VERSION "HNNBNNNYNNNNNNNNNNNNNNNNNNNNNNNNNNNNNNNNNN/4/%%%/4/'%**4NNN///"

NS_ :

BS_:

BU_: BAP_Tester BedienDisp_vo BedienSG_hi CGS DDA Gateway Gateway_PAG GurtMikrofon OTA_FC ZR_High ZR_LIMU ZR_MIB_TOP_ab_Gen3 ZR_Standard

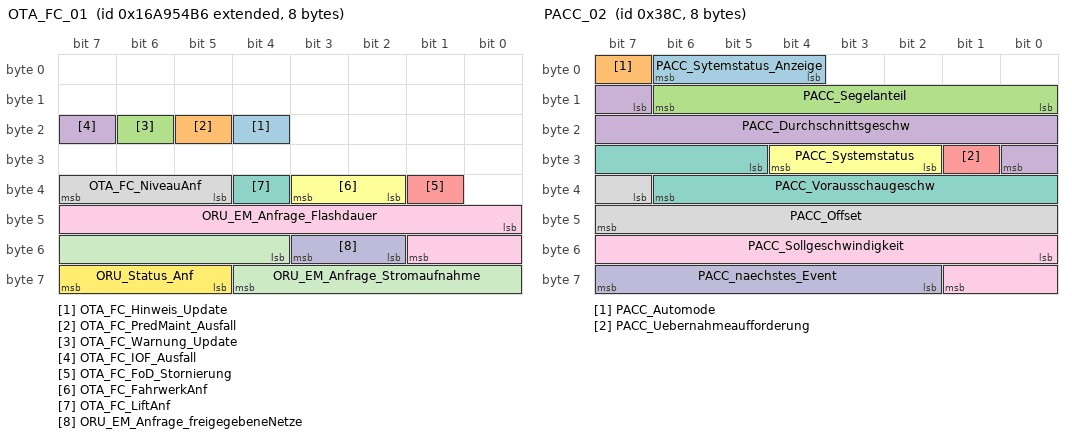
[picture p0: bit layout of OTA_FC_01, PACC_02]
BO_ 2527679670 OTA_FC_01: 8 ZR_MIB_TOP_ab_Gen3
 SG_ OTA_FC_Hinweis_Update : 20|1@1+ (1.0,0.0) [0.0|1] ""  Gateway,Gateway_PAG
 SG_ OTA_FC_PredMaint_Ausfall : 21|1@1+ (1.0,0.0) [0.0|1] ""  Gateway,Gateway_PAG
 SG_ OTA_FC_Warnung_Update : 22|1@1+ (1.0,0.0) [0.0|1] ""  Gateway,Gateway_PAG
 SG_ OTA_FC_IOF_Ausfall : 23|1@1+ (1.0,0.0) [0.0|1] ""  Gateway,Gateway_PAG
 SG_ OTA_FC_FoD_Stornierung : 33|1@1+ (1.0,0.0) [0.0|1] ""  Gateway,Gateway_PAG
 SG_ OTA_FC_FahrwerkAnf : 34|2@1+ (1.0,0.0) [0.0|3] ""  Gateway,Gateway_PAG
 SG_ OTA_FC_LiftAnf : 36|1@1+ (1.0,0.0) [0.0|1] ""  Gateway,Gateway_PAG
 SG_ OTA_FC_NiveauAnf : 37|3@1+ (1.0,0.0) [0.0|7] ""  Gateway,Gateway_PAG
 SG_ ORU_EM_Anfrage_Flashdauer : 40|10@1+ (10,0) [0|10230] "Unit_Secon"  Gateway,Gateway_PAG
 SG_ ORU_EM_Anfrage_freigegebeneNetze : 50|2@1+ (1.0,0.0) [0.0|3] ""  Gateway,Gateway_PAG
 SG_ ORU_EM_Anfrage_Stromaufnahme : 52|9@1+ (0.1,0) [0.0|51.1] "Unit_Amper"  Gateway,Gateway_PAG
 SG_ ORU_Status_Anf : 61|3@1+ (1.0,0.0) [0.0|7] ""  Gateway,Gateway_PAG

BO_ 908 PACC_02: 8 Gateway
 SG_ PACC_Sytemstatus_Anzeige : 4|3@1+ (1.0,0.0) [0.0|7] ""  Vector__XXX
 SG_ PACC_Automode : 7|1@1+ (1.0,0.0) [0.0|1] ""  Vector__XXX
 SG_ PACC_Segelanteil : 8|7@1+ (1,0) [1|100] "Unit_PerCent"  ZR_High
 SG_ PACC_Durchschnittsgeschw : 15|10@1+ (0.3,0) [0.3|306.9] "Unit_KiloMeterPerHour"  ZR_High
 SG_ PACC_Uebernahmeaufforderung : 25|1@1+ (1.0,0.0) [0.0|1] ""  ZR_High
 SG_ PACC_Systemstatus : 26|3@1+ (1.0,0.0) [0.0|7] ""  ZR_High,ZR_Standard
 SG_ PACC_Vorausschaugeschw : 29|10@1+ (0.32,0) [0.00|327.04] "Unit_KiloMeterPerHour"  ZR_High
 SG_ PACC_Offset : 39|9@1+ (1,-255) [-255|256] "Unit_KiloMeterPerHour"  ZR_High
 SG_ PACC_Sollgeschwindigkeit : 48|10@1+ (0.32,0) [0.00|327.04] "Unit_KiloMeterPerHour"  ZR_High
 SG_ PACC_naechstes_Event : 58|6@1+ (1.0,0.0) [0.0|63] ""  ZR_High

BO_ 233 Parken_SM_01: 8 Gateway
 SG_ Parken_Hindernis_Bereich : 0|4@1+ (1.0,0.0) [0.0|15] ""  DDA
 SG_ Parken_SM_Sensor : 5|1@1+ (1.0,0.0) [0.0|1] ""  DDA
 SG_ Parken_SM_Stillstand : 6|1@1+ (1.0,0.0) [0.0|1] ""  DDA
 SG_ Parken_SM_Schluessel : 7|1@1+ (1.0,0.0) [0.0|1] ""  DDA
 SG_ Parken_SM_Tueren : 8|1@1+ (1.0,0.0) [0.0|1] ""  DDA
 SG_ Parken_SM_Anhaenger : 9|1@1+ (1.0,0.0) [0.0|1] ""  DDA
 SG_ Parken_SM_Fahrbereitschaft : 10|1@1+ (1.0,0.0) [0.0|1] ""  DDA
 SG_ Parken_SM_Fahrstufe : 11|1@1+ (1.0,0.0) [0.0|1] ""  DDA
 SG_ Parken_Anhaltegrund_ext : 12|6@1+ (1.0,0.0) [0.0|63] ""  DDA
 SG_ Parken_Touchdiagnose_Anf : 18|1@1+ (1.0,0.0) [0.0|1] ""  DDA
 SG_ Parken_BT_Wunsch : 19|1@1+ (1.0,0.0) [0.0|1] ""  DDA
 SG_ Parken_Hindernis_erkannt : 20|1@1+ (1.0,0.0) [0.0|1] ""  DDA,ZR_High
 SG_ Parken_Fortschrittszaehler : 21|7@1+ (1,0) [0|100] "Unit_PerCent"  DDA,ZR_High
 SG_ Parken_Anhaltegrund : 28|4@1+ (1.0,0.0) [0.0|15] ""  DDA,ZR_High
 SG_ Parken_Fahrtaster_Empfehlung : 32|2@1+ (1.0,0.0) [0.0|3] ""  DDA,ZR_High
 SG_ Parken_Aktives_Bedienelement : 34|2@1+ (1.0,0.0) [0.0|3] ""  DDA,ZR_High
 SG_ Parken_FFB_Status : 36|3@1+ (1.0,0.0) [0.0|7] ""  DDA,ZR_High
 SG_ Parken_Reversieren_moeglich : 39|1@1+ (1.0,0.0) [0.0|1] ""  DDA,ZR_High
 SG_ Parken_Seite : 40|3@1+ (1.0,0.0) [0.0|7] ""  DDA,ZR_High
 SG_ Parken_Seite_Aktiv : 43|2@1+ (1.0,0.0) [0.0|3] ""  DDA,ZR_High
 SG_ Parken_Szenario_Aktiv : 45|3@1+ (1.0,0.0) [0.0|7] ""  DDA,ZR_High
 SG_ Parken_Manoever_Aktiv : 48|2@1+ (1.0,0.0) [0.0|3] ""  DDA,ZR_High
 SG_ Parken_Manoever : 50|2@1+ (1.0,0.0) [0.0|3] ""  DDA,ZR_High
 SG_ Parken_Szenario : 52|4@1+ (1.0,0.0) [0.0|15] ""  DDA,ZR_High
 SG_ Parken_Funktionsstatus : 56|4@1+ (1.0,0.0) [0.0|15] ""  DDA,ZR_High
 SG_ Parken_Richtung : 60|2@1+ (1.0,0.0) [0.0|3] ""  DDA,ZR_High
 SG_ Parken_Richtung_Aktiv : 62|2@1+ (1.0,0.0) [0.0|3] ""  DDA,ZR_High

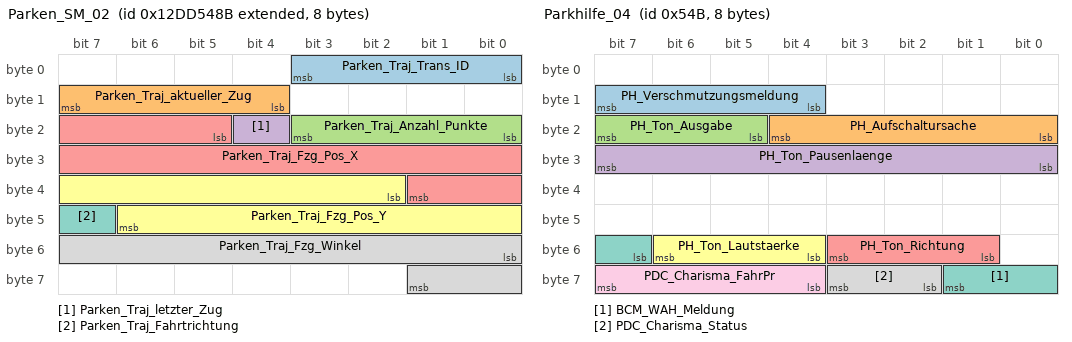
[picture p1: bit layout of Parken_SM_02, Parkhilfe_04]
BO_ 2463978635 Parken_SM_02: 8 Gateway
 SG_ Parken_Traj_Trans_ID : 0|4@1+ (1.0,0.0) [0.0|15] ""  DDA
 SG_ Parken_Traj_aktueller_Zug : 12|4@1+ (1.0,0.0) [0.0|15] ""  DDA
 SG_ Parken_Traj_Anzahl_Punkte : 16|4@1+ (1.0,0.0) [0.0|15] ""  DDA
 SG_ Parken_Traj_letzter_Zug : 20|1@1+ (1.0,0.0) [0.0|1] ""  DDA
 SG_ Parken_Traj_Fzg_Pos_X : 21|13@1+ (0.5,-2047.5) [-2047.5|2048.0] "Unit_Centimeter"  DDA
 SG_ Parken_Traj_Fzg_Pos_Y : 34|13@1+ (0.5,-2047.5) [-2047.5|2048.0] "Unit_Centimeter"  DDA
 SG_ Parken_Traj_Fahrtrichtung : 47|1@1+ (1.0,0.0) [0.0|1] ""  DDA
 SG_ Parken_Traj_Fzg_Winkel : 48|10@1+ (0.3515625,0) [0E-7|359.6484375] "Unit_DegreOfArc"  DDA

BO_ 850 Parken_SM_03: 8 Gateway
 SG_ Parken_SM_03_MUX M  : 0|3@1+ (1.0,0.0) [0.0|7] ""  DDA
 SG_ Parken_SM_03_Traj_Trans_ID_00 m0  : 3|4@1+ (1.0,0.0) [0.0|15] ""  DDA
 SG_ Parken_SM_03_Traj_Trans_ID_01 m1  : 3|4@1+ (1.0,0.0) [0.0|15] ""  DDA
 SG_ Parken_SM_03_Traj_Trans_ID_02 m2  : 3|4@1+ (1.0,0.0) [0.0|15] ""  DDA
 SG_ Parken_SM_03_Traj_Trans_ID_03 m3  : 3|4@1+ (1.0,0.0) [0.0|15] ""  DDA
 SG_ Parken_SM_03_Traj_Trans_ID_04 m4  : 3|4@1+ (1.0,0.0) [0.0|15] ""  DDA
 SG_ Parken_SM_03_Traj_Trans_ID_05 m5  : 3|4@1+ (1.0,0.0) [0.0|15] ""  DDA
 SG_ Parken_SM_03_Traj_Trans_ID_06 m6  : 3|4@1+ (1.0,0.0) [0.0|15] ""  DDA
 SG_ Parken_Traj_P1_Pos_X m0  : 7|13@1+ (0.5,-2047.5) [-2047.5|2048.0] "Unit_Centimeter"  DDA
 SG_ Parken_Traj_P2_Pos_Y m1  : 7|13@1+ (0.5,-2047.5) [-2047.5|2048.0] "Unit_Centimeter"  DDA
 SG_ Parken_Traj_P3_Tangent m2  : 7|10@1+ (0.3515625,0) [0E-7|359.6484375] "Unit_DegreOfArc"  DDA
 SG_ Parken_Traj_P5_Pos_X m3  : 7|13@1+ (0.5,-2047.5) [-2047.5|2048.0] "Unit_Centimeter"  DDA
 SG_ Parken_Traj_P6_Pos_Y m4  : 7|13@1+ (0.5,-2047.5) [-2047.5|2048.0] "Unit_Centimeter"  DDA
 SG_ Parken_Traj_P7_Tangent m5  : 7|10@1+ (0.3515625,0) [0E-7|359.6484375] "Unit_DegreOfArc"  DDA
 SG_ Parken_Traj_P9_Pos_X m6  : 7|13@1+ (0.5,-2047.5) [-2047.5|2048.0] "Unit_Centimeter"  DDA
 SG_ Parken_Traj_P4_Pos_X m2  : 17|13@1+ (0.5,-2047.5) [-2047.5|2048.0] "Unit_Centimeter"  DDA
 SG_ Parken_Traj_P8_Pos_X m5  : 17|13@1+ (0.5,-2047.5) [-2047.5|2048.0] "Unit_Centimeter"  DDA
 SG_ Parken_Traj_P1_Pos_Y m0  : 20|13@1+ (0.5,-2047.5) [-2047.5|2048.0] "Unit_Centimeter"  DDA
 SG_ Parken_Traj_P2_Tangent m1  : 20|10@1+ (0.3515625,0) [0E-7|359.6484375] "Unit_DegreOfArc"  DDA
 SG_ Parken_Traj_P5_Pos_Y m3  : 20|13@1+ (0.5,-2047.5) [-2047.5|2048.0] "Unit_Centimeter"  DDA
 SG_ Parken_Traj_P6_Tangent m4  : 20|10@1+ (0.3515625,0) [0E-7|359.6484375] "Unit_DegreOfArc"  DDA
 SG_ Parken_Traj_P9_Pos_Y m6  : 20|13@1+ (0.5,-2047.5) [-2047.5|2048.0] "Unit_Centimeter"  DDA
 SG_ Parken_Traj_P3_Pos_X m1  : 30|13@1+ (0.5,-2047.5) [-2047.5|2048.0] "Unit_Centimeter"  DDA
 SG_ Parken_Traj_P4_Pos_Y m2  : 30|13@1+ (0.5,-2047.5) [-2047.5|2048.0] "Unit_Centimeter"  DDA
 SG_ Parken_Traj_P7_Pos_X m4  : 30|13@1+ (0.5,-2047.5) [-2047.5|2048.0] "Unit_Centimeter"  DDA
 SG_ Parken_Traj_P8_Pos_Y m5  : 30|13@1+ (0.5,-2047.5) [-2047.5|2048.0] "Unit_Centimeter"  DDA
 SG_ Parken_Traj_P1_Tangent m0  : 33|10@1+ (0.3515625,0) [0E-7|359.6484375] "Unit_DegreOfArc"  DDA
 SG_ Parken_Traj_P5_Tangent m3  : 33|10@1+ (0.3515625,0) [0E-7|359.6484375] "Unit_DegreOfArc"  DDA
 SG_ Parken_Traj_P9_Tangent m6  : 33|10@1+ (0.3515625,0) [0E-7|359.6484375] "Unit_DegreOfArc"  DDA
 SG_ Parken_Traj_P2_Pos_X m0  : 43|13@1+ (0.5,-2047.5) [-2047.5|2048.0] "Unit_Centimeter"  DDA
 SG_ Parken_Traj_P3_Pos_Y m1  : 43|13@1+ (0.5,-2047.5) [-2047.5|2048.0] "Unit_Centimeter"  DDA
 SG_ Parken_Traj_P4_Tangent m2  : 43|10@1+ (0.3515625,0) [0E-7|359.6484375] "Unit_DegreOfArc"  DDA
 SG_ Parken_Traj_P6_Pos_X m3  : 43|13@1+ (0.5,-2047.5) [-2047.5|2048.0] "Unit_Centimeter"  DDA
 SG_ Parken_Traj_P7_Pos_Y m4  : 43|13@1+ (0.5,-2047.5) [-2047.5|2048.0] "Unit_Centimeter"  DDA
 SG_ Parken_Traj_P8_Tangent m5  : 43|10@1+ (0.3515625,0) [0E-7|359.6484375] "Unit_DegreOfArc"  DDA

BO_ 872 Parkhilfe2_01: 8 Gateway
 SG_ PH2_Visualisierung : 0|3@1+ (1.0,0.0) [0.0|7] ""  Vector__XXX
 SG_ PDC2_Tonausgabe_Front : 4|4@1+ (1.0,0.0) [0.0|15] ""  Vector__XXX
 SG_ PDC2_Tonausgabe_Heck : 8|4@1+ (1.0,0.0) [0.0|15] ""  Vector__XXX
 SG_ PH2_nachtr_Stopp_An : 12|1@1+ (1.0,0.0) [0.0|1] ""  Vector__XXX
 SG_ PH2_Abschaltursache : 13|3@1+ (1.0,0.0) [0.0|7] ""  Vector__XXX
 SG_ PH2_Opt_Anzeige_V_ein : 16|1@1+ (1.0,0.0) [0.0|1] ""  Vector__XXX
 SG_ PH2_Opt_Anzeige_H_ein : 17|1@1+ (1.0,0.0) [0.0|1] ""  Vector__XXX
 SG_ PH2_Opt_Anz_V_Hindernis : 18|1@1+ (1.0,0.0) [0.0|1] ""  Vector__XXX
 SG_ PH2_Opt_Anz_H_Hindernis : 19|1@1+ (1.0,0.0) [0.0|1] ""  Vector__XXX
 SG_ PH2_Tongeber_V_aktiv : 20|1@1+ (1.0,0.0) [0.0|1] ""  Vector__XXX
 SG_ PH2_Tongeber_H_aktiv : 21|1@1+ (1.0,0.0) [0.0|1] ""  Vector__XXX
 SG_ PH2_Tongeber_mute : 22|1@1+ (1.0,0.0) [0.0|1] ""  Vector__XXX
 SG_ PH2_Anf_Audioabsenkung : 23|1@1+ (1.0,0.0) [0.0|1] ""  ZR_High,ZR_LIMU,ZR_MIB_TOP_ab_Gen3,ZR_Standard
 SG_ PH2_Tongeber_H_verfuegbar : 24|1@1+ (1.0,0.0) [0.0|1] ""  Vector__XXX
 SG_ PH2_Taster : 28|2@1+ (1.0,0.0) [0.0|3] ""  Vector__XXX
 SG_ PH2_Anf_Verdeck : 30|2@1+ (1.0,0.0) [0.0|3] ""  Vector__XXX
 SG_ PH2_Frequenz_hinten : 32|4@1+ (1,0) [0|15] ""  Vector__XXX
 SG_ PH2_Lautstaerke_hinten : 36|4@1+ (1,0) [0|15] ""  Vector__XXX
 SG_ PH2_Frequenz_vorn : 40|4@1+ (1,0) [0|15] ""  Vector__XXX
 SG_ PH2_Lautstaerke_vorn : 44|4@1+ (1,0) [0|15] ""  Vector__XXX
 SG_ PH2_StartStopp_Info : 49|2@1+ (1.0,0.0) [0.0|3] ""  Vector__XXX
 SG_ PH2_Stoermeldung : 52|4@1+ (1.0,0.0) [0.0|15] ""  Vector__XXX
 SG_ PH2_defekt : 56|1@1+ (1.0,0.0) [0.0|1] ""  Vector__XXX
 SG_ PH2_gestoert : 57|1@1+ (1.0,0.0) [0.0|1] ""  Vector__XXX
 SG_ PH2_Systemzustand : 58|3@1+ (1.0,0.0) [0.0|7] ""  Vector__XXX
 SG_ PH2_Display_Kundenwunsch : 61|2@1+ (1.0,0.0) [0.0|3] ""  Vector__XXX

BO_ 1175 Parkhilfe_01: 8 Gateway
 SG_ PH_Visualisierung : 0|3@1+ (1.0,0.0) [0.0|7] ""  Vector__XXX
 SG_ PDC_Tonausgabe_Front : 4|4@1+ (1.0,0.0) [0.0|15] ""  Vector__XXX
 SG_ PDC_Tonausgabe_Heck : 8|4@1+ (1.0,0.0) [0.0|15] ""  Vector__XXX
 SG_ PH_nachtr_Stopp_Anf : 12|1@1+ (1.0,0.0) [0.0|1] ""  Vector__XXX
 SG_ PH_Abschaltursache : 13|3@1+ (1.0,0.0) [0.0|7] ""  ZR_High
 SG_ PH_Opt_Anzeige_V_ein : 16|1@1+ (1.0,0.0) [0.0|1] ""  Vector__XXX
 SG_ PH_Opt_Anzeige_H_ein : 17|1@1+ (1.0,0.0) [0.0|1] ""  Vector__XXX
 SG_ PH_Opt_Anz_V_Hindernis : 18|1@1+ (1.0,0.0) [0.0|1] ""  Vector__XXX
 SG_ PH_Opt_Anz_H_Hindernis : 19|1@1+ (1.0,0.0) [0.0|1] ""  Vector__XXX
 SG_ PH_Tongeber_V_aktiv : 20|1@1+ (1.0,0.0) [0.0|1] ""  Vector__XXX
 SG_ PH_Tongeber_H_aktiv : 21|1@1+ (1.0,0.0) [0.0|1] ""  Vector__XXX
 SG_ PH_Tongeber_mute : 22|1@1+ (1.0,0.0) [0.0|1] ""  Vector__XXX
 SG_ PH_Anf_Audioabsenkung : 23|1@1+ (1.0,0.0) [0.0|1] ""  ZR_High,ZR_LIMU,ZR_MIB_TOP_ab_Gen3,ZR_Standard
 SG_ PH_Tongeber_H_verfuegbar : 24|1@1+ (1.0,0.0) [0.0|1] ""  ZR_High
 SG_ PLA_Anf_Aufschaltung_RVC : 25|1@1+ (1.0,0.0) [0.0|1] ""  Vector__XXX
 SG_ PH_Taster : 28|2@1+ (1.0,0.0) [0.0|3] ""  ZR_High
 SG_ PH_Anf_Verdeck : 30|2@1+ (1.0,0.0) [0.0|3] ""  ZR_High
 SG_ PH_Frequenz_hinten : 32|4@1+ (1,0) [0|15] ""  Vector__XXX
 SG_ PH_Lautstaerke_hinten : 36|4@1+ (1,0) [0|15] ""  Vector__XXX
 SG_ PH_Frequenz_vorn : 40|4@1+ (1,0) [0|15] ""  Vector__XXX
 SG_ PH_Lautstaerke_vorn : 44|4@1+ (1,0) [0|15] ""  Vector__XXX
 SG_ PH_StartStopp_Info : 49|2@1+ (1.0,0.0) [0.0|3] ""  ZR_High
 SG_ PH_Stoermeldung : 52|4@1+ (1.0,0.0) [0.0|15] ""  Vector__XXX
 SG_ PH_defekt : 56|1@1+ (1.0,0.0) [0.0|1] ""  ZR_High
 SG_ PH_gestoert : 57|1@1+ (1.0,0.0) [0.0|1] ""  ZR_High
 SG_ PH_Systemzustand : 58|3@1+ (1.0,0.0) [0.0|7] ""  Vector__XXX
 SG_ PH_Display_Kundenwunsch : 61|2@1+ (1.0,0.0) [0.0|3] ""  ZR_High

BO_ 1355 Parkhilfe_04: 8 Gateway
 SG_ PH_Verschmutzungsmeldung : 12|4@1+ (1.0,0.0) [0.0|15] ""  Vector__XXX
 SG_ PH_Aufschaltursache : 16|5@1+ (1.0,0.0) [0.0|31] ""  Vector__XXX
 SG_ PH_Ton_Ausgabe : 21|3@1+ (1.0,0.0) [0.0|7] ""  ZR_LIMU,ZR_MIB_TOP_ab_Gen3
 SG_ PH_Ton_Pausenlaenge : 24|8@1+ (1.0,0.0) [0.0|255] ""  ZR_LIMU,ZR_MIB_TOP_ab_Gen3
 SG_ PH_Ton_Richtung : 49|3@1+ (1.0,0.0) [0.0|7] ""  ZR_LIMU,ZR_MIB_TOP_ab_Gen3
 SG_ PH_Ton_Lautstaerke : 52|3@1+ (1.0,0.0) [0.0|7] ""  ZR_LIMU,ZR_MIB_TOP_ab_Gen3
 SG_ BCM_WAH_Meldung : 55|3@1+ (1.0,0.0) [0.0|7] ""  Vector__XXX
 SG_ PDC_Charisma_Status : 58|2@1+ (1.0,0.0) [0.0|3] ""  Vector__XXX
 SG_ PDC_Charisma_FahrPr : 60|4@1+ (1.0,0.0) [0.0|15] ""  Vector__XXX

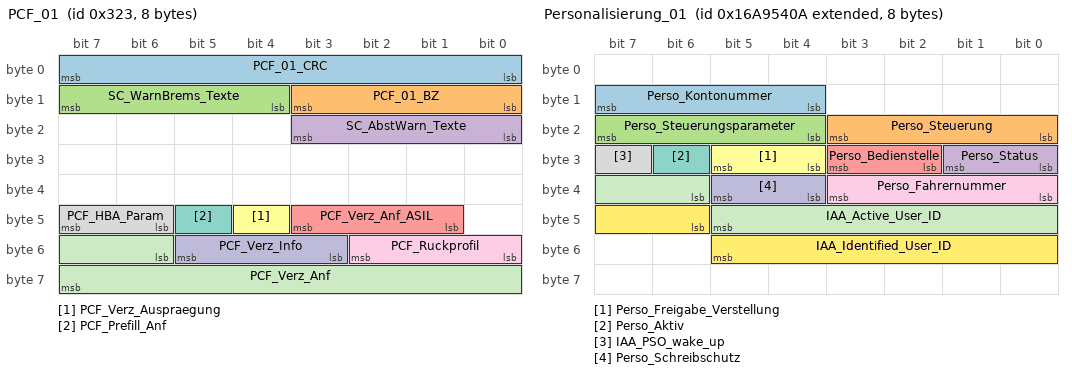
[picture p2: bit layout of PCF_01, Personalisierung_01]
BO_ 803 PCF_01: 8 Gateway
 SG_ PCF_01_CRC : 0|8@1+ (1,0) [0|255] ""  Vector__XXX
 SG_ PCF_01_BZ : 8|4@1+ (1,0) [0|15] ""  Vector__XXX
 SG_ SC_WarnBrems_Texte : 12|4@1+ (1.0,0.0) [0.0|15] ""  ZR_High
 SG_ SC_AbstWarn_Texte : 16|4@1+ (1.0,0.0) [0.0|15] ""  ZR_High
 SG_ PCF_Verz_Anf_ASIL : 41|3@1+ (1.0,0.0) [0.0|7] ""  Vector__XXX
 SG_ PCF_Verz_Auspraegung : 44|1@1+ (1.0,0.0) [0.0|1] ""  Vector__XXX
 SG_ PCF_Prefill_Anf : 45|1@1+ (1.0,0.0) [0.0|1] ""  Vector__XXX
 SG_ PCF_HBA_Param : 46|2@1+ (1.0,0.0) [0.0|3] ""  Vector__XXX
 SG_ PCF_Ruckprofil : 48|3@1+ (1.0,0.0) [0.0|7] ""  Vector__XXX
 SG_ PCF_Verz_Info : 51|3@1+ (1.0,0.0) [0.0|7] ""  Vector__XXX
 SG_ PCF_Verz_Anf : 54|10@1+ (0.024,-20.016) [-20.016|4.536] "Unit_MeterPerSeconSquar"  Vector__XXX

BO_ 2527679498 Personalisierung_01: 8 Gateway
 SG_ Perso_Kontonummer : 12|4@1+ (1.0,0.0) [0.0|15] ""  OTA_FC,ZR_High,ZR_LIMU,ZR_MIB_TOP_ab_Gen3,ZR_Standard
 SG_ Perso_Steuerung : 16|4@1+ (1.0,0.0) [0.0|15] ""  OTA_FC,ZR_High,ZR_LIMU,ZR_MIB_TOP_ab_Gen3,ZR_Standard
 SG_ Perso_Steuerungsparameter : 20|4@1+ (1.0,0.0) [0.0|15] ""  OTA_FC,ZR_High,ZR_LIMU,ZR_MIB_TOP_ab_Gen3,ZR_Standard
 SG_ Perso_Status : 24|2@1+ (1.0,0.0) [0.0|3] ""  OTA_FC,ZR_High,ZR_LIMU,ZR_MIB_TOP_ab_Gen3,ZR_Standard
 SG_ Perso_Bedienstelle : 26|2@1+ (1.0,0.0) [0.0|3] ""  Vector__XXX
 SG_ Perso_Freigabe_Verstellung : 28|2@1+ (1.0,0.0) [0.0|3] ""  ZR_LIMU,ZR_MIB_TOP_ab_Gen3
 SG_ Perso_Aktiv : 30|1@1+ (1.0,0.0) [0.0|1] ""  OTA_FC
 SG_ IAA_PSO_wake_up : 31|1@1+ (1.0,0.0) [0.0|1] ""  ZR_LIMU,ZR_MIB_TOP_ab_Gen3
 SG_ Perso_Fahrernummer : 32|4@1+ (1.0,0.0) [0.0|15] ""  ZR_High,ZR_LIMU,ZR_MIB_TOP_ab_Gen3,ZR_Standard
 SG_ Perso_Schreibschutz : 36|2@1+ (1.0,0.0) [0.0|3] ""  Vector__XXX
 SG_ IAA_Active_User_ID : 38|8@1+ (1,0) [0|255] "Unit_None"  ZR_LIMU,ZR_MIB_TOP_ab_Gen3
 SG_ IAA_Identified_User_ID : 46|8@1+ (1,0) [0|255] "Unit_None"  ZR_LIMU,ZR_MIB_TOP_ab_Gen3

BO_ 2463978756 Personalisierung_03: 8 DDA
 SG_ PSO_last_rec_UserID_Src1 : 60|4@1+ (1.0,0.0) [0.0|15] ""  Gateway,Gateway_PAG

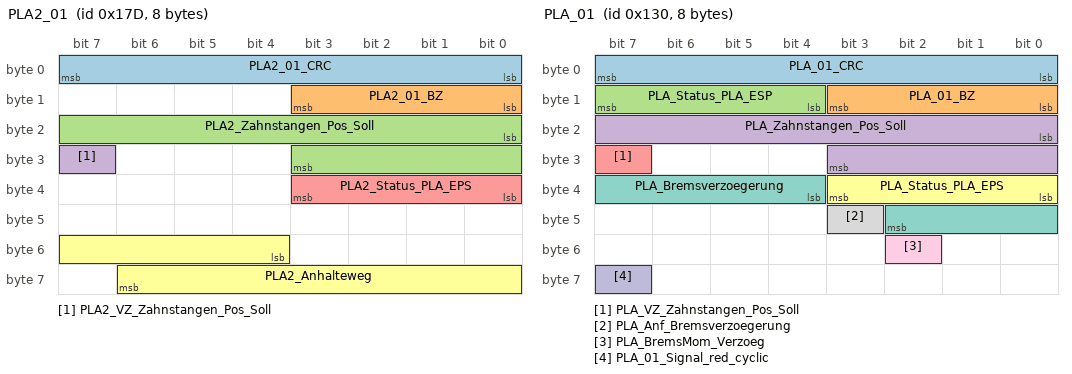
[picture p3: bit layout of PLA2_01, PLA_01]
BO_ 381 PLA2_01: 8 Gateway
 SG_ PLA2_01_CRC : 0|8@1+ (1,0) [0|255] ""  Vector__XXX
 SG_ PLA2_01_BZ : 8|4@1+ (1,0) [0|15] ""  Vector__XXX
 SG_ PLA2_Zahnstangen_Pos_Soll : 16|12@1+ (0.02,0) [0.00|81.86] "Unit_MilliMeter"  Vector__XXX
 SG_ PLA2_VZ_Zahnstangen_Pos_Soll : 31|1@1+ (1.0,0.0) [0.0|1] ""  Vector__XXX
 SG_ PLA2_Status_PLA_EPS : 32|4@1+ (1.0,0.0) [0.0|15] ""  ZR_High
 SG_ PLA2_Anhalteweg : 52|11@1+ (0.01,0) [0.00|20.44] "Unit_Meter"  Vector__XXX

BO_ 304 PLA_01: 8 Gateway
 SG_ PLA_01_CRC : 0|8@1+ (1,0) [0|255] ""  Vector__XXX
 SG_ PLA_01_BZ : 8|4@1+ (1,0) [0|15] ""  Vector__XXX
 SG_ PLA_Status_PLA_ESP : 12|4@1+ (1.0,0.0) [0.0|15] ""  Vector__XXX
 SG_ PLA_Zahnstangen_Pos_Soll : 16|12@1+ (0.02,0) [0.00|81.86] "Unit_MilliMeter"  Vector__XXX
 SG_ PLA_VZ_Zahnstangen_Pos_Soll : 31|1@1+ (1.0,0.0) [0.0|1] ""  Vector__XXX
 SG_ PLA_Status_PLA_EPS : 32|4@1+ (1.0,0.0) [0.0|15] ""  ZR_High
 SG_ PLA_Bremsverzoegerung : 36|7@1+ (0.1,0) [0.0|12.0] "Unit_MeterPerSeconSquar"  Vector__XXX
 SG_ PLA_Anf_Bremsverzoegerung : 43|1@1+ (1.0,0.0) [0.0|1] ""  ZR_High
 SG_ PLA_BremsMom_Verzoeg : 50|1@1+ (1.0,0.0) [0.0|1] ""  Vector__XXX
 SG_ PLA_01_Signal_red_cyclic : 63|1@1+ (1.0,0.0) [0.0|1] ""  Vector__XXX

BO_ 2589283731 PLA_SDA_01: 8 Gateway
 SG_ PLA_SDA_Status : 4|1@1+ (1.0,0.0) [0.0|1] ""  ZR_LIMU,ZR_MIB_TOP_ab_Gen3
 SG_ PLA_SDA_Aktive_Seite : 5|1@1+ (1.0,0.0) [0.0|1] ""  ZR_LIMU,ZR_MIB_TOP_ab_Gen3
 SG_ PLA_SDA_Exist : 6|1@1+ (1.0,0.0) [0.0|1] ""  ZR_LIMU,ZR_MIB_TOP_ab_Gen3
 SG_ PLA_SDA_Laengs_Querluecke : 7|1@1+ (1.0,0.0) [0.0|1] ""  ZR_LIMU,ZR_MIB_TOP_ab_Gen3
 SG_ PLA_SDA_Li_Offset_8 : 8|5@1+ (0.03448,0) [0.00000|0.99992] ""  Vector__XXX
 SG_ PLA_SDA_Li_ID_8 : 13|2@1+ (1.0,0.0) [0.0|3] ""  Vector__XXX
 SG_ PLA_SDA_Li_Offset_7 : 15|5@1+ (0.03448,0) [0.00000|0.99992] ""  Vector__XXX
 SG_ PLA_SDA_Li_ID_7 : 20|2@1+ (1.0,0.0) [0.0|3] ""  Vector__XXX
 SG_ PLA_SDA_Li_Offset_6 : 22|5@1+ (0.03448,0) [0.00000|0.99992] ""  Vector__XXX
 SG_ PLA_SDA_Li_ID_6 : 27|2@1+ (1.0,0.0) [0.0|3] ""  Vector__XXX
 SG_ PLA_SDA_Li_Offset_5 : 29|5@1+ (0.03448,0) [0.00000|0.99992] ""  Vector__XXX
 SG_ PLA_SDA_Li_ID_5 : 34|2@1+ (1.0,0.0) [0.0|3] ""  Vector__XXX
 SG_ PLA_SDA_Li_Offset_4 : 36|5@1+ (0.03448,0) [0.00000|0.99992] ""  Vector__XXX
 SG_ PLA_SDA_Li_ID_4 : 41|2@1+ (1.0,0.0) [0.0|3] ""  Vector__XXX
 SG_ PLA_SDA_Li_Offset_3 : 43|5@1+ (0.03448,0) [0.00000|0.99992] ""  Vector__XXX
 SG_ PLA_SDA_Li_ID_3 : 48|2@1+ (1.0,0.0) [0.0|3] ""  Vector__XXX
 SG_ PLA_SDA_Li_Offset_2 : 50|5@1+ (0.03448,0) [0.00000|0.99992] ""  Vector__XXX
 SG_ PLA_SDA_Li_ID_2 : 55|2@1+ (1.0,0.0) [0.0|3] ""  Vector__XXX
 SG_ PLA_SDA_Li_Offset_1 : 57|5@1+ (0.03448,0) [0.00000|0.99992] ""  Vector__XXX
 SG_ PLA_SDA_Li_ID_1 : 62|2@1+ (1.0,0.0) [0.0|3] ""  Vector__XXX

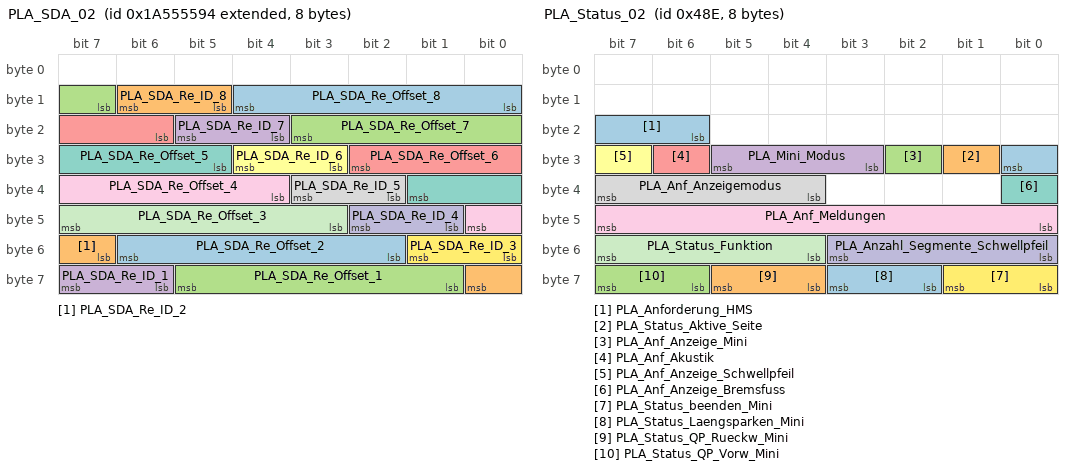
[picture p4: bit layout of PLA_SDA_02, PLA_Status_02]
BO_ 2589283732 PLA_SDA_02: 8 Gateway
 SG_ PLA_SDA_Re_Offset_8 : 8|5@1+ (0.03448,0) [0.00000|0.99992] ""  ZR_LIMU,ZR_MIB_TOP_ab_Gen3
 SG_ PLA_SDA_Re_ID_8 : 13|2@1+ (1.0,0.0) [0.0|3] ""  ZR_LIMU,ZR_MIB_TOP_ab_Gen3
 SG_ PLA_SDA_Re_Offset_7 : 15|5@1+ (0.03448,0) [0.00000|0.99992] ""  ZR_LIMU,ZR_MIB_TOP_ab_Gen3
 SG_ PLA_SDA_Re_ID_7 : 20|2@1+ (1.0,0.0) [0.0|3] ""  ZR_LIMU,ZR_MIB_TOP_ab_Gen3
 SG_ PLA_SDA_Re_Offset_6 : 22|5@1+ (0.03448,0) [0.00000|0.99992] ""  ZR_LIMU,ZR_MIB_TOP_ab_Gen3
 SG_ PLA_SDA_Re_ID_6 : 27|2@1+ (1.0,0.0) [0.0|3] ""  ZR_LIMU,ZR_MIB_TOP_ab_Gen3
 SG_ PLA_SDA_Re_Offset_5 : 29|5@1+ (0.03448,0) [0.00000|0.99992] ""  ZR_LIMU,ZR_MIB_TOP_ab_Gen3
 SG_ PLA_SDA_Re_ID_5 : 34|2@1+ (1.0,0.0) [0.0|3] ""  ZR_LIMU,ZR_MIB_TOP_ab_Gen3
 SG_ PLA_SDA_Re_Offset_4 : 36|5@1+ (0.03448,0) [0.00000|0.99992] ""  ZR_LIMU,ZR_MIB_TOP_ab_Gen3
 SG_ PLA_SDA_Re_ID_4 : 41|2@1+ (1.0,0.0) [0.0|3] ""  ZR_LIMU,ZR_MIB_TOP_ab_Gen3
 SG_ PLA_SDA_Re_Offset_3 : 43|5@1+ (0.03448,0) [0.00000|0.99992] ""  ZR_LIMU,ZR_MIB_TOP_ab_Gen3
 SG_ PLA_SDA_Re_ID_3 : 48|2@1+ (1.0,0.0) [0.0|3] ""  ZR_LIMU,ZR_MIB_TOP_ab_Gen3
 SG_ PLA_SDA_Re_Offset_2 : 50|5@1+ (0.03448,0) [0.00000|0.99992] ""  ZR_LIMU,ZR_MIB_TOP_ab_Gen3
 SG_ PLA_SDA_Re_ID_2 : 55|2@1+ (1.0,0.0) [0.0|3] ""  ZR_LIMU,ZR_MIB_TOP_ab_Gen3
 SG_ PLA_SDA_Re_Offset_1 : 57|5@1+ (0.03448,0) [0.00000|0.99992] ""  ZR_LIMU,ZR_MIB_TOP_ab_Gen3
 SG_ PLA_SDA_Re_ID_1 : 62|2@1+ (1.0,0.0) [0.0|3] ""  ZR_LIMU,ZR_MIB_TOP_ab_Gen3

BO_ 1166 PLA_Status_02: 8 Gateway
 SG_ PLA_Anforderung_HMS : 22|3@1+ (1.0,0.0) [0.0|7] ""  Vector__XXX
 SG_ PLA_Status_Aktive_Seite : 25|1@1+ (1.0,0.0) [0.0|1] ""  ZR_High
 SG_ PLA_Anf_Anzeige_Mini : 26|1@1+ (1.0,0.0) [0.0|1] ""  ZR_High
 SG_ PLA_Mini_Modus : 27|3@1+ (1.0,0.0) [0.0|7] ""  ZR_High
 SG_ PLA_Anf_Akustik : 30|1@1+ (1.0,0.0) [0.0|1] ""  Vector__XXX
 SG_ PLA_Anf_Anzeige_Schwellpfeil : 31|1@1+ (1.0,0.0) [0.0|1] ""  ZR_High
 SG_ PLA_Anf_Anzeige_Bremsfuss : 32|1@1+ (1.0,0.0) [0.0|1] ""  ZR_High
 SG_ PLA_Anf_Anzeigemodus : 36|4@1+ (1.0,0.0) [0.0|15] ""  ZR_High
 SG_ PLA_Anf_Meldungen : 40|8@1+ (1.0,0.0) [0.0|255] ""  Vector__XXX
 SG_ PLA_Anzahl_Segmente_Schwellpfeil : 48|4@1+ (1,0) [0|15] "Unit_None"  Vector__XXX
 SG_ PLA_Status_Funktion : 52|4@1+ (1.0,0.0) [0.0|15] ""  ZR_High
 SG_ PLA_Status_beenden_Mini : 56|2@1+ (1.0,0.0) [0.0|3] ""  Vector__XXX
 SG_ PLA_Status_Laengsparken_Mini : 58|2@1+ (1.0,0.0) [0.0|3] ""  Vector__XXX
 SG_ PLA_Status_QP_Rueckw_Mini : 60|2@1+ (1.0,0.0) [0.0|3] ""  Vector__XXX
 SG_ PLA_Status_QP_Vorw_Mini : 62|2@1+ (1.0,0.0) [0.0|3] ""  Vector__XXX

BO_ 1122 PSD_04: 8 ZR_High
 SG_ PSD_Segment_ID : 0|6@1+ (1,0) [2|63] ""  Gateway,Gateway_PAG
 SG_ PSD_Vorgaenger_Segment_ID : 6|6@1+ (1,0) [2|63] ""  Gateway,Gateway_PAG
 SG_ PSD_Segmentlaenge : 12|7@1+ (2,0) [0|254] "Unit_Meter"  Gateway,Gateway_PAG
 SG_ PSD_Strassenkategorie : 19|3@1+ (1.0,0.0) [0.0|7] ""  Gateway,Gateway_PAG,OTA_FC
 SG_ PSD_Endkruemmung : 22|8@1+ (1,0) [0|254] "Unit_None"  Gateway,Gateway_PAG
 SG_ PSD_Endkruemmung_Vorz : 30|1@1+ (1.0,0.0) [0.0|1] ""  Gateway,Gateway_PAG
 SG_ PSD_Idenditaets_ID : 31|6@1+ (1,0) [2|63] ""  Gateway,Gateway_PAG
 SG_ PSD_ADAS_Qualitaet : 37|1@1+ (1.0,0.0) [0.0|1] ""  Gateway,Gateway_PAG
 SG_ PSD_wahrscheinlichster_Pfad : 38|1@1+ (1.0,0.0) [0.0|1] ""  Gateway,Gateway_PAG
 SG_ PSD_Geradester_Pfad : 39|1@1+ (1.0,0.0) [0.0|1] ""  Gateway,Gateway_PAG
 SG_ PSD_Fahrspuren_Anzahl : 40|3@1+ (1.0,0.0) [0.0|7] ""  Gateway,Gateway_PAG
 SG_ PSD_Bebauung : 43|1@1+ (1.0,0.0) [0.0|1] ""  Gateway,Gateway_PAG
 SG_ PSD_Segment_Komplett : 44|1@1+ (1.0,0.0) [0.0|1] ""  Gateway,Gateway_PAG
 SG_ PSD_Rampe : 45|2@1+ (1.0,0.0) [0.0|3] ""  Gateway,Gateway_PAG
 SG_ PSD_Anfangskruemmung : 47|8@1+ (1,0) [0|254] ""  Gateway,Gateway_PAG
 SG_ PSD_Anfangskruemmung_Vorz : 55|1@1+ (1.0,0.0) [0.0|1] ""  Gateway,Gateway_PAG
 SG_ PSD_Abzweigerichtung : 56|1@1+ (1.0,0.0) [0.0|1] ""  Gateway,Gateway_PAG
 SG_ PSD_Abzweigewinkel : 57|7@1+ (1.417323,0) [0.000000|180.000021] ""  Gateway,Gateway_PAG

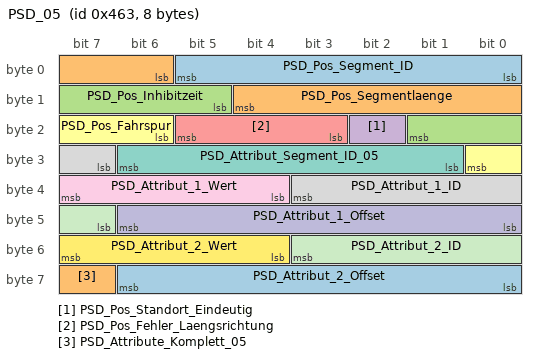
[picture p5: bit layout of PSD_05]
BO_ 1123 PSD_05: 8 ZR_High
 SG_ PSD_Pos_Segment_ID : 0|6@1+ (1,0) [2|63] ""  Gateway,Gateway_PAG
 SG_ PSD_Pos_Segmentlaenge : 6|7@1+ (2,0) [0|254] "Unit_Meter"  Gateway,Gateway_PAG
 SG_ PSD_Pos_Inhibitzeit : 13|5@1+ (10,0) [0|310] "Unit_MilliSecon"  Gateway,Gateway_PAG
 SG_ PSD_Pos_Standort_Eindeutig : 18|1@1+ (1.0,0.0) [0.0|1] ""  Gateway,Gateway_PAG
 SG_ PSD_Pos_Fehler_Laengsrichtung : 19|3@1+ (1.0,0.0) [0.0|7] ""  Gateway,Gateway_PAG
 SG_ PSD_Pos_Fahrspur : 22|3@1+ (1.0,0.0) [0.0|7] ""  Gateway,Gateway_PAG
 SG_ PSD_Attribut_Segment_ID_05 : 25|6@1+ (1,0) [2|63] ""  Gateway,Gateway_PAG
 SG_ PSD_Attribut_1_ID : 31|5@1+ (1,0) [1|31] ""  Gateway,Gateway_PAG
 SG_ PSD_Attribut_1_Wert : 36|4@1+ (1.0,0.0) [0.0|15] ""  Gateway,Gateway_PAG
 SG_ PSD_Attribut_1_Offset : 40|7@1+ (2,0) [0|254] "Unit_Meter"  Gateway,Gateway_PAG
 SG_ PSD_Attribut_2_ID : 47|5@1+ (1,0) [1|31] ""  Gateway,Gateway_PAG
 SG_ PSD_Attribut_2_Wert : 52|4@1+ (1.0,0.0) [0.0|15] ""  Gateway,Gateway_PAG
 SG_ PSD_Attribut_2_Offset : 56|7@1+ (2,0) [0|254] "Unit_Meter"  Gateway,Gateway_PAG
 SG_ PSD_Attribute_Komplett_05 : 63|1@1+ (1.0,0.0) [0.0|1] ""  Gateway,Gateway_PAG

BO_ 1124 PSD_06: 8 ZR_High
 SG_ PSD_06_Mux M  : 0|3@1+ (1.0,0.0) [0.0|7] ""  Gateway,Gateway_PAG
 SG_ PSD_Sys_Segment_ID m0  : 3|6@1+ (1,0) [2|63] ""  Gateway,Gateway_PAG
 SG_ PSD_Attribut_Segment_ID m1  : 3|6@1+ (1,0) [2|63] ""  Gateway,Gateway_PAG
 SG_ PSD_Ges_Segment_ID m2  : 3|6@1+ (1,0) [2|63] ""  Gateway,Gateway_PAG
 SG_ PSD_Baum_Laenge_VZ m3  : 3|1@1+ (1.0,0.0) [0.0|1] ""  Gateway,Gateway_PAG
 SG_ PSD_Steigung_1_Segment_ID m4  : 3|6@1+ (1,0) [2|63] ""  Gateway,Gateway_PAG
 SG_ PSD_Baum_Laenge m3  : 4|25@1+ (0.00001,0) [0.00000|180.00000] "Unit_DegreOfArc"  Gateway,Gateway_PAG
 SG_ PSD_Sys_Laendercode m0  : 9|8@1+ (1.0,0.0) [0.0|255] ""  Gateway,Gateway_PAG
 SG_ PSD_Attribut_3_ID m1  : 9|5@1+ (1,0) [1|31] ""  Gateway,Gateway_PAG
 SG_ PSD_Ges_Offset m2  : 9|7@1+ (2,0) [0|254] "Unit_Meter"  Gateway,Gateway_PAG
 SG_ PSD_Steigung_1_A_Steigung m4  : 9|7@1+ (0.12,0) [0.00|15.00] "Unit_PerCent"  Gateway,Gateway_PAG
 SG_ PSD_Attribut_3_Offset m1  : 14|7@1+ (2,0) [0|254] "Unit_Meter"  Gateway,Gateway_PAG
 SG_ PSD_Ges_Geschwindigkeit m2  : 16|5@1+ (1.0,0.0) [0.0|31] ""  Gateway,Gateway_PAG
 SG_ PSD_Steigung_1_A_Vorz m4  : 16|1@1+ (1.0,0.0) [0.0|1] ""  Gateway,Gateway_PAG
 SG_ PSD_Sys_Geschwindigkeit_Einheit m0  : 17|1@1+ (1.0,0.0) [0.0|1] ""  Gateway,Gateway_PAG
 SG_ PSD_Steigung_1_A_Offset m4  : 17|7@1+ (2,0) [0|254] "Unit_Meter"  Gateway,Gateway_PAG
 SG_ PSD_Sys_Verkehrsrichtung m0  : 18|1@1+ (1.0,0.0) [0.0|1] ""  Gateway,Gateway_PAG
 SG_ PSD_Sys_Geometrieguete m0  : 19|2@1+ (1.0,0.0) [0.0|3] ""  Gateway,Gateway_PAG
 SG_ PSD_Sys_Mapmatchingguete m0  : 21|2@1+ (1.0,0.0) [0.0|3] ""  Gateway,Gateway_PAG
 SG_ PSD_Attribut_3_Wert m1  : 21|4@1+ (1.0,0.0) [0.0|15] ""  Gateway,Gateway_PAG
 SG_ PSD_Ges_Typ m2  : 21|2@1+ (1.0,0.0) [0.0|3] ""  Gateway,Gateway_PAG
 SG_ PSD_Sys_Alter_Karte m0  : 23|3@1+ (1.0,0.0) [0.0|7] ""  Gateway,Gateway_PAG
 SG_ PSD_Ges_Spur_Geschw_Begrenzung m2  : 23|6@1+ (1.0,0.0) [0.0|63] ""  Gateway,Gateway_PAG
 SG_ PSD_Steigung_1_B_Steigung m4  : 24|7@1+ (0.12,0) [0.00|15.00] "Unit_PerCent"  Gateway,Gateway_PAG
 SG_ PSD_Attribut_4_ID m1  : 25|5@1+ (1,0) [1|31] ""  Gateway,Gateway_PAG
 SG_ PSD_Sys_Zielfuehrung m0  : 26|1@1+ (1.0,0.0) [0.0|1] ""  Gateway,Gateway_PAG
 SG_ PSD_Sys_US_State m0  : 27|6@1+ (1.0,0.0) [0.0|63] ""  Gateway,Gateway_PAG
 SG_ PSD_Ges_Geschwindigkeit_Gespann m2  : 29|2@1+ (1.0,0.0) [0.0|3] ""  Gateway,Gateway_PAG
 SG_ PSD_Baum_Breite_VZ m3  : 29|1@1+ (1.0,0.0) [0.0|1] ""  Gateway,Gateway_PAG
 SG_ PSD_Attribut_4_Wert m1  : 30|4@1+ (1,0) [0|15] ""  Gateway,Gateway_PAG
 SG_ PSD_Baum_Breite m3  : 30|24@1+ (0.00001,0) [0.00000|90.00000] "Unit_DegreOfArc"  Gateway,Gateway_PAG
 SG_ PSD_Ges_Geschwindigkeit_Witter m2  : 31|2@1+ (1.0,0.0) [0.0|3] ""  Gateway,Gateway_PAG
 SG_ PSD_Steigung_1_B_Vorz m4  : 31|1@1+ (1.0,0.0) [0.0|1] ""  Gateway,Gateway_PAG
 SG_ PSD_Steigung_1_B_Offset m4  : 32|7@1+ (2,0) [0|254] "Unit_Meter"  Gateway,Gateway_PAG
 SG_ PSD_Sys_Quali_Geometrien m0  : 33|3@1+ (1,0) [0|7] "Unit_None"  Gateway,Gateway_PAG
 SG_ PSD_Ges_Geschwindigkeit_Tag_Anf m2  : 33|3@1+ (1.0,0.0) [0.0|7] ""  Gateway,Gateway_PAG
 SG_ PSD_Attribut_4_Offset m1  : 34|7@1+ (2,0) [0|254] "Unit_Meter"  Gateway,Gateway_PAG
 SG_ PSD_Sys_Quali_Ortsinfo m0  : 36|2@1+ (1,0) [0|3] "Unit_None"  Gateway,Gateway_PAG
 SG_ PSD_Ges_Geschwindigkeit_Tag_Ende m2  : 36|3@1+ (1.0,0.0) [0.0|7] ""  Gateway,Gateway_PAG
 SG_ PSD_Sys_Quali_verfuegbar m0  : 38|1@1+ (1.0,0.0) [0.0|1] ""  Gateway,Gateway_PAG
 SG_ PSD_Sys_Zielfuehrung_geaendert m0  : 39|1@1+ (1.0,0.0) [0.0|1] ""  Gateway,Gateway_PAG
 SG_ PSD_Ges_Geschwindigkeit_Std_Anf m2  : 39|5@1+ (1,0) [0|24] "Unit_Hours"  Gateway,Gateway_PAG
 SG_ PSD_Steigung_1_Attribute_kompl m4  : 39|1@1+ (1.0,0.0) [0.0|1] ""  Gateway,Gateway_PAG
 SG_ PSD_Sys_Geometrieguete_erweitert m0  : 40|8@1+ (1.0,0.0) [0.0|255] ""  Gateway,Gateway_PAG
 SG_ PSD_Steigung_2_Segment_ID m4  : 40|6@1+ (1,0) [2|63] ""  Gateway,Gateway_PAG
 SG_ PSD_Attribut_5_ID m1  : 41|5@1+ (1,0) [1|31] ""  Gateway,Gateway_PAG
 SG_ PSD_Ges_Geschwindigkeit_Std_Ende m2  : 44|5@1+ (1,0) [0|24] "Unit_Hours"  Gateway,Gateway_PAG
 SG_ PSD_Attribut_5_Offset m1  : 46|7@1+ (2,0) [0|254] "Unit_Meter"  Gateway,Gateway_PAG
 SG_ PSD_Steigung_2_Steigung m4  : 46|7@1+ (0.12,0) [0.00|15.00] "Unit_PerCent"  Gateway,Gateway_PAG
 SG_ PSD_Sys_Quali_sonstige_Attribute m0  : 48|3@1+ (1,0) [0|7] "Unit_None"  Gateway,Gateway_PAG
 SG_ PSD_Ges_Ueberholverbot m2  : 49|2@1+ (1.0,0.0) [0.0|3] ""  Gateway,Gateway_PAG
 SG_ PSD_Sys_Quali_Steigungen m0  : 51|3@1+ (1,0) [0|7] ""  Gateway,Gateway_PAG
 SG_ PSD_Ges_Wechselverkehrszeichen m2  : 51|3@1+ (1.0,0.0) [0.0|7] ""  Gateway,Gateway_PAG
 SG_ PSD_Attribut_5_Wert m1  : 53|4@1+ (1,0) [0|15] ""  Gateway,Gateway_PAG
 SG_ PSD_Steigung_2_Vorz m4  : 53|1@1+ (1.0,0.0) [0.0|1] ""  Gateway,Gateway_PAG
 SG_ PSD_Sys_Quali_Strassenkennz m0  : 54|3@1+ (1,0) [0|7] "Unit_None"  Gateway,Gateway_PAG
 SG_ PSD_Wechselverkehrszeichen_Typ m2  : 54|2@1+ (1.0,0.0) [0.0|3] ""  Gateway,Gateway_PAG
 SG_ PSD_Baum_Ausrichtung m3  : 54|10@1+ (0.3515625,0) [0E-7|359.6484375] "Unit_DegreOfArc"  Gateway,Gateway_PAG
 SG_ PSD_Steigung_2_Offset m4  : 54|7@1+ (2,0) [0|254] "Unit_Meter"  Gateway,Gateway_PAG
 SG_ PSD_Ges_Gesetzlich_Kategorie m2  : 56|3@1+ (1.0,0.0) [0.0|7] ""  Gateway,Gateway_PAG
 SG_ PSD_Sys_Quali_Tempolimits m0  : 57|3@1+ (1,0) [0|7] "Unit_None"  Gateway,Gateway_PAG
 SG_ PSD_Attribute_Komplett_06 m1  : 57|1@1+ (1.0,0.0) [0.0|1] ""  Gateway,Gateway_PAG
 SG_ PSD_Ges_Gesetzlich_Zusatz m2  : 59|2@1+ (1.0,0.0) [0.0|3] ""  Gateway,Gateway_PAG
 SG_ PSD_Sys_Quali_Vorfahrtsregelung m0  : 60|3@1+ (1,0) [0|7] "Unit_None"  Gateway,Gateway_PAG
 SG_ PSD_Ges_Verkehrszeichen_Quelle m2  : 61|2@1+ (1.0,0.0) [0.0|3] ""  Gateway,Gateway_PAG
 SG_ PSD_Steigung_2_Attribute_kompl m4  : 61|1@1+ (1.0,0.0) [0.0|1] ""  Gateway,Gateway_PAG
 SG_ PSD_Ges_Attribute_Komplett m2  : 63|1@1+ (1.0,0.0) [0.0|1] ""  Gateway,Gateway_PAG

BO_TX_BU_ 908 :Gateway,Gateway_PAG;
BO_TX_BU_ 233 :Gateway,Gateway_PAG;
BO_TX_BU_ 2463978635 :Gateway,Gateway_PAG;
BO_TX_BU_ 850 :Gateway,Gateway_PAG;
BO_TX_BU_ 872 :Gateway,Gateway_PAG;
BO_TX_BU_ 1175 :Gateway,Gateway_PAG;
BO_TX_BU_ 1355 :Gateway,Gateway_PAG;
BO_TX_BU_ 803 :Gateway,Gateway_PAG;
BO_TX_BU_ 2527679498 :Gateway,Gateway_PAG;
BO_TX_BU_ 381 :Gateway,Gateway_PAG;
BO_TX_BU_ 304 :Gateway,Gateway_PAG;
BO_TX_BU_ 2589283731 :Gateway,Gateway_PAG;
BO_TX_BU_ 2589283732 :Gateway,Gateway_PAG;
BO_TX_BU_ 1166 :Gateway,Gateway_PAG;
BO_TX_BU_ 1122 :ZR_High,ZR_LIMU,ZR_MIB_TOP_ab_Gen3,ZR_Standard;
BO_TX_BU_ 1123 :ZR_High,ZR_LIMU,ZR_MIB_TOP_ab_Gen3,ZR_Standard;
BO_TX_BU_ 1124 :ZR_High,ZR_LIMU,ZR_MIB_TOP_ab_Gen3,ZR_Standard;
CM_ BO_ 1175 "neue Struktur ab MQB ohne KD-Fehler";
CM_ BO_ 1355 "neue Struktur ab MQB ohne KD-Fehler";
CM_ BO_ 304 "Nur in MLB verwendet";

CM_ SG_ 2527679670 ORU_EM_Anfrage_Flashdauer "Anfrage an das Energiemanagement, ob ein konkretes Online Remote Update durchgeführt werden kann - Flashdauer in 10s.";
CM_ SG_ 2527679670 ORU_EM_Anfrage_freigegebeneNetze "Meldung der während eines konkreten Online Remote Updates freigegebenen Netze (12V, 48V, HV)";
CM_ SG_ 2527679670 ORU_EM_Anfrage_Stromaufnahme "Meldung der voraussichtlichen durchschnittlichen Stromaufnahme eines konkreten Online Remote Updates an das NVEM";
CM_ SG_ 2527679670 ORU_Status_Anf "Übertragung des Status der Funktion Online Remote Update im Porsche / OTA-FC Fall: Sender ist OTA-FC, GW patcht den Inhalt auf ORU_Status";
CM_ SG_ 2527679670 OTA_FC_FahrwerkAnf "Fahrwerk Anforderung OTA-FC";
CM_ SG_ 2527679670 OTA_FC_FoD_Stornierung "Falls der Kunde eine Assistenz-Funktion storniert, muss der Fahrer darüber informiert werden.
Dies geschieht zum einen durch ein FoD-Icon und andererseits durch einen Anzeigetext.";
CM_ SG_ 2527679670 OTA_FC_Hinweis_Update "Funktion: SWaP online und SW Update
Hinweismeldung, wenn ein OTA SW-Update/Aktivierung verfügbar ist";
CM_ SG_ 2527679670 OTA_FC_IOF_Ausfall "Funktion: IOF (PIDM)
Warnmeldung, wenn Funktion IOF (PIDM) ist ausgefallen ist";
CM_ SG_ 2527679670 OTA_FC_LiftAnf "OTA-FC Lift Anforderung";
CM_ SG_ 2527679670 OTA_FC_NiveauAnf "OTA-FC Niveau Anforderung";
CM_ SG_ 2527679670 OTA_FC_PredMaint_Ausfall "Funktion: Predictive Maintenance
Warnmeldung, wenn Funktion Predictive Maintenance ausgefallen ist";
CM_ SG_ 2527679670 OTA_FC_Warnung_Update "Funktion: SWaP online    und    SW Update
Warnmeldung, wenn OTA SW-Update/Aktivierung nicht erfolgreich war";

CM_ SG_ 908 PACC_Automode "Signal zur Anzeige des InnoDrive Automodes";
CM_ SG_ 908 PACC_Durchschnittsgeschw "Anzeige einer Durchschnittsgeschwindigkeit während des PACChigh / InnoDrive - Betriebs. Dient in Verbindung mit PACC_Durchschnittsverbrauch und PACC_Segelanteil zur Anzeige des Effizienzpotentials.";
CM_ SG_ 908 PACC_naechstes_Event "Anzeige des naechsten Streckenereignisses, welches in der PACC-Regelung eine signifikante Änderung der Zielgeschwindigkeit zur Folge hat (Weiterleitung durch ACC).";
CM_ SG_ 908 PACC_Offset "Anzeige des vom Fahrer (über Tip hoch/Tip runter am KLSM) eingestellten Geschwindigkeitsoffsets (Weiterleitung durch ACC).";
CM_ SG_ 908 PACC_Segelanteil "Anzeige eines kumulierten Segelanteils während des PACChigh / InnoDrive - Betriebs. Dient in Verbindung mit PACC_Durchschnittsverbrauch und PACC_Durchschnittsgeschwindigkeit zur Anzeige des Effizienzpotentials.";
CM_ SG_ 908 PACC_Sollgeschwindigkeit "Wunschgeschwindigkeit von InnoDrive zum ACC";
CM_ SG_ 908 PACC_Systemstatus "Anzeige des Systemstatus InnoDrive";
CM_ SG_ 908 PACC_Sytemstatus_Anzeige "Signal zur Anzeige des PACC_Systemstatus, ggf. mit Entprellung der einzelnen Stati.";
CM_ SG_ 908 PACC_Uebernahmeaufforderung "Hinweis an den Fahrer, dass PACC nicht mehr regelt und er die Laengsführung wieder uebernehmen muss (Weiterleitung durch ACC)";
CM_ SG_ 908 PACC_Vorausschaugeschw "Anzeige der durch PACC in Kürze eingeregelten Zielgeschwindigkeit für den Fahrer.";

CM_ SG_ 233 Parken_Aktives_Bedienelement "Wird während der Bedienung mittels Smartphone ein anderes Bedienelement betätigt (Schlüssel, Innenraumtaste) wird die Funktion zunächst unterbrochen. Der Kunde muss den Grund hierfür auf dem Smartphone angezeigt bekommen. ";
CM_ SG_ 233 Parken_Anhaltegrund "Beschreibt den Grund für das Anhalten des Fahrzeugs. Grund kann ein Abbruch oder eine Unterbrechung sein.";
CM_ SG_ 233 Parken_Anhaltegrund_ext "Beschreibt den Grund für das Anhalten des Fahrzeugs. Grund kann ein Abbruch oder eine Unterbrechung sein. Dieses Signal erweitert den Wertebereich von Parken_Anhaltegrund.";
CM_ SG_ 233 Parken_BT_Wunsch "Das zFAS teilt der Antenne mit, dass eine Bluetooth Verbindung erwuenscht ist. Der Wert „0“ zeigt an, dass die Antenne in den Sleep Mode gehen kann.";
CM_ SG_ 233 Parken_Fahrtaster_Empfehlung "Hat der Nutzer den Fahrtaster auf dem Smartphone losgelassen und erkennt die Parkfunktion die Möglichkeit in mehr als eine Fahrtrichtung fortzusetzen, bekommt der Nutzer eine Empfehlung der Parkfunktion ausgesprochen. Dieses Signal dient der Markierung/He";
CM_ SG_ 233 Parken_FFB_Status "Dieses Signal teilt den aktuellen Fahrzeugschlüsselstatus mit. ";
CM_ SG_ 233 Parken_Fortschrittszaehler "Zeigt den aktuellen Zustand des Fortschrittsbalken. Der Fortschrittsbalken spiegelt den zeitlichen Verlauf des gesamten Parkvorgangs wider.";
CM_ SG_ 233 Parken_Funktionsstatus "Die Parkfunktion liefert den aktuellen Funktionsstatus. Daraus resultieren die verschiedenen Screens auf dem Smartphone, die Freischaltung bestimmter Eingabeelemente und/oder die Anzeige von Texten etc.";
CM_ SG_ 233 Parken_Hindernis_Bereich "Teilt dem Smartphone mit, in welchem Bereich das nächstgelegene Hindernis im Fahrschlauch erkannt wurde.";
CM_ SG_ 233 Parken_Hindernis_erkannt "Die Parkfunktion teilt dem Smartphone mit, ob ein Hindernis erkannt wurde, auf das gebremst wurde. ";
CM_ SG_ 233 Parken_Manoever "Beschreibt ob ein- oder ausgeparkt werden soll";
CM_ SG_ 233 Parken_Manoever_Aktiv "Beschreibt das anliegende bzw. ausgewählte Manoever.";
CM_ SG_ 233 Parken_Reversieren_moeglich "Die Parkfunktion teilt dem Smartphone mit, ob eine Betätigung des 'Reverse' oder 'Back' Tasters durch den Kunden möglich ist. ";
CM_ SG_ 233 Parken_Richtung "Beschreibt ob die Parklücke vorwärts oder rückwärts beparkt werden soll";
CM_ SG_ 233 Parken_Richtung_Aktiv "Beschreibt die anliegende bzw. ausgewählte Richtung.";
CM_ SG_ 233 Parken_Seite "Beschreibt ob eine Lücke links oder rechts vom Fahrzeug beparkt werden soll. Beim Ausparken kann zusätzlich zu einer Seite, geradeaus ausgeparkt werden. ";
CM_ SG_ 233 Parken_Seite_Aktiv "Beschreibt die anliegende bzw. ausgewählte Seite.";
CM_ SG_ 233 Parken_SM_Anhaenger "Teilt der App mit, dass ein gültiger Anhänger erkannt wurde.";
CM_ SG_ 233 Parken_SM_Fahrbereitschaft "Teilt der App die Fahrbereitschaft des Motors mit";
CM_ SG_ 233 Parken_SM_Fahrstufe "Teilt der App mit, dass die korrekteFahrstufe eingelegt ist.";
CM_ SG_ 233 Parken_SM_Schluessel "Teilt der App mit, dass ein gültiger Schlüssel in Reichweite ist.";
CM_ SG_ 233 Parken_SM_Sensor "Teilt der App den Zustand der Rückfahkamera mit";
CM_ SG_ 233 Parken_SM_Stillstand "Teilt der App den sicheren Stillstand mit.";
CM_ SG_ 233 Parken_SM_Tueren "Teilt der App den Zustand der Klappen und Türen mit.";
CM_ SG_ 233 Parken_Szenario "Beschreibt den Grundszenarientyp (Parallel = Längsparken; Perpendicular = Querparken; Garage = Garagenparken; Basic = Basisfunktion vorwärts oder rückwärts ohne Lenkeingriff) ";
CM_ SG_ 233 Parken_Szenario_Aktiv "Beschreibt das anliegende bzw. ausgewählte Szenario.";
CM_ SG_ 233 Parken_Touchdiagnose_Anf "Anforderung einer Touch-Diagnose auf dem mobilen Endgerät.";

CM_ SG_ 2463978635 Parken_Traj_aktueller_Zug "Nummer des aktuellen Zuges";
CM_ SG_ 2463978635 Parken_Traj_Anzahl_Punkte "Anzahl der Punkte auf der Trajektorie";
CM_ SG_ 2463978635 Parken_Traj_Fahrtrichtung "Aktuelle Fahrtrichtung des Fahrzeugs";
CM_ SG_ 2463978635 Parken_Traj_Fzg_Pos_X "relative X-Position Fahrzeug zu Startpunkt Parkvorgang in cm";
CM_ SG_ 2463978635 Parken_Traj_Fzg_Pos_Y "relative Y-Position Fahrzeug zu Startpunkt Parkvorgang in cm";
CM_ SG_ 2463978635 Parken_Traj_Fzg_Winkel "Ausrichtung des Fahrzeugs ausgehend von der Fahrzeug Position als Polarwinkel";
CM_ SG_ 2463978635 Parken_Traj_letzter_Zug "Zur Definition, ob es sich um ein Wendepunkt oder Zielpunkt handelt";
CM_ SG_ 2463978635 Parken_Traj_Trans_ID "Eineindeutige ID für berechnete Trajektorie zum aktuellen Parkvorgang vom ZFAS für das Smartphone (geroutet über die DDA)";

CM_ SG_ 850 Parken_SM_03_MUX "Linearer MUX-Verlauf.

Wird bei jedem MUX übertragen
Punktinfo 1 -9 (Mux 0 -6)";
CM_ SG_ 850 Parken_SM_03_Traj_Trans_ID_00 "wird bei jedem MUX übertragen
Transaktion ID der Trajektorienpunkte
Wird bei jedem MUX übertragen um die Zusammengehörigkeit zwischen Basisinfo und Punktinfos zu gewährleisten";
CM_ SG_ 850 Parken_SM_03_Traj_Trans_ID_01 "wird bei jedem MUX übertragen
Transaktion ID der Trajektorienpunkte
Wird bei jedem MUX übertragen um die Zusammengehörigkeit zwischen Basisinfo und Punktinfos zu gewährleisten";
CM_ SG_ 850 Parken_SM_03_Traj_Trans_ID_02 "wird bei jedem MUX übertragen
Transaktion ID der Trajektorienpunkte
Wird bei jedem MUX übertragen um die Zusammengehörigkeit zwischen Basisinfo und Punktinfos zu gewährleisten";
CM_ SG_ 850 Parken_SM_03_Traj_Trans_ID_03 "wird bei jedem MUX übertragen
Transaktion ID der Trajektorienpunkte
Wird bei jedem MUX übertragen um die Zusammengehörigkeit zwischen Basisinfo und Punktinfos zu gewährleisten";
CM_ SG_ 850 Parken_SM_03_Traj_Trans_ID_04 "wird bei jedem MUX übertragen
Transaktion ID der Trajektorienpunkte
Wird bei jedem MUX übertragen um die Zusammengehörigkeit zwischen Basisinfo und Punktinfos zu gewährleisten";
CM_ SG_ 850 Parken_SM_03_Traj_Trans_ID_05 "wird bei jedem MUX übertragen
Transaktion ID der Trajektorienpunkte
Wird bei jedem MUX übertragen um die Zusammengehörigkeit zwischen Basisinfo und Punktinfos zu gewährleisten";
CM_ SG_ 850 Parken_SM_03_Traj_Trans_ID_06 "wird bei jedem MUX übertragen
Transaktion ID der Trajektorienpunkte
Wird bei jedem MUX übertragen um die Zusammengehörigkeit zwischen Basisinfo und Punktinfos zu gewährleisten";
CM_ SG_ 850 Parken_Traj_P1_Pos_X "MUX = 0 
relative X-Position Punkt zu Startpunkt Parkvorgang in cm";
CM_ SG_ 850 Parken_Traj_P1_Pos_Y "MUX = 0 
relative Y-Position Punkt zu Startpunkt Parkvorgang in cm";
CM_ SG_ 850 Parken_Traj_P1_Tangent "MUX = 0
Beschreibt den Polarwinkel den Tangenten-Vektor des Kreisbogen der am Punkt (X-Position / Y-Position) startet";
CM_ SG_ 850 Parken_Traj_P2_Pos_X "MUX = 0 
relative X-Position Punkt zu Startpunkt Parkvorgang in cm";
CM_ SG_ 850 Parken_Traj_P2_Pos_Y "MUX = 1
relative Y-Position Punkt zu Startpunkt Parkvorgang in cm";
CM_ SG_ 850 Parken_Traj_P2_Tangent "MUX = 1
Beschreibt den Polarwinkel den Tangenten-Vektor des Kreisbogen der am Punkt (X-Position / Y-Position) startet'";
CM_ SG_ 850 Parken_Traj_P3_Pos_X "MUX = 1
relative X-Position Punkt zu Startpunkt Parkvorgang in cm";
CM_ SG_ 850 Parken_Traj_P3_Pos_Y "MUX = 1
relative Y-Position Punkt zu Startpunkt Parkvorgang in cm";
CM_ SG_ 850 Parken_Traj_P3_Tangent "MUX = 2
Beschreibt den Polarwinkel den Tangenten-Vektor des Kreisbogen der am Punkt (X-Position / Y-Position) startet";
CM_ SG_ 850 Parken_Traj_P4_Pos_X "MUX = 2
relative X-Position Punkt zu Startpunkt Parkvorgang in cm";
CM_ SG_ 850 Parken_Traj_P4_Pos_Y "MUX = 2
relative Y-Position Punkt zu Startpunkt Parkvorgang in cm";
CM_ SG_ 850 Parken_Traj_P4_Tangent "MUX = 2
Beschreibt den Polarwinkel den Tangenten-Vektor des Kreisbogen der am Punkt (X-Position / Y-Position) startet";
CM_ SG_ 850 Parken_Traj_P5_Pos_X "MUX = 3
relative X-Position Punkt zu Startpunkt Parkvorgang in cm";
CM_ SG_ 850 Parken_Traj_P5_Pos_Y "MUX = 3
relative Y-Position Punkt zu Startpunkt Parkvorgang in cm";
CM_ SG_ 850 Parken_Traj_P5_Tangent "MUX = 3
Beschreibt den Polarwinkel den Tangenten-Vektor des Kreisbogen der am Punkt (X-Position / Y-Position) startet";
CM_ SG_ 850 Parken_Traj_P6_Pos_X "MUX = 3
relative X-Position Punkt zu Startpunkt Parkvorgang in cm";
CM_ SG_ 850 Parken_Traj_P6_Pos_Y "MUX = 4
relative Y-Position Punkt zu Startpunkt Parkvorgang in cm";
CM_ SG_ 850 Parken_Traj_P6_Tangent "MUX = 4
Beschreibt den Polarwinkel den Tangenten-Vektor des Kreisbogen der am Punkt (X-Position / Y-Position) startet";
CM_ SG_ 850 Parken_Traj_P7_Pos_X "MUX = 4
relative X-Position Punkt zu Startpunkt Parkvorgang in cm";
CM_ SG_ 850 Parken_Traj_P7_Pos_Y "MUX = 4
relative Y-Position Punkt zu Startpunkt Parkvorgang in cm";
CM_ SG_ 850 Parken_Traj_P7_Tangent "MUX = 5
Beschreibt den Polarwinkel den Tangenten-Vektor des Kreisbogen der am Punkt (X-Position / Y-Position) startet";
CM_ SG_ 850 Parken_Traj_P8_Pos_X "MUX = 5
relative X-Position Punkt zu Startpunkt Parkvorgang in cm";
CM_ SG_ 850 Parken_Traj_P8_Pos_Y "MUX = 5
relative Y-Position Punkt zu Startpunkt Parkvorgang in cm";
CM_ SG_ 850 Parken_Traj_P8_Tangent "MUX = 5
Beschreibt den Polarwinkel den Tangenten-Vektor des Kreisbogen der am Punkt (X-Position / Y-Position) startet";
CM_ SG_ 850 Parken_Traj_P9_Pos_X "MUX = 6
relative X-Position Punkt zu Startpunkt Parkvorgang in cm";
CM_ SG_ 850 Parken_Traj_P9_Pos_Y "MUX = 6
relative Y-Position Punkt zu Startpunkt Parkvorgang in cm";
CM_ SG_ 850 Parken_Traj_P9_Tangent "MUX = 6
Beschreibt den Polarwinkel den Tangenten-Vektor des Kreisbogen der am Punkt (X-Position / Y-Position) startet";

CM_ SG_ 872 PDC2_Tonausgabe_Front "In Abhängigkeit der Systemaktivitäten werden unterschiedliche Tonwarnungen ausgegeben. 
Kombi spielt entsprechende WAV.-Datei über internen Audiomaster ab.

0 = kein Ton
1 = Intervallton 1
2 = Intervallton 2
3 = Intervallton 3
4 = Intervallton 4
5";
CM_ SG_ 872 PDC2_Tonausgabe_Heck "In Abhängigkeit der Systemaktivitäten werden unterschiedliche Tonwarnungen ausgegeben. 
Kombi spielt entsprechende WAV.-Datei über internen Audiomaster ab.

0 = kein Ton
1 = Intervallton 1
2 = Intervallton 2
3 = Intervallton 3
4 = Intervallton 4
5";
CM_ SG_ 872 PH2_Abschaltursache "Abschaltursache bleibt bis zur nächsten Aktivierung bzw. bis KL15 aus gesetzt
Im Fehlerfall (blinkende LED) wird '7' gesendet obwohl das System noch aktiv ist, bei 'geheiltem' Fehler wird sofort wieder der Zustand '0' gesendet";
CM_ SG_ 872 PH2_Anf_Audioabsenkung "Es gibt zwei unterschiedliche Nachlauftimer für dieses Bit:
1. normale Funktion
2. Demotonausgabe";
CM_ SG_ 872 PH2_Anf_Verdeck "Anforderung an ein Verdeck-System, die vom Fahrer angeforderte Öffnung/Schließung zu verhindern";
CM_ SG_ 872 PH2_defekt "Zeigt an das sich die Parkhilfe im Fehlerzustand befindet. Signal bleibt bis zur nächsten 'Gut-Aktivierung' gesetzt.
Spezialfall: Sensordefekt hinten bei Anhängerbetrieb. Anhänger wird abgesteckt Fehler wird gesetzt. Fehlerfall bleibt bis Behebung des De";
CM_ SG_ 872 PH2_Display_Kundenwunsch "Anzeige der bei Aktivierung verwendeten Parameter bzgl. Kundenwunsch Displayanziege. Änderungen werden erst bei erneuter Aktivierung aktualisiert.";
CM_ SG_ 872 PH2_Frequenz_hinten "Uebertragung der aktuell im APS Steuergeraet gespeicherten Werte fuer Tongeber Frequenz hinten
Anzeige der aktuell verwendeten Parameter (nicht zwingend die abgespeicherten - da Werte erst 2s nach der letzten Änderung gespeichert werden!)";
CM_ SG_ 872 PH2_Frequenz_vorn "Uebertragung der aktuell im APS Steuergeraet gespeicherten Werte fuer Tongeber Frequenz vorne
Anzeige der aktuell verwendeten Parameter (nicht zwingend die abgespeicherten - da Werte erst 2s nach der letzten Änderung gespeichert werden!)";
CM_ SG_ 872 PH2_gestoert "Eine Störung ist aufgetreten, der die Parkhilfe in einen 'gestört-Zustand' versetzt, z.B. massiver Fremdultraschall, Vereisung, Schnee.Derzeit nur für Störschall benutzt, da keinerlei andere Erkennung implementiert.";
CM_ SG_ 872 PH2_Lautstaerke_hinten "Uebertragung der aktuell im APS Steuergeraet gespeicherten Werte fuer Tongeber Lautstaerke hinten
Anzeige der aktuell verwendeten Parameter (nicht zwingend die abgespeicherten - da Werte erst 2s nach der letzten Änderung gespeichert werden!)";
CM_ SG_ 872 PH2_Lautstaerke_vorn "Uebertragung der aktuell im APS Steuergeraet gespeicherten Werte fuer Tongeber Lautstaerke vorn.
Anzeige der aktuell verwendeten Parameter (nicht zwingend die abgespeicherten - da Werte erst 2s nach der letzten Änderung gespeichert werden!)";
CM_ SG_ 872 PH2_nachtr_Stopp_An "Dieses Signal dient dem Motor als Trigger, dass ein nachträglicher Motorstopp eingeleitet werden kann, wenn es die Bedingungen des StSt Koordinators dies zulassen. ";
CM_ SG_ 872 PH2_Opt_Anz_H_Hindernis "mindestens 1 Segment wird für den hinteren Detekionsbereich dargestellt, also ein Hindernis ist im Detektionsbereich. Funktion nur bei gesicherter Rückmeldung vom ASG gegeben.";
CM_ SG_ 872 PH2_Opt_Anz_V_Hindernis "mindestens 1 Segment wird für den vorderen Detekionsbereich dargestellt, also ein Hindernis ist im Detektionsbereich. Funktion nur bei gesicherter Rückmeldung vom ASG gegeben.";
CM_ SG_ 872 PH2_Opt_Anzeige_H_ein "OPS hinten ist im Display aktiv bzw. Anzeigemodule hinten sind eingeschaltet. Funktion nur bei gesicherter Rückmeldung vom ASG gegeben.";
CM_ SG_ 872 PH2_Opt_Anzeige_V_ein "OPS vorne ist im Display aktiv bzw. Anzeigemodule vorne sind eingeschaltet. Funktion nur bei gesicherter Rückmeldung vom ASG gegeben.";
CM_ SG_ 872 PH2_StartStopp_Info "Stopp-Freigabe und Start-Anforderung an den Start-Stopp-Koordinator";
CM_ SG_ 872 PH2_Stoermeldung "Meldung einer Störung der PDC an das Kombi";
CM_ SG_ 872 PH2_Systemzustand "Aktivierungsursache wird für die Dauer der Aktivierung gemeldet.
Im Fehlerfall bei atkviem System wechselt das Signal auf '7'
(siehe auch 'Abschaltursache')";
CM_ SG_ 872 PH2_Taster "Taster Status (für RVC/TopView)";
CM_ SG_ 872 PH2_Tongeber_H_aktiv "Rohsignal für 'Tongeber hinten wird angesteuert', verlängerbar mit Nachlauftimer.
Bit wird nicht während des Stellgliedtests angesteuert.";
CM_ SG_ 872 PH2_Tongeber_H_verfuegbar "Tongeber ist für die Tonausgabe für externe Funktionen verfügbar. PDC ist aktiv und Tongeber ist nicht gestört.";
CM_ SG_ 872 PH2_Tongeber_mute "Die Akustikausgabe des Systems wird unterdrückt, z.B. Wählhebel in 'P', Parlbremse geschlossen (8-Kanal-System)";
CM_ SG_ 872 PH2_Tongeber_V_aktiv "Rohsignal für 'Tongeber vorne wird angesteuert', verlängerbar mit Nachlauftimer.
Bit wird nicht während des Stellgliedtests angesteuert.";
CM_ SG_ 872 PH2_Visualisierung "Signal zeigt den Partnersteuergeräten RearView/TopView/ARA/... den aktuellen Status der Visualisierung des OPS. Die Partnersteuergeräte können dadurch auch ihre Aufschaltung an dieses Signal koppeln.";

CM_ SG_ 1175 PDC_Tonausgabe_Front "In Abhängigkeit der Systemaktivitäten werden unterschiedliche Tonwarnungen ausgegeben. 
Kombi spielt entsprechende WAV.-Datei über internen Audiomaster ab.

0 = kein Ton
1 = Intervallton 1
2 = Intervallton 2
3 = Intervallton 3
4 = Intervallton 4
5";
CM_ SG_ 1175 PDC_Tonausgabe_Heck "In Abhängigkeit der Systemaktivitäten werden unterschiedliche Tonwarnungen ausgegeben. 
Kombi spielt entsprechende WAV.-Datei über internen Audiomaster ab.

0 = kein Ton
1 = Intervallton 1
2 = Intervallton 2
3 = Intervallton 3
4 = Intervallton 4
5";
CM_ SG_ 1175 PH_Abschaltursache "Abschaltursache bleibt bis zur nächsten Aktivierung bzw. bis KL15 aus gesetzt
Im Fehlerfall (blinkende LED) wird '7' gesendet obwohl das System noch aktiv ist, bei 'geheiltem' Fehler wird sofort wieder der Zustand '0' gesendet";
CM_ SG_ 1175 PH_Anf_Audioabsenkung "Es gibt zwei unterschiedliche Nachlauftimer für dieses Bit:
1. normale Funktion
2. Demotonausgabe";
CM_ SG_ 1175 PH_Anf_Verdeck "Anforderung an ein Verdeck-System, die vom Fahrer angeforderte Öffnung/Schließung zu verhindern";
CM_ SG_ 1175 PH_defekt "Zeigt an das sich die Parkhilfe im Fehlerzustand befindet. Signal bleibt bis zur nächsten 'Gut-Aktivierung' gesetzt.
Spezialfall: Sensordefekt hinten bei Anhängerbetrieb. Anhänger wird abgesteckt Fehler wird gesetzt. Fehlerfall bleibt bis Behebung des De";
CM_ SG_ 1175 PH_Display_Kundenwunsch "Anzeige der bei Aktivierung verwendeten Parameter bzgl. Kundenwunsch Displayanziege. Änderungen werden erst bei erneuter Aktivierung aktualisiert.";
CM_ SG_ 1175 PH_Frequenz_hinten "Uebertragung der aktuell im APS Steuergeraet gespeicherten Werte fuer Tongeber Frequenz hinten
Anzeige der aktuell verwendeten Parameter (nicht zwingend die abgespeicherten - da Werte erst 2s nach der letzten Änderung gespeichert werden!)";
CM_ SG_ 1175 PH_Frequenz_vorn "Uebertragung der aktuell im APS Steuergeraet gespeicherten Werte fuer Tongeber Frequenz vorne
Anzeige der aktuell verwendeten Parameter (nicht zwingend die abgespeicherten - da Werte erst 2s nach der letzten Änderung gespeichert werden!)";
CM_ SG_ 1175 PH_gestoert "Eine Störung ist aufgetreten, der die Parkhilfe in einen 'gestört-Zustand' versetzt, z.B. massiver Fremdultraschall, Vereisung, Schnee.Derzeit nur für Störschall benutzt, da keinerlei andere Erkennung implementiert.";
CM_ SG_ 1175 PH_Lautstaerke_hinten "Uebertragung der aktuell im APS Steuergeraet gespeicherten Werte fuer Tongeber Lautstaerke hinten
Anzeige der aktuell verwendeten Parameter (nicht zwingend die abgespeicherten - da Werte erst 2s nach der letzten Änderung gespeichert werden!)";
CM_ SG_ 1175 PH_Lautstaerke_vorn "Uebertragung der aktuell im APS Steuergeraet gespeicherten Werte fuer Tongeber Lautstaerke vorn.
Anzeige der aktuell verwendeten Parameter (nicht zwingend die abgespeicherten - da Werte erst 2s nach der letzten Änderung gespeichert werden!)";
CM_ SG_ 1175 PH_nachtr_Stopp_Anf "Dieses Signal dient dem Motor als Trigger, dass ein nachträglicher Motorstopp eingeleitet werden kann, wenn es die Bedingungen des StSt Koordinators dies zulassen. ";
CM_ SG_ 1175 PH_Opt_Anz_H_Hindernis "mindestens 1 Segment wird für den hinteren Detekionsbereich dargestellt, also ein Hindernis ist im Detektionsbereich. Funktion nur bei gesicherter Rückmeldung vom ASG gegeben.";
CM_ SG_ 1175 PH_Opt_Anz_V_Hindernis "mindestens 1 Segment wird für den vorderen Detekionsbereich dargestellt, also ein Hindernis ist im Detektionsbereich. Funktion nur bei gesicherter Rückmeldung vom ASG gegeben.";
CM_ SG_ 1175 PH_Opt_Anzeige_H_ein "OPS hinten ist im Display aktiv bzw. Anzeigemodule hinten sind eingeschaltet. Funktion nur bei gesicherter Rückmeldung vom ASG gegeben.";
CM_ SG_ 1175 PH_Opt_Anzeige_V_ein "OPS vorne ist im Display aktiv bzw. Anzeigemodule vorne sind eingeschaltet. Funktion nur bei gesicherter Rückmeldung vom ASG gegeben.";
CM_ SG_ 1175 PH_StartStopp_Info "Stopp-Freigabe und Start-Anforderung an den Start-Stopp-Koordinator";
CM_ SG_ 1175 PH_Stoermeldung "Meldung einer Störung der PDC an das Kombi";
CM_ SG_ 1175 PH_Systemzustand "Aktivierungsursache wird für die Dauer der Aktivierung gemeldet.
Im Fehlerfall bei atkviem System wechselt das Signal auf '7'
(siehe auch 'Abschaltursache')";
CM_ SG_ 1175 PH_Taster "Taster Status (für RVC/TopView)";
CM_ SG_ 1175 PH_Tongeber_H_aktiv "Rohsignal für 'Tongeber hinten wird angesteuert', verlängerbar mit Nachlauftimer.
Bit wird nicht während des Stellgliedtests angesteuert.";
CM_ SG_ 1175 PH_Tongeber_H_verfuegbar "Tongeber ist für die Tonausgabe für externe Funktionen verfügbar. PDC ist aktiv und Tongeber ist nicht gestört.";
CM_ SG_ 1175 PH_Tongeber_mute "Die Akustikausgabe des Systems wird unterdrückt, z.B. Wählhebel in 'P', Parlbremse geschlossen (8-Kanal-System)";
CM_ SG_ 1175 PH_Tongeber_V_aktiv "Rohsignal für 'Tongeber vorne wird angesteuert', verlängerbar mit Nachlauftimer.
Bit wird nicht während des Stellgliedtests angesteuert.";
CM_ SG_ 1175 PH_Visualisierung "Signal zeigt den Partnersteuergeräten RearView/TopView/ARA/... den aktuellen Status der Visualisierung des OPS. Die Partnersteuergeräte können dadurch auch ihre Aufschaltung an dieses Signal koppeln.";
CM_ SG_ 1175 PLA_Anf_Aufschaltung_RVC "Anforderung der Aufschaltung RVC durch PLA";

CM_ SG_ 1355 BCM_WAH_Meldung "Steuert die HMI-Meldungen im Kombi für den Wiederanfahrhinweis";
CM_ SG_ 1355 PDC_Charisma_FahrPr "Istwert der Kennline (siehe System-LAH MQB FPA)";
CM_ SG_ 1355 PDC_Charisma_Status "Charisma Systemstatus des Charisma-Teilnehmers";
CM_ SG_ 1355 PH_Aufschaltursache "Der Grund für die Aufschaltung der Einparkhilfe wird angegeben, z.B. bei der Aktivierung der Einparkhilfe durch eine andere Funktion, wird diese Funktion als Aktivierungsursache für die Dauer der Aktivierung gemeldet.
Das Signal wird den PH_Systemzustand";
CM_ SG_ 1355 PH_Ton_Ausgabe "Anforderung einer Tonausgabe beim MIB3 durch die Parkhilfe";
CM_ SG_ 1355 PH_Ton_Lautstaerke "Wunschlautstärke der Tonanforderung beim MIB3 durch die Parkhilfe.";
CM_ SG_ 1355 PH_Ton_Pausenlaenge "Pause zwischen den angeforderten Tönen beim MIB3 durch die Parkhilfe. Nur für Intervalltöne, nicht relevant für Dauerton und Quittierungston.";
CM_ SG_ 1355 PH_Ton_Richtung "Abspielrichtung des angeforderten Ton beim MIB3 durch die Parkhilfe";
CM_ SG_ 1355 PH_Verschmutzungsmeldung "Meldung einer Verschmutzung/Vereisung der PDC an das Kombi";

CM_ SG_ 803 PCF_01_BZ "Botschaftszähler pro PDU


Botschaft asynchron geroutet. Zählerwert kann springen.";
CM_ SG_ 803 PCF_01_CRC "Für MLB:
'Berechnung siehe Lastenheft 'Kommunikationsabsicherung für Flexray und CAN''

Ab MQB und MLBevo:
'Berechnung siehe Lastenheft 'End-to-End Kommunikationsabsicherung'

Endwerte siehe Begleitdokument 'S-PDU Kennungsfolge'";
CM_ SG_ 803 PCF_HBA_Param "Mitteilung an das ESC-SG, welcher HBA-Parametersatz verwendet werden muss";
CM_ SG_ 803 PCF_Prefill_Anf "Mitteilung an das ESC-SG, dass die Prefill-Funktion aktiviert werden soll";
CM_ SG_ 803 PCF_Ruckprofil "Mitteilung an das ESC-SG welches Ruckprofil angefordert wird";
CM_ SG_ 803 PCF_Verz_Anf "Verzoegerungsanforderung an das ESC";
CM_ SG_ 803 PCF_Verz_Anf_ASIL "ASIL-Level der derzeit angeforderten Verzögerung";
CM_ SG_ 803 PCF_Verz_Auspraegung "Anforderung der Auspraegung einer Bremsanforderung an das ESC-SG";
CM_ SG_ 803 PCF_Verz_Info "Mitteilung an das ESC-SG welche Bremsanforderung aktuell angefordert wird";
CM_ SG_ 803 SC_AbstWarn_Texte "Safety Computer übermittelt Systemstatus der Abstandswarnfunktion an Kombi";
CM_ SG_ 803 SC_WarnBrems_Texte "Safety Computer übermittelt Systemstatus der Funktion Warn- und Bremsfunktion an Kombi";

CM_ SG_ 2527679498 IAA_Active_User_ID "Signal gibt die IAA Nutzer ID des aktiven IAA Nutzers an.";
CM_ SG_ 2527679498 IAA_Identified_User_ID "Signal gibt die IAA Nutzer ID des vom BCM identifizierten IAA Nutzers an";
CM_ SG_ 2527679498 IAA_PSO_wake_up "Signal zum Wake_up der IAA und PSO Komponenten im Kombi und in der OCU";
CM_ SG_ 2527679498 Perso_Aktiv "Status Personalisierung für den Fahrer aktiviert/ deaktiviert (via HMI)";
CM_ SG_ 2527679498 Perso_Bedienstelle "Signal zeigt an, über welche Bedienstelle die Umschaltung des Benutzerkontos gestartet wurden.";
CM_ SG_ 2527679498 Perso_Fahrernummer "Signal gibt die jewels aktuelle Nummer des Fahrers für die Personalisierung an.
Nicht für AU736 und AU48x.";
CM_ SG_ 2527679498 Perso_Freigabe_Verstellung "Signal zeigt an, ob die Ergonomiefunktionen nach Umschaltung des Benutzerkontos verfahren dürfen.";
CM_ SG_ 2527679498 Perso_Kontonummer "Signal gibt die jewels aktuelle Kontonummer für die Personalisierung an.
Nicht für AU736 und AU48x.";
CM_ SG_ 2527679498 Perso_Schreibschutz "Signal zeigt an, ob der Schreibschutz der Personalisierung aktiv ist.";
CM_ SG_ 2527679498 Perso_Status "Codierstatus der Personalisierung
Nicht für AU736 und AU49x.";
CM_ SG_ 2527679498 Perso_Steuerung "Signal gibt einen Steuerungsbefehl an die Funktionsteilnehmer der Personalisierung.
Nicht für AU736 und AU49x.";
CM_ SG_ 2527679498 Perso_Steuerungsparameter "Signal gibt einen Parameter zum Steuerungsbefehl (Signal Perso_Steuerung) für die Personalisierung an.
Nicht für AU736 und AU49x.";

CM_ SG_ 2463978756 PSO_last_rec_UserID_Src1 "Zuletzt erkannte User-ID der Nutzererkennung Personalisierung 2.0";

CM_ SG_ 381 PLA2_01_BZ "4bit-Botschaftszaehler, wird in jeder Sendebotschaft inkrementiert


Botschaft asynchron geroutet. Zählerwert kann springen.";
CM_ SG_ 381 PLA2_01_CRC "Für MLB:
Berechnung siehe Lastenheft 'Kommunikationsabsicherung für FlexRay und CAN''

Ab MQB und MLBevo:
Berechnung siehe Lastenheft 'End-to-End Kommunikationsabsicherung'

Endwerte siehe Begleitdokument 'S-PDU Kennungsfolgen'";
CM_ SG_ 381 PLA2_Anhalteweg "Anhalteweg für die Anhaltewegschnittstelle IPA/Pilotiertes Parken";
CM_ SG_ 381 PLA2_Status_PLA_EPS "Schnittstelle zum Austausch von Statusinformationen der internen Statusmaschine. Erforderlich zum Aktivieren der automatischen Lenkung.";
CM_ SG_ 381 PLA2_VZ_Zahnstangen_Pos_Soll "Vorzeichen der angeforderten Zahnstangenposition an der EPS (Fahreransicht: positiv = links von der Nullstellung des Lenkrades) ";
CM_ SG_ 381 PLA2_Zahnstangen_Pos_Soll "Steuerbefehl an EPS zum Einstellen der angeforderten Zahnstangenposition.";

CM_ SG_ 304 PLA_01_BZ "4bit-Botschaftszaehler, wird in jeder Sendebotschaft inkrementiert

";
CM_ SG_ 304 PLA_01_CRC "Für MLB:
Berechnung siehe Lastenheft 'Kommunikationsabsicherung für FlexRay und CAN''

Ab MQB und MLBevo:
Berechnung siehe Lastenheft 'End-to-End Kommunikationsabsicherung'

Endwerte siehe Begleitdokument 'S-PDU Kennungsfolgen'";
CM_ SG_ 304 PLA_01_Signal_red_cyclic "Zeigt die reduzierte Zykluszeit der CAN-Botschaft 'PLA_01' an.";
CM_ SG_ 304 PLA_Anf_Bremsverzoegerung "Anforderung der Verzögerungsbremsung";
CM_ SG_ 304 PLA_BremsMom_Verzoeg "Kennzeichnung der übertragenen Sollvorgabe
0 = Bremsmoment: MQB A
1 = Bremsverzoegerung: MLBevo, MQB B
Die Bedatung ist im Fahrzeug konstant.";
CM_ SG_ 304 PLA_Bremsverzoegerung "Wert der Bremsverzögerung für eine Bremsung durch PLA";
CM_ SG_ 304 PLA_Status_PLA_EPS "Schnittstelle zum Austausch von Statusinformationen der internen Statusmaschine. Erforderlich zum Aktivieren der automatischen Lenkung.";
CM_ SG_ 304 PLA_Status_PLA_ESP "Zustand der Statusmaschine des PLA für die korrespondierenden Statusmaschine in der Bremse.";
CM_ SG_ 304 PLA_VZ_Zahnstangen_Pos_Soll "Vorzeichen zum Lenkwinkel-Steuerbefehl an EPS zum Einstellen des angeforderten Lenkwinkels.";
CM_ SG_ 304 PLA_Zahnstangen_Pos_Soll "Steuerbefehl an EPS zum Einstellen der angeforderten Zahnstangenposition.";

CM_ SG_ 2589283731 PLA_SDA_Aktive_Seite "Anzeige gemäß Auswahl der Parklückenseite für Ein- und Ausparken";
CM_ SG_ 2589283731 PLA_SDA_Exist "Anzeige des Symbols, das für die Parklückeinfo verwendet wird. Anzeige entsprechender Symbolik gem. HMI-Spezifikation im Kombiinstrument.";
CM_ SG_ 2589283731 PLA_SDA_Laengs_Querluecke "Anzeige gemäß Auswahl der Parkfunktion für Längs- oder Querparklücke.";
CM_ SG_ 2589283731 PLA_SDA_Li_ID_1 "Orientierung des Fahrzeuges im Segmentenraster auf der Linken Fahrzeugseite.";
CM_ SG_ 2589283731 PLA_SDA_Li_ID_2 "Orientierung des Fahrzeuges im Segmentenraster auf der Linken Fahrzeugseite.";
CM_ SG_ 2589283731 PLA_SDA_Li_ID_3 "Orientierung des Fahrzeuges im Segmentenraster auf der Linken Fahrzeugseite.";
CM_ SG_ 2589283731 PLA_SDA_Li_ID_4 "Orientierung des Fahrzeuges im Segmentenraster auf der Linken Fahrzeugseite.";
CM_ SG_ 2589283731 PLA_SDA_Li_ID_5 "Orientierung des Fahrzeuges im Segmentenraster auf der Linken Fahrzeugseite.";
CM_ SG_ 2589283731 PLA_SDA_Li_ID_6 "Orientierung des Fahrzeuges im Segmentenraster auf der Linken Fahrzeugseite.";
CM_ SG_ 2589283731 PLA_SDA_Li_ID_7 "Orientierung des Fahrzeuges im Segmentenraster auf der Linken Fahrzeugseite.";
CM_ SG_ 2589283731 PLA_SDA_Li_ID_8 "Orientierung des Fahrzeuges im Segmentenraster auf der Linken Fahrzeugseite.";
CM_ SG_ 2589283731 PLA_SDA_Li_Offset_1 "Distanz des detektierten Fahrzeuges / Objektes vom nächsten Segment im Segmentenraster auf der Linken Fahrzeugseite.";
CM_ SG_ 2589283731 PLA_SDA_Li_Offset_2 "Distanz des detektierten Fahrzeuges / Objektes vom nächsten Segment im Segmentenraster auf der Linken Fahrzeugseite.";
CM_ SG_ 2589283731 PLA_SDA_Li_Offset_3 "Distanz des detektierten Fahrzeuges / Objektes vom nächsten Segment im Segmentenraster auf der Linken Fahrzeugseite.";
CM_ SG_ 2589283731 PLA_SDA_Li_Offset_4 "Distanz des detektierten Fahrzeuges / Objektes vom nächsten Segment im Segmentenraster auf der Linken Fahrzeugseite.";
CM_ SG_ 2589283731 PLA_SDA_Li_Offset_5 "Distanz des detektierten Fahrzeuges / Objektes vom nächsten Segment im Segmentenraster auf der Linken Fahrzeugseite.";
CM_ SG_ 2589283731 PLA_SDA_Li_Offset_6 "Distanz des detektierten Fahrzeuges / Objektes vom nächsten Segment im Segmentenraster auf der Linken Fahrzeugseite.";
CM_ SG_ 2589283731 PLA_SDA_Li_Offset_7 "Distanz des detektierten Fahrzeuges / Objektes vom nächsten Segment im Segmentenraster auf der Linken Fahrzeugseite.";
CM_ SG_ 2589283731 PLA_SDA_Li_Offset_8 "Distanz des detektierten Fahrzeuges / Objektes vom nächsten Segment im Segmentenraster auf der Linken Fahrzeugseite.";
CM_ SG_ 2589283731 PLA_SDA_Status "Funktionsstatus";

CM_ SG_ 2589283732 PLA_SDA_Re_ID_1 "Orientierung des Fahrzeuges im Segmentenraster auf der Rechten Fahrzeugseite.";
CM_ SG_ 2589283732 PLA_SDA_Re_ID_2 "Orientierung des Fahrzeuges im Segmentenraster auf der Rechten Fahrzeugseite.";
CM_ SG_ 2589283732 PLA_SDA_Re_ID_3 "Orientierung des Fahrzeuges im Segmentenraster auf der Rechten Fahrzeugseite.";
CM_ SG_ 2589283732 PLA_SDA_Re_ID_4 "Orientierung des Fahrzeuges im Segmentenraster auf der Rechten Fahrzeugseite.";
CM_ SG_ 2589283732 PLA_SDA_Re_ID_5 "Orientierung des Fahrzeuges im Segmentenraster auf der Rechten Fahrzeugseite.";
CM_ SG_ 2589283732 PLA_SDA_Re_ID_6 "Orientierung des Fahrzeuges im Segmentenraster auf der Rechten Fahrzeugseite.";
CM_ SG_ 2589283732 PLA_SDA_Re_ID_7 "Orientierung des Fahrzeuges im Segmentenraster auf der Rechten Fahrzeugseite.";
CM_ SG_ 2589283732 PLA_SDA_Re_ID_8 "Orientierung des Fahrzeuges im Segmentenraster auf der Rechten Fahrzeugseite.";
CM_ SG_ 2589283732 PLA_SDA_Re_Offset_1 "Distanz des detektierten Fahrzeuges / Objektes vom nächsten Segment im Segmentenraster auf der Rechten Fahrzeugseite.";
CM_ SG_ 2589283732 PLA_SDA_Re_Offset_2 "Distanz des detektierten Fahrzeuges / Objektes vom nächsten Segment im Segmentenraster auf der Rechten Fahrzeugseite.";
CM_ SG_ 2589283732 PLA_SDA_Re_Offset_3 "Distanz des detektierten Fahrzeuges / Objektes vom nächsten Segment im Segmentenraster auf der Rechten Fahrzeugseite.";
CM_ SG_ 2589283732 PLA_SDA_Re_Offset_4 "Distanz des detektierten Fahrzeuges / Objektes vom nächsten Segment im Segmentenraster auf der Rechten Fahrzeugseite.";
CM_ SG_ 2589283732 PLA_SDA_Re_Offset_5 "Distanz des detektierten Fahrzeuges / Objektes vom nächsten Segment im Segmentenraster auf der Rechten Fahrzeugseite.";
CM_ SG_ 2589283732 PLA_SDA_Re_Offset_6 "Distanz des detektierten Fahrzeuges / Objektes vom nächsten Segment im Segmentenraster auf der Rechten Fahrzeugseite.";
CM_ SG_ 2589283732 PLA_SDA_Re_Offset_7 "Distanz des detektierten Fahrzeuges / Objektes vom nächsten Segment im Segmentenraster auf der Rechten Fahrzeugseite.";
CM_ SG_ 2589283732 PLA_SDA_Re_Offset_8 "Distanz des detektierten Fahrzeuges / Objektes vom nächsten Segment im Segmentenraster auf der Rechten Fahrzeugseite.";

CM_ SG_ 1166 PLA_Anf_Akustik "Anzeige, ob das PLA einen Gong im Kombi anfordert, Gong soll mit dem Übergang 0->1 abgespielt werden.";
CM_ SG_ 1166 PLA_Anf_Anzeige_Bremsfuss "Anzeige, ob PLA die Anzeige eines Bremsfusses anfordert";
CM_ SG_ 1166 PLA_Anf_Anzeige_Mini "Anforderung der Miniaturanzeige ";
CM_ SG_ 1166 PLA_Anf_Anzeige_Schwellpfeil "Anzeige, ob PLA im Kombi den Schwellpfeil zur Darstellung der Restwegstrecke im aktuellen Zug anfordert";
CM_ SG_ 1166 PLA_Anf_Anzeigemodus "Anzeigemodus das vom PLA je nach Parkszenario beim Kombi angefordert wird";
CM_ SG_ 1166 PLA_Anf_Meldungen "Anforderung der Meldungen:
0 - Keine Meldung
1-127 niederprio. Meldungen
128-255 hochprio. Meldungen";
CM_ SG_ 1166 PLA_Anforderung_HMS "Für die Anforderung der HMS Funktionen";
CM_ SG_ 1166 PLA_Anzahl_Segmente_Schwellpfeil "Wird ein Schwellpfeil angezeigt, gibt dieses Signal die Länge des breiten Balkens in Anzahl der Segmente (max. Länge: 15 Segmente).

Wird keine Anzeige der Schwellpfeile angefordert, muss die Anzahl Segmente 0 sein.";
CM_ SG_ 1166 PLA_Mini_Modus "Art des vom PLA zur Darstellung angeforderten Minis. Wird angezeigt, wenn PLA_Anf_Anzeige_Mini=1.";
CM_ SG_ 1166 PLA_Status_Aktive_Seite "Anzeige der zu parkenden Seite";
CM_ SG_ 1166 PLA_Status_beenden_Mini "Status Anzeige beendet Mini";
CM_ SG_ 1166 PLA_Status_Funktion "Funktionsstati, die die einzelnen Schritte innerhalb eines Parkszenarios anzeigen.";
CM_ SG_ 1166 PLA_Status_Laengsparken_Mini "Status Anzeige Längsparken Mini";
CM_ SG_ 1166 PLA_Status_QP_Rueckw_Mini "Status Anzeige Querparken rückwärts Mini";
CM_ SG_ 1166 PLA_Status_QP_Vorw_Mini "Status Anzeige Querparken vorwärtsMini";

CM_ SG_ 1122 PSD_Abzweigerichtung "Richtung, in der die Abzweigung von der Hauptroute abzweigt
";
CM_ SG_ 1122 PSD_Abzweigewinkel "Winkel, unter dem die Abzweigung von der Hauptroute abzweigt.
";
CM_ SG_ 1122 PSD_ADAS_Qualitaet "ADAS Qualtität des Streckensegments.";
CM_ SG_ 1122 PSD_Anfangskruemmung "Startkrümmung der Klothoide des übermittelten abzweigenden Streckensegments. 
1/(1+0.155 * x^2) {1/m}'
";
CM_ SG_ 1122 PSD_Anfangskruemmung_Vorz "Vorzeichen für die Startkrümmung bei Abzweigungen
";
CM_ SG_ 1122 PSD_Bebauung "Segement befindet sich innerhalb bebauten Gebietes";
CM_ SG_ 1122 PSD_Endkruemmung "'Endkrümmung der Klotoide des übermittelten Streckensegments. Die Anfangskrümmung des folgenden Streckensegments entspricht der Endkrümmung dieses Segments. Krümmung = 1/(1+0.155 * x²) [1/m]

";
CM_ SG_ 1122 PSD_Fahrspuren_Anzahl "Anzahl der Fahrspuren in Fahrtrichtung
";
CM_ SG_ 1122 PSD_Geradester_Pfad "Segment ist Teil des geradesten Pfades";
CM_ SG_ 1122 PSD_Idenditaets_ID "Identifier auf ein Streckensegment, dass mit dem aktuell übertragenen geometrisch identisch ist.";
CM_ SG_ 1122 PSD_Segment_ID "Identifier des prädiktiven Streckensegments
";
CM_ SG_ 1122 PSD_Segment_Komplett "Zeigt, ob alle Attribute für das Segment übertragen worden sind
";
CM_ SG_ 1122 PSD_Segmentlaenge "Gesamtlänge des prädiktiven Streckensegments";
CM_ SG_ 1122 PSD_Strassenkategorie "Klassifizierung der Straße des beschriebenen Segments
";
CM_ SG_ 1122 PSD_Vorgaenger_Segment_ID "An dem Streckensegment mit diesem Identifier schließt sich das neue Segment mit der ID 'PSD_01_Segment_ID' an.
";
CM_ SG_ 1122 PSD_wahrscheinlichster_Pfad "Identifiziert den vom Navigationssystem berechneten wahrscheinlichsten Pfad des Fahrzeuges. ";

CM_ SG_ 1123 PSD_Attribut_1_ID "Identifier des ersten Attributes";
CM_ SG_ 1123 PSD_Attribut_1_Offset "Positionsoffset im Segment für die Position des Attributs";
CM_ SG_ 1123 PSD_Attribut_1_Wert "Wert des ersten Attributes";
CM_ SG_ 1123 PSD_Attribut_2_ID "Identifier des zweiten Attributes";
CM_ SG_ 1123 PSD_Attribut_2_Offset "Positionsoffset im Segment für die Position des Attributs";
CM_ SG_ 1123 PSD_Attribut_2_Wert "Wert des zweiten Attributes";
CM_ SG_ 1123 PSD_Attribut_Segment_ID_05 "Identifier des Streckensegments, für das die weiteren Attribute in der Botschaft gültig sind";
CM_ SG_ 1123 PSD_Attribute_Komplett_05 "Zeigt, ob alle Attribute für das Segment übertragen worden sind";
CM_ SG_ 1123 PSD_Pos_Fahrspur "Spur, auf der sich das Fahrzeug aktuell befindet";
CM_ SG_ 1123 PSD_Pos_Fehler_Laengsrichtung "Laengsfehler der Positionierung";
CM_ SG_ 1123 PSD_Pos_Inhibitzeit "Zeitspanne zwischen Generierung der PSD Daten im Navigationssystem und Versand der Daten auf den Most
";
CM_ SG_ 1123 PSD_Pos_Segment_ID "Identifier des Streckensegments, auf dem sich das Fahrzeug aktuell befindet
";
CM_ SG_ 1123 PSD_Pos_Segmentlaenge "Verbleibende Länge des Streckensegments, auf dem sich das Fahrzeug aktuell befindet
";
CM_ SG_ 1123 PSD_Pos_Standort_Eindeutig "Ist die Position des Fahrzeugs eindeutig dem aktuelle Segment zugeordnet, oder gibt es fahrbare alternative Segmente, die bei akteller GPS-Position ebenfalls als aktuelles Segment möglich wären.";

CM_ SG_ 1124 PSD_06_Mux "Multiplex Zähler für die PSD_06-Botschaft.
Die unterschiedlichen Muxe folgen keiner festen Reihenfolge. Je nach Inhalt des PSD-Protokolls an der aktuellen Position werden jeweils die notwendigen PSD6-Botschaften gesendet.";
CM_ SG_ 1124 PSD_Attribut_3_ID "Identifier des dritten Attributes";
CM_ SG_ 1124 PSD_Attribut_3_Offset "Positionsoffset im Segment für die Position des Attributs";
CM_ SG_ 1124 PSD_Attribut_3_Wert "Wert des dritten Attributes";
CM_ SG_ 1124 PSD_Attribut_4_ID "Typ von Attribut 4";
CM_ SG_ 1124 PSD_Attribut_4_Offset "Offset von Attribut 4";
CM_ SG_ 1124 PSD_Attribut_4_Wert "Wert von Attribut 4";
CM_ SG_ 1124 PSD_Attribut_5_ID "Typ von Attribut 5";
CM_ SG_ 1124 PSD_Attribut_5_Offset "Offset von Attribut 5";
CM_ SG_ 1124 PSD_Attribut_5_Wert "Wert von Attribut 5";
CM_ SG_ 1124 PSD_Attribut_Segment_ID "Identifier des Streckensegments,für das die weiteren Attribute in der Botschaft gültig sind";
CM_ SG_ 1124 PSD_Attribute_Komplett_06 "Zeigt, ob alle Attribute für das Segment übertragen worden sind
";
CM_ SG_ 1124 PSD_Baum_Ausrichtung "Ausrichtung des Fahrzeugsegments zu Nord";
CM_ SG_ 1124 PSD_Baum_Breite "WGS84 Breite des Fahrzeugsegments";
CM_ SG_ 1124 PSD_Baum_Breite_VZ "Vorzeichen WGS84 Breite des Fahrzeugsegments";
CM_ SG_ 1124 PSD_Baum_Laenge "WGS84 Laenge des Fahrzeugsegments";
CM_ SG_ 1124 PSD_Baum_Laenge_VZ "Vorzeichen WGS84 Laenge des Fahrzeugsegments";
CM_ SG_ 1124 PSD_Ges_Attribute_Komplett "Zeigt, ob alle Attribute für das Segment übertragen worden sind";
CM_ SG_ 1124 PSD_Ges_Geschwindigkeit_Gespann "Gilt diese Einschränkung der Geschwindigkeit für alle Fahrzeuge oder ausschließlich für PKW mit Gespann oder für LKW, Buss, etc.";
CM_ SG_ 1124 PSD_Ges_Geschwindigkeit_Std_Anf "Stunde, zu der die stündliche Geschwindigkeitsbegrenzung beginnt
0h.. 24h";
CM_ SG_ 1124 PSD_Ges_Geschwindigkeit_Std_Ende "Stunde, an der die stündliche Geschwindigkeitsbegrenzung endet
0h.. 24h";
CM_ SG_ 1124 PSD_Ges_Geschwindigkeit_Tag_Anf "Wochentag, an dem die tägliche Geschwindigkeitsbegrenzung beginnt";
CM_ SG_ 1124 PSD_Ges_Geschwindigkeit_Tag_Ende "Wochentag, an dem die tägliche Geschwindigkeitsbegrenzung endet";
CM_ SG_ 1124 PSD_Ges_Geschwindigkeit_Witter "Witterungsabhängigkeit der Geschwindigkeitsbegrenzung";
CM_ SG_ 1124 PSD_Ges_Gesetzlich_Kategorie "Kategorie für das legale Gebot";
CM_ SG_ 1124 PSD_Ges_Gesetzlich_Zusatz "Zusatz für das legale Gebot";
CM_ SG_ 1124 PSD_Ges_Offset "Positionsoffset im Segment für die Position des Attributs";
CM_ SG_ 1124 PSD_Ges_Segment_ID "Identifier des prädiktiven Streckensegments ab dem die Geschwindigkeitsbegrenzungen und mögliche Einschränkungen gelten.
";
CM_ SG_ 1124 PSD_Ges_Spur_Geschw_Begrenzung "Definition der Spuren, für die das übertragene Gebot gilt";
CM_ SG_ 1124 PSD_Ges_Typ "Typ der Geschwindigkeitsbegrenzung
";
CM_ SG_ 1124 PSD_Ges_Verkehrszeichen_Quelle "Quelle der Verkehrszeicheninformation";
CM_ SG_ 1124 PSD_Ges_Wechselverkehrszeichen "Am Beginn des Segments ist ein Wechselverkehrszeichen angebracht.";
CM_ SG_ 1124 PSD_Steigung_1_A_Offset "Positionsoffset im Segment für die Position der Steigung 1 A";
CM_ SG_ 1124 PSD_Steigung_1_A_Steigung "Steigung des Segments ab Offset 1A";
CM_ SG_ 1124 PSD_Steigung_1_A_Vorz "Vorzeichen für Steigung 1 A";
CM_ SG_ 1124 PSD_Steigung_1_Attribute_kompl "Alle Steigungsdaten für dieses Segment gesendet";
CM_ SG_ 1124 PSD_Steigung_1_B_Offset "Positionsoffset im Segment für die Position der Steigung 1 B";
CM_ SG_ 1124 PSD_Steigung_1_B_Steigung "Steigung des Segments ab Offset 1B";
CM_ SG_ 1124 PSD_Steigung_1_B_Vorz "Vorzeichen für Steigung 1 B";
CM_ SG_ 1124 PSD_Steigung_1_Segment_ID "Identifier des prädiktiven Streckensegments, zu dem die  ersten beiden Steigungswerte dieser Botschaft gehören";
CM_ SG_ 1124 PSD_Steigung_2_Attribute_kompl "Alle Steigungsdaten für dieses Segment gesendet";
CM_ SG_ 1124 PSD_Steigung_2_Offset "Positionsoffset im Segment für die Position der Steigung 2";
CM_ SG_ 1124 PSD_Steigung_2_Segment_ID "Identifier des prädiktiven Streckensegments, zu dem der dritte Steigungswert dieser Botschaft gehört";
CM_ SG_ 1124 PSD_Steigung_2_Steigung "Steigung des Segments ab Offset 2";
CM_ SG_ 1124 PSD_Steigung_2_Vorz "Vorzeichen für Steigung 2";
CM_ SG_ 1124 PSD_Sys_Alter_Karte "Alter der Karte";
CM_ SG_ 1124 PSD_Sys_Geometrieguete "Maß für die Güte der Klothoidengeometrie.";
CM_ SG_ 1124 PSD_Sys_Geometrieguete_erweitert "Güte der Kurvenrepräsentation der Klothoiden";
CM_ SG_ 1124 PSD_Sys_Geschwindigkeit_Einheit "Unterscheidung zwischen km/h und miles/h";
CM_ SG_ 1124 PSD_Sys_Laendercode "Ländercode
";
CM_ SG_ 1124 PSD_Sys_Mapmatchingguete "Güte des Mapmatchings";
CM_ SG_ 1124 PSD_Sys_Quali_Geometrien "Qualität der Geometrien in dieser Region";
CM_ SG_ 1124 PSD_Sys_Quali_Ortsinfo "Qualität Ortsinformationen (Bebauung, Ortsschild) dieser Region";
CM_ SG_ 1124 PSD_Sys_Quali_sonstige_Attribute "Qualität sonstiger Attribute dieser Region";
CM_ SG_ 1124 PSD_Sys_Quali_Steigungen "Qualität der Steigungen dieser Region";
CM_ SG_ 1124 PSD_Sys_Quali_Strassenkennz "Qualität Straßenkennzeichnungen dieser Region";
CM_ SG_ 1124 PSD_Sys_Quali_Tempolimits "Qualität Tempolimits dieser Region";
CM_ SG_ 1124 PSD_Sys_Quali_verfuegbar "Karte enthält gültige Qualitätskriterien";
CM_ SG_ 1124 PSD_Sys_Quali_Vorfahrtsregelung "Qualität Vorfahrtsregelungen dieser Region";
CM_ SG_ 1124 PSD_Sys_Segment_ID "Identifier des prädiktiven Streckensegments ab dem die Systeminformationen gültig sind.
";
CM_ SG_ 1124 PSD_Sys_US_State "Name des USA-State";
CM_ SG_ 1124 PSD_Sys_Verkehrsrichtung "Unterscheidung zwischen Linksverkehr und Rechtsverkehr";
CM_ SG_ 1124 PSD_Sys_Zielfuehrung "Zielfuehrung im Navigationssystem. Damit lässt sich der wahrscheinlichste Pfad des Fahrzeuges zuverlässig angeben.";
CM_ SG_ 1124 PSD_Sys_Zielfuehrung_geaendert "Die Zielführung (Route) hat sich geändert hat ohne dass der Fahrer eine neue Zielführung gestartet hat";
CM_ SG_ 1124 PSD_Wechselverkehrszeichen_Typ "Typ des Wechselverkehrszeichen";
BA_DEF_REL_ BU_SG_REL_  "GenSigTimeoutTime" INT 0 65535;
BA_DEF_ BO_  "DiagRequest" ENUM "No", "Yes";
BA_DEF_ BO_  "DiagResponse" ENUM "No", "Yes";
BA_DEF_ BO_  "DiagState" ENUM "No", "Yes";
BA_DEF_ BO_  "GenMsgChkConstant" HEX 0 4095;
BA_DEF_ BO_  "GenMsgCycleTime" INT 0 65535;
BA_DEF_ BO_  "GenMsgCycleTimeFast" INT 0 65535;
BA_DEF_ BO_  "GenMsgDelayTime" INT 0 100000;
BA_DEF_ BO_  "GenMsgILSupport" ENUM "No", "Yes";
BA_DEF_ BO_  "GenMsgNrOfRepetition" INT 0 100;
BA_DEF_ BO_  "GenMsgPDUConstants" STRING;
BA_DEF_ BO_  "GenMsgSendType" ENUM "Cyclic", "not_used", "not_used", "not_used", "not_used", "not_used", "not_used", "IfActive", "NoMsgSendType";
BA_DEF_ BO_  "GenMsgStartDelayTime" INT 0 100000;
BA_DEF_ BO_  "NmMessage" ENUM "No", "Yes";
BA_DEF_ BO_  "NmhMessage" ENUM "No", "Yes";
BA_DEF_ BO_  "MsgType" ENUM "Application", "NM ", "NMH", "TP2.0", "ISO-TP ", "BAP", "EID", "KS", "XCP_PRE_CONFIGURED", "XCP_RUNTIME_CONFIGURED";
BA_DEF_ BO_  "VAGTP20_API" HEX 0 255;
BA_DEF_ BO_  "VAGTP20_DynConnection" ENUM "No", "Yes";
BA_DEF_ BO_  "VAGTP20_DynSetup" ENUM "No", "Yes";
BA_DEF_ BO_  "VAGTP20_StatConnection" ENUM "No", "Yes";
BA_DEF_ SG_  "GenSigActiveRepetitions" INT -2147483648 2147483647;
BA_DEF_ SG_  "GenSigInactiveValue" INT -2147483648 2147483647;
BA_DEF_ SG_  "GenSigSendType" ENUM "Cyclic", "OnWrite", "OnWriteWithRepetition", "OnChange", "OnChangeWithRepetition", "IfActive", "IfActiveWithRepetition", "NoSigSendType", "OnChangeAndIfActive", "OnChangeAndIfActiveWithRepetition";
BA_DEF_ SG_  "GenSigStartValue" INT -2147483648 2147483647;
BA_DEF_ SG_  "NWM-WakeupAllowed" ENUM "No", "Yes";
BA_DEF_ SG_  "GenSigFuncType" ENUM "NoFunction", "MsgCounter", "CRC-8", "XOR", "XOR-2", "DatedBit", "SW-Kl15", "CHK", "Constant", "Protocol", "CRC-8-SAE_J1850", "CRC-32", "DataLength", "DataID", "MsgCounter16", "SOK-Signatur", "Cluster";
BA_DEF_ SG_  "GenSigSwitchedByIgnition" ENUM "No", "Yes";
BA_DEF_ SG_  "Fehlerwert" HEX 0 2147483647;
BA_DEF_ SG_  "GenSigMissingSourceValue" HEX 0 2147483647;
BA_DEF_DEF_REL_  "GenSigTimeoutTime" 0;
BA_DEF_DEF_  "DiagRequest" "No";
BA_DEF_DEF_  "DiagResponse" "No";
BA_DEF_DEF_  "DiagState" "No";
BA_DEF_DEF_  "GenMsgChkConstant" 0;
BA_DEF_DEF_  "GenMsgCycleTime" 0;
BA_DEF_DEF_  "GenMsgCycleTimeFast" 0;
BA_DEF_DEF_  "GenMsgDelayTime" 0;
BA_DEF_DEF_  "GenMsgILSupport" "No";
BA_DEF_DEF_  "GenMsgNrOfRepetition" 0;
BA_DEF_DEF_  "GenMsgPDUConstants" "";
BA_DEF_DEF_  "GenMsgSendType" "NoMsgSendType";
BA_DEF_DEF_  "GenMsgStartDelayTime" 0;
BA_DEF_DEF_  "NmMessage" "No";
BA_DEF_DEF_  "NmhMessage" "No";
BA_DEF_DEF_  "MsgType" "Application";
BA_DEF_DEF_  "VAGTP20_API" 0;
BA_DEF_DEF_  "VAGTP20_DynConnection" "No";
BA_DEF_DEF_  "VAGTP20_DynSetup" "No";
BA_DEF_DEF_  "VAGTP20_StatConnection" "No";
BA_DEF_DEF_  "GenSigActiveRepetitions" 0;
BA_DEF_DEF_  "GenSigInactiveValue" 0;
BA_DEF_DEF_  "GenSigSendType" "NoSigSendType";
BA_DEF_DEF_  "GenSigStartValue" 0;
BA_DEF_DEF_  "NWM-WakeupAllowed" "No";
BA_DEF_DEF_  "GenSigFuncType" "NoFunction";
BA_DEF_DEF_  "GenSigSwitchedByIgnition" "Yes";
BA_DEF_DEF_  "Fehlerwert" 0;
BA_DEF_DEF_  "GenSigMissingSourceValue" 0;
BA_ "GenMsgCycleTime" BO_ 2527679670 1000;
BA_ "GenMsgCycleTimeFast" BO_ 2527679670 200;
BA_ "GenMsgDelayTime" BO_ 2527679670 100;
BA_ "GenMsgILSupport" BO_ 2527679670 1;
BA_ "GenMsgNrOfRepetition" BO_ 2527679670 5;
BA_ "GenMsgSendType" BO_ 2527679670 0;
BA_ "GenMsgCycleTime" BO_ 908 100;
BA_ "GenMsgILSupport" BO_ 908 1;
BA_ "GenMsgSendType" BO_ 908 0;
BA_ "GenMsgCycleTime" BO_ 233 320;
BA_ "GenMsgDelayTime" BO_ 233 20;
BA_ "GenMsgILSupport" BO_ 233 1;
BA_ "GenMsgSendType" BO_ 233 0;
BA_ "GenMsgCycleTime" BO_ 2463978635 320;
BA_ "GenMsgDelayTime" BO_ 2463978635 20;
BA_ "GenMsgILSupport" BO_ 2463978635 1;
BA_ "GenMsgSendType" BO_ 2463978635 0;
BA_ "GenMsgCycleTime" BO_ 850 80;
BA_ "GenMsgILSupport" BO_ 850 1;
BA_ "GenMsgSendType" BO_ 850 0;
BA_ "GenMsgCycleTime" BO_ 872 100;
BA_ "GenMsgDelayTime" BO_ 872 40;
BA_ "GenMsgILSupport" BO_ 872 1;
BA_ "GenMsgSendType" BO_ 872 0;
BA_ "GenMsgCycleTime" BO_ 1175 100;
BA_ "GenMsgDelayTime" BO_ 1175 50;
BA_ "GenMsgILSupport" BO_ 1175 1;
BA_ "GenMsgSendType" BO_ 1175 0;
BA_ "GenMsgCycleTime" BO_ 1355 500;
BA_ "GenMsgDelayTime" BO_ 1355 20;
BA_ "GenMsgILSupport" BO_ 1355 1;
BA_ "GenMsgSendType" BO_ 1355 0;
BA_ "GenMsgCycleTime" BO_ 803 200;
BA_ "GenMsgDelayTime" BO_ 803 20;
BA_ "GenMsgILSupport" BO_ 803 1;
BA_ "GenMsgPDUConstants" BO_ 803 "0xa4,0x8b,0xda,0x66,0xdf,0x26,0xe0,0x4a,0x17,0x4d,0xbf,0xe3,0x47,0x2f,0x2a,0x06";
BA_ "GenMsgSendType" BO_ 803 0;
BA_ "GenMsgStartDelayTime" BO_ 803 160;
BA_ "GenMsgCycleTime" BO_ 2527679498 1000;
BA_ "GenMsgCycleTimeFast" BO_ 2527679498 200;
BA_ "GenMsgDelayTime" BO_ 2527679498 50;
BA_ "GenMsgILSupport" BO_ 2527679498 1;
BA_ "GenMsgNrOfRepetition" BO_ 2527679498 3;
BA_ "GenMsgSendType" BO_ 2527679498 0;
BA_ "GenMsgCycleTime" BO_ 2463978756 1000;
BA_ "GenMsgDelayTime" BO_ 2463978756 20;
BA_ "GenMsgILSupport" BO_ 2463978756 1;
BA_ "GenMsgSendType" BO_ 2463978756 0;
BA_ "GenMsgCycleTime" BO_ 381 1000;
BA_ "GenMsgILSupport" BO_ 381 1;
BA_ "GenMsgPDUConstants" BO_ 381 "0x5c,0x22,0x35,0xcc,0xf5,0x0b,0x9b,0xf7,0xc0,0x40,0xa6,0xa5,0xde,0x62,0x1c,0xac";
BA_ "GenMsgSendType" BO_ 381 0;
BA_ "GenMsgStartDelayTime" BO_ 381 720;
BA_ "GenMsgChkConstant" BO_ 304 49;
BA_ "GenMsgCycleTime" BO_ 304 1000;
BA_ "GenMsgCycleTimeFast" BO_ 304 20;
BA_ "GenMsgDelayTime" BO_ 304 20;
BA_ "GenMsgILSupport" BO_ 304 1;
BA_ "GenMsgNrOfRepetition" BO_ 304 5;
BA_ "GenMsgPDUConstants" BO_ 304 "0x31,0x31,0x31,0x31,0x31,0x31,0x31,0x31,0x31,0x31,0x31,0x31,0x31,0x31,0x31,0x31";
BA_ "GenMsgSendType" BO_ 304 0;
BA_ "GenMsgCycleTime" BO_ 2589283731 1000;
BA_ "GenMsgILSupport" BO_ 2589283731 1;
BA_ "GenMsgSendType" BO_ 2589283731 0;
BA_ "GenMsgCycleTime" BO_ 2589283732 1000;
BA_ "GenMsgILSupport" BO_ 2589283732 1;
BA_ "GenMsgSendType" BO_ 2589283732 0;
BA_ "GenMsgCycleTime" BO_ 1166 100;
BA_ "GenMsgILSupport" BO_ 1166 1;
BA_ "GenMsgSendType" BO_ 1166 0;
BA_ "GenMsgCycleTime" BO_ 1122 150;
BA_ "GenMsgILSupport" BO_ 1122 1;
BA_ "GenMsgSendType" BO_ 1122 0;
BA_ "GenMsgCycleTime" BO_ 1123 150;
BA_ "GenMsgILSupport" BO_ 1123 1;
BA_ "GenMsgSendType" BO_ 1123 0;
BA_ "GenMsgStartDelayTime" BO_ 1123 50;
BA_ "GenMsgCycleTime" BO_ 1124 150;
BA_ "GenMsgILSupport" BO_ 1124 1;
BA_ "GenMsgSendType" BO_ 1124 0;
BA_ "GenMsgStartDelayTime" BO_ 1124 100;
BA_ "GenSigActiveRepetitions" SG_ 2527679670 ORU_EM_Anfrage_Flashdauer 5;
BA_ "GenSigSendType" SG_ 2527679670 ORU_EM_Anfrage_Flashdauer 4;
BA_ "GenSigSwitchedByIgnition" SG_ 2527679670 ORU_EM_Anfrage_Flashdauer 0;
BA_ "GenSigActiveRepetitions" SG_ 2527679670 ORU_EM_Anfrage_freigegebeneNetze 5;
BA_ "GenSigSendType" SG_ 2527679670 ORU_EM_Anfrage_freigegebeneNetze 4;
BA_ "GenSigSwitchedByIgnition" SG_ 2527679670 ORU_EM_Anfrage_freigegebeneNetze 0;
BA_ "GenSigActiveRepetitions" SG_ 2527679670 ORU_EM_Anfrage_Stromaufnahme 5;
BA_ "GenSigSendType" SG_ 2527679670 ORU_EM_Anfrage_Stromaufnahme 4;
BA_ "GenSigSwitchedByIgnition" SG_ 2527679670 ORU_EM_Anfrage_Stromaufnahme 0;
BA_ "GenSigActiveRepetitions" SG_ 2527679670 ORU_Status_Anf 5;
BA_ "GenSigSendType" SG_ 2527679670 ORU_Status_Anf 4;
BA_ "GenSigSwitchedByIgnition" SG_ 2527679670 ORU_Status_Anf 0;
BA_ "GenSigSendType" SG_ 2527679670 OTA_FC_FahrwerkAnf 0;
BA_ "GenSigSwitchedByIgnition" SG_ 2527679670 OTA_FC_FahrwerkAnf 0;
BA_ "GenSigSendType" SG_ 2527679670 OTA_FC_FoD_Stornierung 3;
BA_ "GenSigActiveRepetitions" SG_ 2527679670 OTA_FC_Hinweis_Update 5;
BA_ "GenSigSendType" SG_ 2527679670 OTA_FC_Hinweis_Update 4;
BA_ "GenSigSwitchedByIgnition" SG_ 2527679670 OTA_FC_Hinweis_Update 0;
BA_ "GenSigActiveRepetitions" SG_ 2527679670 OTA_FC_IOF_Ausfall 5;
BA_ "GenSigSendType" SG_ 2527679670 OTA_FC_IOF_Ausfall 4;
BA_ "GenSigSwitchedByIgnition" SG_ 2527679670 OTA_FC_IOF_Ausfall 0;
BA_ "GenSigSendType" SG_ 2527679670 OTA_FC_LiftAnf 0;
BA_ "GenSigSwitchedByIgnition" SG_ 2527679670 OTA_FC_LiftAnf 0;
BA_ "GenSigSendType" SG_ 2527679670 OTA_FC_NiveauAnf 0;
BA_ "GenSigSwitchedByIgnition" SG_ 2527679670 OTA_FC_NiveauAnf 0;
BA_ "GenSigActiveRepetitions" SG_ 2527679670 OTA_FC_PredMaint_Ausfall 5;
BA_ "GenSigSendType" SG_ 2527679670 OTA_FC_PredMaint_Ausfall 4;
BA_ "GenSigSwitchedByIgnition" SG_ 2527679670 OTA_FC_PredMaint_Ausfall 0;
BA_ "GenSigActiveRepetitions" SG_ 2527679670 OTA_FC_Warnung_Update 5;
BA_ "GenSigSendType" SG_ 2527679670 OTA_FC_Warnung_Update 4;
BA_ "GenSigSwitchedByIgnition" SG_ 2527679670 OTA_FC_Warnung_Update 0;
BA_ "GenSigSendType" SG_ 908 PACC_Automode 0;
BA_ "GenSigStartValue" SG_ 908 PACC_Automode 1;
BA_ "GenSigSwitchedByIgnition" SG_ 908 PACC_Automode 0;
BA_ "GenSigSendType" SG_ 908 PACC_Durchschnittsgeschw 0;
BA_ "GenSigSendType" SG_ 908 PACC_naechstes_Event 0;
BA_ "GenSigSendType" SG_ 908 PACC_Offset 0;
BA_ "GenSigStartValue" SG_ 908 PACC_Offset 255;
BA_ "GenSigSendType" SG_ 908 PACC_Segelanteil 0;
BA_ "GenSigSendType" SG_ 908 PACC_Sollgeschwindigkeit 0;
BA_ "GenSigSendType" SG_ 908 PACC_Systemstatus 0;
BA_ "GenSigSendType" SG_ 908 PACC_Sytemstatus_Anzeige 0;
BA_ "GenSigSwitchedByIgnition" SG_ 908 PACC_Sytemstatus_Anzeige 0;
BA_ "GenSigSendType" SG_ 908 PACC_Uebernahmeaufforderung 0;
BA_ "GenSigSendType" SG_ 908 PACC_Vorausschaugeschw 0;
BA_ "GenSigStartValue" SG_ 908 PACC_Vorausschaugeschw 1023;
BA_ "GenSigSendType" SG_ 233 Parken_Aktives_Bedienelement 3;
BA_ "GenSigSwitchedByIgnition" SG_ 233 Parken_Aktives_Bedienelement 0;
BA_ "GenSigSendType" SG_ 233 Parken_Anhaltegrund 3;
BA_ "GenSigSwitchedByIgnition" SG_ 233 Parken_Anhaltegrund 0;
BA_ "GenSigSendType" SG_ 233 Parken_Anhaltegrund_ext 3;
BA_ "GenSigSwitchedByIgnition" SG_ 233 Parken_Anhaltegrund_ext 0;
BA_ "GenSigSendType" SG_ 233 Parken_BT_Wunsch 3;
BA_ "GenSigSwitchedByIgnition" SG_ 233 Parken_BT_Wunsch 0;
BA_ "GenSigSendType" SG_ 233 Parken_Fahrtaster_Empfehlung 3;
BA_ "GenSigSwitchedByIgnition" SG_ 233 Parken_Fahrtaster_Empfehlung 0;
BA_ "GenSigSendType" SG_ 233 Parken_FFB_Status 3;
BA_ "GenSigSwitchedByIgnition" SG_ 233 Parken_FFB_Status 0;
BA_ "GenSigSendType" SG_ 233 Parken_Fortschrittszaehler 3;
BA_ "GenSigStartValue" SG_ 233 Parken_Fortschrittszaehler 127;
BA_ "GenSigSwitchedByIgnition" SG_ 233 Parken_Fortschrittszaehler 0;
BA_ "GenSigSendType" SG_ 233 Parken_Funktionsstatus 3;
BA_ "GenSigSwitchedByIgnition" SG_ 233 Parken_Funktionsstatus 0;
BA_ "GenSigSendType" SG_ 233 Parken_Hindernis_Bereich 3;
BA_ "GenSigSwitchedByIgnition" SG_ 233 Parken_Hindernis_Bereich 0;
BA_ "GenSigSendType" SG_ 233 Parken_Hindernis_erkannt 3;
BA_ "GenSigSwitchedByIgnition" SG_ 233 Parken_Hindernis_erkannt 0;
BA_ "GenSigSendType" SG_ 233 Parken_Manoever 3;
BA_ "GenSigSwitchedByIgnition" SG_ 233 Parken_Manoever 0;
BA_ "GenSigSendType" SG_ 233 Parken_Manoever_Aktiv 3;
BA_ "GenSigSwitchedByIgnition" SG_ 233 Parken_Manoever_Aktiv 0;
BA_ "GenSigSendType" SG_ 233 Parken_Reversieren_moeglich 3;
BA_ "GenSigSwitchedByIgnition" SG_ 233 Parken_Reversieren_moeglich 0;
BA_ "GenSigSendType" SG_ 233 Parken_Richtung 3;
BA_ "GenSigSwitchedByIgnition" SG_ 233 Parken_Richtung 0;
BA_ "GenSigSendType" SG_ 233 Parken_Richtung_Aktiv 3;
BA_ "GenSigSwitchedByIgnition" SG_ 233 Parken_Richtung_Aktiv 0;
BA_ "GenSigSendType" SG_ 233 Parken_Seite 3;
BA_ "GenSigSwitchedByIgnition" SG_ 233 Parken_Seite 0;
BA_ "GenSigSendType" SG_ 233 Parken_Seite_Aktiv 3;
BA_ "GenSigSwitchedByIgnition" SG_ 233 Parken_Seite_Aktiv 0;
BA_ "GenSigSendType" SG_ 233 Parken_SM_Anhaenger 3;
BA_ "GenSigSwitchedByIgnition" SG_ 233 Parken_SM_Anhaenger 0;
BA_ "GenSigSendType" SG_ 233 Parken_SM_Fahrbereitschaft 3;
BA_ "GenSigSwitchedByIgnition" SG_ 233 Parken_SM_Fahrbereitschaft 0;
BA_ "GenSigSendType" SG_ 233 Parken_SM_Fahrstufe 3;
BA_ "GenSigSwitchedByIgnition" SG_ 233 Parken_SM_Fahrstufe 0;
BA_ "GenSigSendType" SG_ 233 Parken_SM_Schluessel 3;
BA_ "GenSigSwitchedByIgnition" SG_ 233 Parken_SM_Schluessel 0;
BA_ "GenSigSendType" SG_ 233 Parken_SM_Sensor 3;
BA_ "GenSigSwitchedByIgnition" SG_ 233 Parken_SM_Sensor 0;
BA_ "GenSigSendType" SG_ 233 Parken_SM_Stillstand 3;
BA_ "GenSigSwitchedByIgnition" SG_ 233 Parken_SM_Stillstand 0;
BA_ "GenSigSendType" SG_ 233 Parken_SM_Tueren 3;
BA_ "GenSigSwitchedByIgnition" SG_ 233 Parken_SM_Tueren 0;
BA_ "GenSigSendType" SG_ 233 Parken_Szenario 3;
BA_ "GenSigSwitchedByIgnition" SG_ 233 Parken_Szenario 0;
BA_ "GenSigSendType" SG_ 233 Parken_Szenario_Aktiv 3;
BA_ "GenSigSwitchedByIgnition" SG_ 233 Parken_Szenario_Aktiv 0;
BA_ "GenSigSendType" SG_ 233 Parken_Touchdiagnose_Anf 3;
BA_ "GenSigSwitchedByIgnition" SG_ 233 Parken_Touchdiagnose_Anf 0;
BA_ "GenSigSendType" SG_ 2463978635 Parken_Traj_aktueller_Zug 3;
BA_ "GenSigSwitchedByIgnition" SG_ 2463978635 Parken_Traj_aktueller_Zug 0;
BA_ "GenSigSendType" SG_ 2463978635 Parken_Traj_Anzahl_Punkte 3;
BA_ "GenSigSwitchedByIgnition" SG_ 2463978635 Parken_Traj_Anzahl_Punkte 0;
BA_ "GenSigSendType" SG_ 2463978635 Parken_Traj_Fahrtrichtung 3;
BA_ "GenSigSwitchedByIgnition" SG_ 2463978635 Parken_Traj_Fahrtrichtung 0;
BA_ "GenSigSendType" SG_ 2463978635 Parken_Traj_Fzg_Pos_X 3;
BA_ "GenSigSwitchedByIgnition" SG_ 2463978635 Parken_Traj_Fzg_Pos_X 0;
BA_ "GenSigSendType" SG_ 2463978635 Parken_Traj_Fzg_Pos_Y 3;
BA_ "GenSigSwitchedByIgnition" SG_ 2463978635 Parken_Traj_Fzg_Pos_Y 0;
BA_ "GenSigSendType" SG_ 2463978635 Parken_Traj_Fzg_Winkel 3;
BA_ "GenSigSwitchedByIgnition" SG_ 2463978635 Parken_Traj_Fzg_Winkel 0;
BA_ "GenSigSendType" SG_ 2463978635 Parken_Traj_letzter_Zug 3;
BA_ "GenSigSwitchedByIgnition" SG_ 2463978635 Parken_Traj_letzter_Zug 0;
BA_ "GenSigSendType" SG_ 2463978635 Parken_Traj_Trans_ID 3;
BA_ "GenSigSwitchedByIgnition" SG_ 2463978635 Parken_Traj_Trans_ID 0;
BA_ "GenSigSendType" SG_ 850 Parken_SM_03_MUX 0;
BA_ "GenSigSwitchedByIgnition" SG_ 850 Parken_SM_03_MUX 0;
BA_ "GenSigSwitchedByIgnition" SG_ 850 Parken_SM_03_Traj_Trans_ID_00 0;
BA_ "GenSigSwitchedByIgnition" SG_ 850 Parken_SM_03_Traj_Trans_ID_01 0;
BA_ "GenSigSwitchedByIgnition" SG_ 850 Parken_SM_03_Traj_Trans_ID_02 0;
BA_ "GenSigSwitchedByIgnition" SG_ 850 Parken_SM_03_Traj_Trans_ID_03 0;
BA_ "GenSigSwitchedByIgnition" SG_ 850 Parken_SM_03_Traj_Trans_ID_04 0;
BA_ "GenSigSwitchedByIgnition" SG_ 850 Parken_SM_03_Traj_Trans_ID_05 0;
BA_ "GenSigSwitchedByIgnition" SG_ 850 Parken_SM_03_Traj_Trans_ID_06 0;
BA_ "GenSigSwitchedByIgnition" SG_ 850 Parken_Traj_P1_Pos_X 0;
BA_ "GenSigSwitchedByIgnition" SG_ 850 Parken_Traj_P1_Pos_Y 0;
BA_ "GenSigSwitchedByIgnition" SG_ 850 Parken_Traj_P1_Tangent 0;
BA_ "GenSigSwitchedByIgnition" SG_ 850 Parken_Traj_P2_Pos_X 0;
BA_ "GenSigSwitchedByIgnition" SG_ 850 Parken_Traj_P2_Pos_Y 0;
BA_ "GenSigSwitchedByIgnition" SG_ 850 Parken_Traj_P2_Tangent 0;
BA_ "GenSigSwitchedByIgnition" SG_ 850 Parken_Traj_P3_Pos_X 0;
BA_ "GenSigSwitchedByIgnition" SG_ 850 Parken_Traj_P3_Pos_Y 0;
BA_ "GenSigSwitchedByIgnition" SG_ 850 Parken_Traj_P3_Tangent 0;
BA_ "GenSigSwitchedByIgnition" SG_ 850 Parken_Traj_P4_Pos_X 0;
BA_ "GenSigSwitchedByIgnition" SG_ 850 Parken_Traj_P4_Pos_Y 0;
BA_ "GenSigSwitchedByIgnition" SG_ 850 Parken_Traj_P4_Tangent 0;
BA_ "GenSigSwitchedByIgnition" SG_ 850 Parken_Traj_P5_Pos_X 0;
BA_ "GenSigSwitchedByIgnition" SG_ 850 Parken_Traj_P5_Pos_Y 0;
BA_ "GenSigSwitchedByIgnition" SG_ 850 Parken_Traj_P5_Tangent 0;
BA_ "GenSigSwitchedByIgnition" SG_ 850 Parken_Traj_P6_Pos_X 0;
BA_ "GenSigSwitchedByIgnition" SG_ 850 Parken_Traj_P6_Pos_Y 0;
BA_ "GenSigSwitchedByIgnition" SG_ 850 Parken_Traj_P6_Tangent 0;
BA_ "GenSigSwitchedByIgnition" SG_ 850 Parken_Traj_P7_Pos_X 0;
BA_ "GenSigSwitchedByIgnition" SG_ 850 Parken_Traj_P7_Pos_Y 0;
BA_ "GenSigSwitchedByIgnition" SG_ 850 Parken_Traj_P7_Tangent 0;
BA_ "GenSigSwitchedByIgnition" SG_ 850 Parken_Traj_P8_Pos_X 0;
BA_ "GenSigSwitchedByIgnition" SG_ 850 Parken_Traj_P8_Pos_Y 0;
BA_ "GenSigSwitchedByIgnition" SG_ 850 Parken_Traj_P8_Tangent 0;
BA_ "GenSigSwitchedByIgnition" SG_ 850 Parken_Traj_P9_Pos_X 0;
BA_ "GenSigSwitchedByIgnition" SG_ 850 Parken_Traj_P9_Pos_Y 0;
BA_ "GenSigSwitchedByIgnition" SG_ 850 Parken_Traj_P9_Tangent 0;
BA_ "GenSigSendType" SG_ 872 PDC2_Tonausgabe_Front 3;
BA_ "GenSigSendType" SG_ 872 PDC2_Tonausgabe_Heck 3;
BA_ "GenSigSendType" SG_ 872 PH2_Abschaltursache 3;
BA_ "GenSigSendType" SG_ 872 PH2_Anf_Audioabsenkung 3;
BA_ "GenSigSendType" SG_ 872 PH2_Anf_Verdeck 3;
BA_ "GenSigSendType" SG_ 872 PH2_defekt 3;
BA_ "GenSigSendType" SG_ 872 PH2_Display_Kundenwunsch 3;
BA_ "GenSigSendType" SG_ 872 PH2_Frequenz_hinten 3;
BA_ "GenSigSendType" SG_ 872 PH2_Frequenz_vorn 3;
BA_ "GenSigSendType" SG_ 872 PH2_gestoert 3;
BA_ "GenSigSendType" SG_ 872 PH2_Lautstaerke_hinten 3;
BA_ "GenSigSendType" SG_ 872 PH2_Lautstaerke_vorn 3;
BA_ "GenSigSendType" SG_ 872 PH2_nachtr_Stopp_An 3;
BA_ "GenSigSendType" SG_ 872 PH2_Opt_Anz_H_Hindernis 3;
BA_ "GenSigSendType" SG_ 872 PH2_Opt_Anz_V_Hindernis 3;
BA_ "GenSigSendType" SG_ 872 PH2_Opt_Anzeige_H_ein 3;
BA_ "GenSigSendType" SG_ 872 PH2_Opt_Anzeige_V_ein 3;
BA_ "GenSigSendType" SG_ 872 PH2_StartStopp_Info 3;
BA_ "GenSigSendType" SG_ 872 PH2_Stoermeldung 3;
BA_ "GenSigSendType" SG_ 872 PH2_Systemzustand 3;
BA_ "GenSigSendType" SG_ 872 PH2_Taster 3;
BA_ "Fehlerwert" SG_ 872 PH2_Taster 3;
BA_ "GenSigSendType" SG_ 872 PH2_Tongeber_H_aktiv 3;
BA_ "GenSigSendType" SG_ 872 PH2_Tongeber_H_verfuegbar 3;
BA_ "GenSigSendType" SG_ 872 PH2_Tongeber_mute 3;
BA_ "GenSigSendType" SG_ 872 PH2_Tongeber_V_aktiv 3;
BA_ "GenSigSendType" SG_ 872 PH2_Visualisierung 3;
BA_ "GenSigStartValue" SG_ 872 PH2_Visualisierung 6;
BA_ "Fehlerwert" SG_ 872 PH2_Visualisierung 7;
BA_ "GenSigSendType" SG_ 1175 PDC_Tonausgabe_Front 3;
BA_ "GenSigSendType" SG_ 1175 PDC_Tonausgabe_Heck 3;
BA_ "GenSigSendType" SG_ 1175 PH_Abschaltursache 3;
BA_ "GenSigSendType" SG_ 1175 PH_Anf_Audioabsenkung 3;
BA_ "GenSigSendType" SG_ 1175 PH_Anf_Verdeck 3;
BA_ "GenSigSendType" SG_ 1175 PH_defekt 3;
BA_ "GenSigSendType" SG_ 1175 PH_Display_Kundenwunsch 3;
BA_ "GenSigSendType" SG_ 1175 PH_Frequenz_hinten 3;
BA_ "GenSigSendType" SG_ 1175 PH_Frequenz_vorn 3;
BA_ "GenSigSendType" SG_ 1175 PH_gestoert 3;
BA_ "GenSigSendType" SG_ 1175 PH_Lautstaerke_hinten 3;
BA_ "GenSigSendType" SG_ 1175 PH_Lautstaerke_vorn 3;
BA_ "GenSigSendType" SG_ 1175 PH_nachtr_Stopp_Anf 3;
BA_ "GenSigSendType" SG_ 1175 PH_Opt_Anz_H_Hindernis 3;
BA_ "GenSigSendType" SG_ 1175 PH_Opt_Anz_V_Hindernis 3;
BA_ "GenSigSendType" SG_ 1175 PH_Opt_Anzeige_H_ein 3;
BA_ "GenSigSendType" SG_ 1175 PH_Opt_Anzeige_V_ein 3;
BA_ "GenSigSendType" SG_ 1175 PH_StartStopp_Info 3;
BA_ "GenSigSendType" SG_ 1175 PH_Stoermeldung 3;
BA_ "GenSigSendType" SG_ 1175 PH_Systemzustand 3;
BA_ "GenSigSendType" SG_ 1175 PH_Taster 3;
BA_ "Fehlerwert" SG_ 1175 PH_Taster 3;
BA_ "GenSigSendType" SG_ 1175 PH_Tongeber_H_aktiv 3;
BA_ "GenSigSendType" SG_ 1175 PH_Tongeber_H_verfuegbar 3;
BA_ "GenSigSendType" SG_ 1175 PH_Tongeber_mute 3;
BA_ "GenSigSendType" SG_ 1175 PH_Tongeber_V_aktiv 3;
BA_ "GenSigSendType" SG_ 1175 PH_Visualisierung 3;
BA_ "GenSigStartValue" SG_ 1175 PH_Visualisierung 6;
BA_ "Fehlerwert" SG_ 1175 PH_Visualisierung 7;
BA_ "GenSigSendType" SG_ 1175 PLA_Anf_Aufschaltung_RVC 3;
BA_ "GenSigSendType" SG_ 1355 BCM_WAH_Meldung 3;
BA_ "GenSigSendType" SG_ 1355 PDC_Charisma_FahrPr 3;
BA_ "GenSigSendType" SG_ 1355 PDC_Charisma_Status 3;
BA_ "GenSigSendType" SG_ 1355 PH_Aufschaltursache 3;
BA_ "GenSigSendType" SG_ 1355 PH_Ton_Ausgabe 3;
BA_ "Fehlerwert" SG_ 1355 PH_Ton_Ausgabe 7;
BA_ "GenSigSendType" SG_ 1355 PH_Ton_Lautstaerke 3;
BA_ "GenSigSendType" SG_ 1355 PH_Ton_Pausenlaenge 3;
BA_ "Fehlerwert" SG_ 1355 PH_Ton_Pausenlaenge 127;
BA_ "GenSigSendType" SG_ 1355 PH_Ton_Richtung 3;
BA_ "GenSigSendType" SG_ 1355 PH_Verschmutzungsmeldung 3;
BA_ "GenSigSendType" SG_ 803 PCF_01_BZ 0;
BA_ "GenSigFuncType" SG_ 803 PCF_01_BZ 1;
BA_ "GenSigSendType" SG_ 803 PCF_01_CRC 0;
BA_ "GenSigFuncType" SG_ 803 PCF_01_CRC 2;
BA_ "GenSigSendType" SG_ 803 PCF_HBA_Param 0;
BA_ "GenSigSwitchedByIgnition" SG_ 803 PCF_HBA_Param 0;
BA_ "GenSigSendType" SG_ 803 PCF_Prefill_Anf 3;
BA_ "GenSigSwitchedByIgnition" SG_ 803 PCF_Prefill_Anf 0;
BA_ "GenSigSendType" SG_ 803 PCF_Ruckprofil 0;
BA_ "GenSigSwitchedByIgnition" SG_ 803 PCF_Ruckprofil 0;
BA_ "GenSigSendType" SG_ 803 PCF_Verz_Anf 0;
BA_ "GenSigStartValue" SG_ 803 PCF_Verz_Anf 834;
BA_ "GenSigSendType" SG_ 803 PCF_Verz_Anf_ASIL 0;
BA_ "GenSigSwitchedByIgnition" SG_ 803 PCF_Verz_Anf_ASIL 0;
BA_ "GenSigSendType" SG_ 803 PCF_Verz_Auspraegung 0;
BA_ "GenSigSwitchedByIgnition" SG_ 803 PCF_Verz_Auspraegung 0;
BA_ "GenSigSendType" SG_ 803 PCF_Verz_Info 3;
BA_ "GenSigSwitchedByIgnition" SG_ 803 PCF_Verz_Info 0;
BA_ "GenSigSendType" SG_ 803 SC_AbstWarn_Texte 0;
BA_ "GenSigSwitchedByIgnition" SG_ 803 SC_AbstWarn_Texte 0;
BA_ "GenSigSendType" SG_ 803 SC_WarnBrems_Texte 0;
BA_ "GenSigSwitchedByIgnition" SG_ 803 SC_WarnBrems_Texte 0;
BA_ "GenSigSendType" SG_ 2527679498 IAA_Active_User_ID 0;
BA_ "GenSigSwitchedByIgnition" SG_ 2527679498 IAA_Active_User_ID 0;
BA_ "GenSigSendType" SG_ 2527679498 IAA_Identified_User_ID 0;
BA_ "GenSigSwitchedByIgnition" SG_ 2527679498 IAA_Identified_User_ID 0;
BA_ "GenSigSendType" SG_ 2527679498 IAA_PSO_wake_up 0;
BA_ "GenSigSwitchedByIgnition" SG_ 2527679498 IAA_PSO_wake_up 0;
BA_ "GenSigActiveRepetitions" SG_ 2527679498 Perso_Aktiv 3;
BA_ "GenSigSendType" SG_ 2527679498 Perso_Aktiv 4;
BA_ "GenSigSwitchedByIgnition" SG_ 2527679498 Perso_Aktiv 0;
BA_ "GenSigActiveRepetitions" SG_ 2527679498 Perso_Bedienstelle 3;
BA_ "GenSigSendType" SG_ 2527679498 Perso_Bedienstelle 4;
BA_ "GenSigSwitchedByIgnition" SG_ 2527679498 Perso_Bedienstelle 0;
BA_ "GenSigActiveRepetitions" SG_ 2527679498 Perso_Fahrernummer 3;
BA_ "GenSigSendType" SG_ 2527679498 Perso_Fahrernummer 4;
BA_ "GenSigSwitchedByIgnition" SG_ 2527679498 Perso_Fahrernummer 0;
BA_ "GenSigActiveRepetitions" SG_ 2527679498 Perso_Freigabe_Verstellung 3;
BA_ "GenSigSendType" SG_ 2527679498 Perso_Freigabe_Verstellung 4;
BA_ "GenSigSwitchedByIgnition" SG_ 2527679498 Perso_Freigabe_Verstellung 0;
BA_ "GenSigActiveRepetitions" SG_ 2527679498 Perso_Kontonummer 3;
BA_ "GenSigSendType" SG_ 2527679498 Perso_Kontonummer 4;
BA_ "GenSigSwitchedByIgnition" SG_ 2527679498 Perso_Kontonummer 0;
BA_ "GenSigActiveRepetitions" SG_ 2527679498 Perso_Schreibschutz 3;
BA_ "GenSigSendType" SG_ 2527679498 Perso_Schreibschutz 4;
BA_ "GenSigSwitchedByIgnition" SG_ 2527679498 Perso_Schreibschutz 0;
BA_ "GenSigSendType" SG_ 2527679498 Perso_Status 1;
BA_ "GenSigSwitchedByIgnition" SG_ 2527679498 Perso_Status 0;
BA_ "GenSigActiveRepetitions" SG_ 2527679498 Perso_Steuerung 3;
BA_ "GenSigSendType" SG_ 2527679498 Perso_Steuerung 4;
BA_ "GenSigSwitchedByIgnition" SG_ 2527679498 Perso_Steuerung 0;
BA_ "GenSigActiveRepetitions" SG_ 2527679498 Perso_Steuerungsparameter 3;
BA_ "GenSigSendType" SG_ 2527679498 Perso_Steuerungsparameter 4;
BA_ "GenSigSwitchedByIgnition" SG_ 2527679498 Perso_Steuerungsparameter 0;
BA_ "GenSigSendType" SG_ 2463978756 PSO_last_rec_UserID_Src1 3;
BA_ "GenSigSwitchedByIgnition" SG_ 2463978756 PSO_last_rec_UserID_Src1 0;
BA_ "GenSigSendType" SG_ 381 PLA2_01_BZ 0;
BA_ "GenSigFuncType" SG_ 381 PLA2_01_BZ 1;
BA_ "GenSigSendType" SG_ 381 PLA2_01_CRC 0;
BA_ "GenSigFuncType" SG_ 381 PLA2_01_CRC 2;
BA_ "GenSigSendType" SG_ 381 PLA2_Anhalteweg 0;
BA_ "GenSigStartValue" SG_ 381 PLA2_Anhalteweg 2046;
BA_ "GenSigSwitchedByIgnition" SG_ 381 PLA2_Anhalteweg 0;
BA_ "Fehlerwert" SG_ 381 PLA2_Anhalteweg 2047;
BA_ "GenSigSendType" SG_ 381 PLA2_Status_PLA_EPS 0;
BA_ "GenSigStartValue" SG_ 381 PLA2_Status_PLA_EPS 9;
BA_ "GenSigSendType" SG_ 381 PLA2_VZ_Zahnstangen_Pos_Soll 0;
BA_ "GenSigSwitchedByIgnition" SG_ 381 PLA2_VZ_Zahnstangen_Pos_Soll 0;
BA_ "GenSigSendType" SG_ 381 PLA2_Zahnstangen_Pos_Soll 0;
BA_ "GenSigSendType" SG_ 304 PLA_01_BZ 0;
BA_ "GenSigFuncType" SG_ 304 PLA_01_BZ 1;
BA_ "GenSigSendType" SG_ 304 PLA_01_CRC 0;
BA_ "GenSigFuncType" SG_ 304 PLA_01_CRC 2;
BA_ "GenSigActiveRepetitions" SG_ 304 PLA_01_Signal_red_cyclic 5;
BA_ "GenSigSendType" SG_ 304 PLA_01_Signal_red_cyclic 9;
BA_ "GenSigSendType" SG_ 304 PLA_Anf_Bremsverzoegerung 0;
BA_ "GenSigSendType" SG_ 304 PLA_BremsMom_Verzoeg 3;
BA_ "GenSigSendType" SG_ 304 PLA_Bremsverzoegerung 3;
BA_ "GenSigStartValue" SG_ 304 PLA_Bremsverzoegerung 126;
BA_ "Fehlerwert" SG_ 304 PLA_Bremsverzoegerung 127;
BA_ "GenSigSendType" SG_ 304 PLA_Status_PLA_EPS 0;
BA_ "GenSigStartValue" SG_ 304 PLA_Status_PLA_EPS 9;
BA_ "GenSigSendType" SG_ 304 PLA_Status_PLA_ESP 0;
BA_ "GenSigStartValue" SG_ 304 PLA_Status_PLA_ESP 9;
BA_ "GenSigSendType" SG_ 304 PLA_VZ_Zahnstangen_Pos_Soll 0;
BA_ "GenSigSendType" SG_ 304 PLA_Zahnstangen_Pos_Soll 0;
BA_ "GenSigStartValue" SG_ 304 PLA_Zahnstangen_Pos_Soll 4094;
BA_ "GenSigSendType" SG_ 2589283731 PLA_SDA_Aktive_Seite 0;
BA_ "GenSigSendType" SG_ 2589283731 PLA_SDA_Exist 0;
BA_ "GenSigSendType" SG_ 2589283731 PLA_SDA_Laengs_Querluecke 0;
BA_ "GenSigSendType" SG_ 2589283731 PLA_SDA_Li_ID_1 0;
BA_ "GenSigSwitchedByIgnition" SG_ 2589283731 PLA_SDA_Li_ID_1 0;
BA_ "GenSigSendType" SG_ 2589283731 PLA_SDA_Li_ID_2 0;
BA_ "GenSigSwitchedByIgnition" SG_ 2589283731 PLA_SDA_Li_ID_2 0;
BA_ "GenSigSendType" SG_ 2589283731 PLA_SDA_Li_ID_3 0;
BA_ "GenSigSwitchedByIgnition" SG_ 2589283731 PLA_SDA_Li_ID_3 0;
BA_ "GenSigSendType" SG_ 2589283731 PLA_SDA_Li_ID_4 0;
BA_ "GenSigSwitchedByIgnition" SG_ 2589283731 PLA_SDA_Li_ID_4 0;
BA_ "GenSigSendType" SG_ 2589283731 PLA_SDA_Li_ID_5 0;
BA_ "GenSigSwitchedByIgnition" SG_ 2589283731 PLA_SDA_Li_ID_5 0;
BA_ "GenSigSendType" SG_ 2589283731 PLA_SDA_Li_ID_6 0;
BA_ "GenSigSwitchedByIgnition" SG_ 2589283731 PLA_SDA_Li_ID_6 0;
BA_ "GenSigSendType" SG_ 2589283731 PLA_SDA_Li_ID_7 0;
BA_ "GenSigSwitchedByIgnition" SG_ 2589283731 PLA_SDA_Li_ID_7 0;
BA_ "GenSigSendType" SG_ 2589283731 PLA_SDA_Li_ID_8 0;
BA_ "GenSigSwitchedByIgnition" SG_ 2589283731 PLA_SDA_Li_ID_8 0;
BA_ "GenSigSendType" SG_ 2589283731 PLA_SDA_Li_Offset_1 0;
BA_ "GenSigSwitchedByIgnition" SG_ 2589283731 PLA_SDA_Li_Offset_1 0;
BA_ "GenSigSendType" SG_ 2589283731 PLA_SDA_Li_Offset_2 0;
BA_ "GenSigSwitchedByIgnition" SG_ 2589283731 PLA_SDA_Li_Offset_2 0;
BA_ "GenSigSendType" SG_ 2589283731 PLA_SDA_Li_Offset_3 0;
BA_ "GenSigSwitchedByIgnition" SG_ 2589283731 PLA_SDA_Li_Offset_3 0;
BA_ "GenSigSendType" SG_ 2589283731 PLA_SDA_Li_Offset_4 0;
BA_ "GenSigSwitchedByIgnition" SG_ 2589283731 PLA_SDA_Li_Offset_4 0;
BA_ "GenSigSendType" SG_ 2589283731 PLA_SDA_Li_Offset_5 0;
BA_ "GenSigSwitchedByIgnition" SG_ 2589283731 PLA_SDA_Li_Offset_5 0;
BA_ "GenSigSendType" SG_ 2589283731 PLA_SDA_Li_Offset_6 0;
BA_ "GenSigSwitchedByIgnition" SG_ 2589283731 PLA_SDA_Li_Offset_6 0;
BA_ "GenSigSendType" SG_ 2589283731 PLA_SDA_Li_Offset_7 0;
BA_ "GenSigSwitchedByIgnition" SG_ 2589283731 PLA_SDA_Li_Offset_7 0;
BA_ "GenSigSendType" SG_ 2589283731 PLA_SDA_Li_Offset_8 0;
BA_ "GenSigSwitchedByIgnition" SG_ 2589283731 PLA_SDA_Li_Offset_8 0;
BA_ "GenSigSendType" SG_ 2589283731 PLA_SDA_Status 0;
BA_ "GenSigSendType" SG_ 2589283732 PLA_SDA_Re_ID_1 0;
BA_ "GenSigSendType" SG_ 2589283732 PLA_SDA_Re_ID_2 0;
BA_ "GenSigSendType" SG_ 2589283732 PLA_SDA_Re_ID_3 0;
BA_ "GenSigSendType" SG_ 2589283732 PLA_SDA_Re_ID_4 0;
BA_ "GenSigSendType" SG_ 2589283732 PLA_SDA_Re_ID_5 0;
BA_ "GenSigSendType" SG_ 2589283732 PLA_SDA_Re_ID_6 0;
BA_ "GenSigSendType" SG_ 2589283732 PLA_SDA_Re_ID_7 0;
BA_ "GenSigSendType" SG_ 2589283732 PLA_SDA_Re_ID_8 0;
BA_ "GenSigSendType" SG_ 2589283732 PLA_SDA_Re_Offset_1 0;
BA_ "GenSigSendType" SG_ 2589283732 PLA_SDA_Re_Offset_2 0;
BA_ "GenSigSendType" SG_ 2589283732 PLA_SDA_Re_Offset_3 0;
BA_ "GenSigSendType" SG_ 2589283732 PLA_SDA_Re_Offset_4 0;
BA_ "GenSigSendType" SG_ 2589283732 PLA_SDA_Re_Offset_5 0;
BA_ "GenSigSendType" SG_ 2589283732 PLA_SDA_Re_Offset_6 0;
BA_ "GenSigSendType" SG_ 2589283732 PLA_SDA_Re_Offset_7 0;
BA_ "GenSigSendType" SG_ 2589283732 PLA_SDA_Re_Offset_8 0;
BA_ "GenSigSendType" SG_ 1166 PLA_Anf_Akustik 0;
BA_ "GenSigSendType" SG_ 1166 PLA_Anf_Anzeige_Bremsfuss 0;
BA_ "GenSigSendType" SG_ 1166 PLA_Anf_Anzeige_Mini 0;
BA_ "GenSigSendType" SG_ 1166 PLA_Anf_Anzeige_Schwellpfeil 0;
BA_ "GenSigSendType" SG_ 1166 PLA_Anf_Anzeigemodus 0;
BA_ "GenSigSendType" SG_ 1166 PLA_Anf_Meldungen 0;
BA_ "GenSigSendType" SG_ 1166 PLA_Anforderung_HMS 0;
BA_ "GenSigSendType" SG_ 1166 PLA_Anzahl_Segmente_Schwellpfeil 0;
BA_ "GenSigSendType" SG_ 1166 PLA_Mini_Modus 0;
BA_ "GenSigSendType" SG_ 1166 PLA_Status_Aktive_Seite 0;
BA_ "GenSigSendType" SG_ 1166 PLA_Status_beenden_Mini 0;
BA_ "GenSigSendType" SG_ 1166 PLA_Status_Funktion 0;
BA_ "GenSigSendType" SG_ 1166 PLA_Status_Laengsparken_Mini 0;
BA_ "GenSigSendType" SG_ 1166 PLA_Status_QP_Rueckw_Mini 0;
BA_ "GenSigSendType" SG_ 1166 PLA_Status_QP_Vorw_Mini 0;
BA_ "GenSigSendType" SG_ 1122 PSD_Abzweigerichtung 0;
BA_ "GenSigSwitchedByIgnition" SG_ 1122 PSD_Abzweigerichtung 0;
BA_ "GenSigSendType" SG_ 1122 PSD_Abzweigewinkel 0;
BA_ "GenSigSwitchedByIgnition" SG_ 1122 PSD_Abzweigewinkel 0;
BA_ "GenSigSendType" SG_ 1122 PSD_ADAS_Qualitaet 0;
BA_ "GenSigSendType" SG_ 1122 PSD_Anfangskruemmung 0;
BA_ "GenSigSwitchedByIgnition" SG_ 1122 PSD_Anfangskruemmung 0;
BA_ "GenSigSendType" SG_ 1122 PSD_Anfangskruemmung_Vorz 0;
BA_ "GenSigSwitchedByIgnition" SG_ 1122 PSD_Anfangskruemmung_Vorz 0;
BA_ "GenSigSendType" SG_ 1122 PSD_Bebauung 0;
BA_ "GenSigSendType" SG_ 1122 PSD_Endkruemmung 0;
BA_ "GenSigSendType" SG_ 1122 PSD_Endkruemmung_Vorz 0;
BA_ "GenSigSendType" SG_ 1122 PSD_Fahrspuren_Anzahl 0;
BA_ "GenSigStartValue" SG_ 1122 PSD_Fahrspuren_Anzahl 1;
BA_ "GenSigSwitchedByIgnition" SG_ 1122 PSD_Fahrspuren_Anzahl 0;
BA_ "GenSigSendType" SG_ 1122 PSD_Geradester_Pfad 0;
BA_ "GenSigSendType" SG_ 1122 PSD_Idenditaets_ID 0;
BA_ "Fehlerwert" SG_ 1122 PSD_Idenditaets_ID 1;
BA_ "GenSigSendType" SG_ 1122 PSD_Rampe 0;
BA_ "GenSigSendType" SG_ 1122 PSD_Segment_ID 0;
BA_ "GenSigSendType" SG_ 1122 PSD_Segment_Komplett 0;
BA_ "GenSigSwitchedByIgnition" SG_ 1122 PSD_Segment_Komplett 0;
BA_ "GenSigSendType" SG_ 1122 PSD_Segmentlaenge 0;
BA_ "GenSigSendType" SG_ 1122 PSD_Strassenkategorie 0;
BA_ "GenSigStartValue" SG_ 1122 PSD_Strassenkategorie 7;
BA_ "GenSigSwitchedByIgnition" SG_ 1122 PSD_Strassenkategorie 0;
BA_ "GenSigSendType" SG_ 1122 PSD_Vorgaenger_Segment_ID 0;
BA_ "GenSigSendType" SG_ 1122 PSD_wahrscheinlichster_Pfad 0;
BA_ "GenSigSendType" SG_ 1123 PSD_Attribut_1_ID 0;
BA_ "GenSigSendType" SG_ 1123 PSD_Attribut_1_Offset 0;
BA_ "GenSigSendType" SG_ 1123 PSD_Attribut_1_Wert 0;
BA_ "GenSigSendType" SG_ 1123 PSD_Attribut_2_ID 0;
BA_ "GenSigSendType" SG_ 1123 PSD_Attribut_2_Offset 0;
BA_ "GenSigSendType" SG_ 1123 PSD_Attribut_2_Wert 0;
BA_ "GenSigSendType" SG_ 1123 PSD_Attribut_Segment_ID_05 0;
BA_ "Fehlerwert" SG_ 1123 PSD_Attribut_Segment_ID_05 1;
BA_ "GenSigSendType" SG_ 1123 PSD_Attribute_Komplett_05 0;
BA_ "GenSigSendType" SG_ 1123 PSD_Pos_Fahrspur 0;
BA_ "GenSigSendType" SG_ 1123 PSD_Pos_Fehler_Laengsrichtung 0;
BA_ "GenSigSendType" SG_ 1123 PSD_Pos_Inhibitzeit 0;
BA_ "GenSigSendType" SG_ 1123 PSD_Pos_Segment_ID 0;
BA_ "GenSigSendType" SG_ 1123 PSD_Pos_Segmentlaenge 0;
BA_ "GenSigSendType" SG_ 1123 PSD_Pos_Standort_Eindeutig 0;
BA_ "GenSigSwitchedByIgnition" SG_ 1123 PSD_Pos_Standort_Eindeutig 0;
BA_ "GenSigSendType" SG_ 1124 PSD_06_Mux 0;
BA_ "NWM-WakeupAllowed" SG_ 1124 PSD_06_Mux 1;
BA_ "GenSigSwitchedByIgnition" SG_ 1124 PSD_06_Mux 0;
BA_ "Fehlerwert" SG_ 1124 PSD_Attribut_Segment_ID 1;
BA_ "GenSigSwitchedByIgnition" SG_ 1124 PSD_Attribute_Komplett_06 0;
BA_ "GenSigStartValue" SG_ 1124 PSD_Ges_Typ 3;
BA_ "GenSigSwitchedByIgnition" SG_ 1124 PSD_Ges_Typ 0;
BA_ "GenSigSwitchedByIgnition" SG_ 1124 PSD_Steigung_1_Attribute_kompl 0;
BA_ "Fehlerwert" SG_ 1124 PSD_Steigung_1_Segment_ID 1;
BA_ "GenSigSwitchedByIgnition" SG_ 1124 PSD_Steigung_2_Attribute_kompl 0;
BA_ "Fehlerwert" SG_ 1124 PSD_Steigung_2_Segment_ID 1;
BA_REL_ "GenSigTimeoutTime" BU_SG_REL_ DDA SG_ 233 Parken_Hindernis_Bereich 3200;
BA_REL_ "GenSigTimeoutTime" BU_SG_REL_ DDA SG_ 233 Parken_SM_Sensor 3200;
BA_REL_ "GenSigTimeoutTime" BU_SG_REL_ DDA SG_ 233 Parken_SM_Stillstand 3200;
BA_REL_ "GenSigTimeoutTime" BU_SG_REL_ DDA SG_ 233 Parken_SM_Schluessel 3200;
BA_REL_ "GenSigTimeoutTime" BU_SG_REL_ DDA SG_ 233 Parken_SM_Tueren 3200;
BA_REL_ "GenSigTimeoutTime" BU_SG_REL_ DDA SG_ 233 Parken_SM_Anhaenger 3200;
BA_REL_ "GenSigTimeoutTime" BU_SG_REL_ DDA SG_ 233 Parken_SM_Fahrbereitschaft 3200;
BA_REL_ "GenSigTimeoutTime" BU_SG_REL_ DDA SG_ 233 Parken_SM_Fahrstufe 3200;
BA_REL_ "GenSigTimeoutTime" BU_SG_REL_ DDA SG_ 233 Parken_Anhaltegrund_ext 3200;
BA_REL_ "GenSigTimeoutTime" BU_SG_REL_ DDA SG_ 233 Parken_Touchdiagnose_Anf 3200;
BA_REL_ "GenSigTimeoutTime" BU_SG_REL_ DDA SG_ 233 Parken_BT_Wunsch 3200;
BA_REL_ "GenSigTimeoutTime" BU_SG_REL_ DDA SG_ 233 Parken_Hindernis_erkannt 3200;
BA_REL_ "GenSigTimeoutTime" BU_SG_REL_ DDA SG_ 233 Parken_Fortschrittszaehler 3200;
BA_REL_ "GenSigTimeoutTime" BU_SG_REL_ DDA SG_ 233 Parken_Anhaltegrund 3200;
BA_REL_ "GenSigTimeoutTime" BU_SG_REL_ DDA SG_ 233 Parken_Fahrtaster_Empfehlung 3200;
BA_REL_ "GenSigTimeoutTime" BU_SG_REL_ DDA SG_ 233 Parken_Aktives_Bedienelement 3200;
BA_REL_ "GenSigTimeoutTime" BU_SG_REL_ DDA SG_ 233 Parken_FFB_Status 3200;
BA_REL_ "GenSigTimeoutTime" BU_SG_REL_ DDA SG_ 233 Parken_Reversieren_moeglich 3200;
BA_REL_ "GenSigTimeoutTime" BU_SG_REL_ DDA SG_ 233 Parken_Seite 3200;
BA_REL_ "GenSigTimeoutTime" BU_SG_REL_ DDA SG_ 233 Parken_Seite_Aktiv 3200;
BA_REL_ "GenSigTimeoutTime" BU_SG_REL_ DDA SG_ 233 Parken_Szenario_Aktiv 3200;
BA_REL_ "GenSigTimeoutTime" BU_SG_REL_ DDA SG_ 233 Parken_Manoever_Aktiv 3200;
BA_REL_ "GenSigTimeoutTime" BU_SG_REL_ DDA SG_ 233 Parken_Manoever 3200;
BA_REL_ "GenSigTimeoutTime" BU_SG_REL_ DDA SG_ 233 Parken_Szenario 3200;
BA_REL_ "GenSigTimeoutTime" BU_SG_REL_ DDA SG_ 233 Parken_Funktionsstatus 3200;
BA_REL_ "GenSigTimeoutTime" BU_SG_REL_ DDA SG_ 233 Parken_Richtung 3200;
BA_REL_ "GenSigTimeoutTime" BU_SG_REL_ DDA SG_ 233 Parken_Richtung_Aktiv 3200;
BA_REL_ "GenSigTimeoutTime" BU_SG_REL_ DDA SG_ 2463978635 Parken_Traj_Trans_ID 3200;
BA_REL_ "GenSigTimeoutTime" BU_SG_REL_ DDA SG_ 2463978635 Parken_Traj_aktueller_Zug 3200;
BA_REL_ "GenSigTimeoutTime" BU_SG_REL_ DDA SG_ 2463978635 Parken_Traj_Anzahl_Punkte 3200;
BA_REL_ "GenSigTimeoutTime" BU_SG_REL_ DDA SG_ 2463978635 Parken_Traj_letzter_Zug 3200;
BA_REL_ "GenSigTimeoutTime" BU_SG_REL_ DDA SG_ 2463978635 Parken_Traj_Fzg_Pos_X 3200;
BA_REL_ "GenSigTimeoutTime" BU_SG_REL_ DDA SG_ 2463978635 Parken_Traj_Fzg_Pos_Y 3200;
BA_REL_ "GenSigTimeoutTime" BU_SG_REL_ DDA SG_ 2463978635 Parken_Traj_Fahrtrichtung 3200;
BA_REL_ "GenSigTimeoutTime" BU_SG_REL_ DDA SG_ 2463978635 Parken_Traj_Fzg_Winkel 3200;
BA_REL_ "GenSigTimeoutTime" BU_SG_REL_ DDA SG_ 850 Parken_SM_03_MUX 800;
BA_REL_ "GenSigTimeoutTime" BU_SG_REL_ DDA SG_ 850 Parken_SM_03_Traj_Trans_ID_00 800;
BA_REL_ "GenSigTimeoutTime" BU_SG_REL_ DDA SG_ 850 Parken_SM_03_Traj_Trans_ID_01 800;
BA_REL_ "GenSigTimeoutTime" BU_SG_REL_ DDA SG_ 850 Parken_SM_03_Traj_Trans_ID_02 800;
BA_REL_ "GenSigTimeoutTime" BU_SG_REL_ DDA SG_ 850 Parken_SM_03_Traj_Trans_ID_03 800;
BA_REL_ "GenSigTimeoutTime" BU_SG_REL_ DDA SG_ 850 Parken_SM_03_Traj_Trans_ID_04 800;
BA_REL_ "GenSigTimeoutTime" BU_SG_REL_ DDA SG_ 850 Parken_SM_03_Traj_Trans_ID_05 800;
BA_REL_ "GenSigTimeoutTime" BU_SG_REL_ DDA SG_ 850 Parken_SM_03_Traj_Trans_ID_06 800;
BA_REL_ "GenSigTimeoutTime" BU_SG_REL_ DDA SG_ 850 Parken_Traj_P1_Pos_X 800;
BA_REL_ "GenSigTimeoutTime" BU_SG_REL_ DDA SG_ 850 Parken_Traj_P2_Pos_Y 800;
BA_REL_ "GenSigTimeoutTime" BU_SG_REL_ DDA SG_ 850 Parken_Traj_P3_Tangent 800;
BA_REL_ "GenSigTimeoutTime" BU_SG_REL_ DDA SG_ 850 Parken_Traj_P5_Pos_X 800;
BA_REL_ "GenSigTimeoutTime" BU_SG_REL_ DDA SG_ 850 Parken_Traj_P6_Pos_Y 800;
BA_REL_ "GenSigTimeoutTime" BU_SG_REL_ DDA SG_ 850 Parken_Traj_P7_Tangent 800;
BA_REL_ "GenSigTimeoutTime" BU_SG_REL_ DDA SG_ 850 Parken_Traj_P9_Pos_X 800;
BA_REL_ "GenSigTimeoutTime" BU_SG_REL_ DDA SG_ 850 Parken_Traj_P4_Pos_X 800;
BA_REL_ "GenSigTimeoutTime" BU_SG_REL_ DDA SG_ 850 Parken_Traj_P8_Pos_X 800;
BA_REL_ "GenSigTimeoutTime" BU_SG_REL_ DDA SG_ 850 Parken_Traj_P1_Pos_Y 800;
BA_REL_ "GenSigTimeoutTime" BU_SG_REL_ DDA SG_ 850 Parken_Traj_P2_Tangent 800;
BA_REL_ "GenSigTimeoutTime" BU_SG_REL_ DDA SG_ 850 Parken_Traj_P5_Pos_Y 800;
BA_REL_ "GenSigTimeoutTime" BU_SG_REL_ DDA SG_ 850 Parken_Traj_P6_Tangent 800;
BA_REL_ "GenSigTimeoutTime" BU_SG_REL_ DDA SG_ 850 Parken_Traj_P9_Pos_Y 800;
BA_REL_ "GenSigTimeoutTime" BU_SG_REL_ DDA SG_ 850 Parken_Traj_P3_Pos_X 800;
BA_REL_ "GenSigTimeoutTime" BU_SG_REL_ DDA SG_ 850 Parken_Traj_P4_Pos_Y 800;
BA_REL_ "GenSigTimeoutTime" BU_SG_REL_ DDA SG_ 850 Parken_Traj_P7_Pos_X 800;
BA_REL_ "GenSigTimeoutTime" BU_SG_REL_ DDA SG_ 850 Parken_Traj_P8_Pos_Y 800;
BA_REL_ "GenSigTimeoutTime" BU_SG_REL_ DDA SG_ 850 Parken_Traj_P1_Tangent 800;
BA_REL_ "GenSigTimeoutTime" BU_SG_REL_ DDA SG_ 850 Parken_Traj_P5_Tangent 800;
BA_REL_ "GenSigTimeoutTime" BU_SG_REL_ DDA SG_ 850 Parken_Traj_P9_Tangent 800;
BA_REL_ "GenSigTimeoutTime" BU_SG_REL_ DDA SG_ 850 Parken_Traj_P2_Pos_X 800;
BA_REL_ "GenSigTimeoutTime" BU_SG_REL_ DDA SG_ 850 Parken_Traj_P3_Pos_Y 800;
BA_REL_ "GenSigTimeoutTime" BU_SG_REL_ DDA SG_ 850 Parken_Traj_P4_Tangent 800;
BA_REL_ "GenSigTimeoutTime" BU_SG_REL_ DDA SG_ 850 Parken_Traj_P6_Pos_X 800;
BA_REL_ "GenSigTimeoutTime" BU_SG_REL_ DDA SG_ 850 Parken_Traj_P7_Pos_Y 800;
BA_REL_ "GenSigTimeoutTime" BU_SG_REL_ DDA SG_ 850 Parken_Traj_P8_Tangent 800;
BA_REL_ "GenSigTimeoutTime" BU_SG_REL_ Gateway SG_ 1122 PSD_Segment_ID 1500;
BA_REL_ "GenSigTimeoutTime" BU_SG_REL_ Gateway SG_ 1122 PSD_Vorgaenger_Segment_ID 1500;
BA_REL_ "GenSigTimeoutTime" BU_SG_REL_ Gateway SG_ 1122 PSD_Segmentlaenge 1500;
BA_REL_ "GenSigTimeoutTime" BU_SG_REL_ Gateway SG_ 1122 PSD_Strassenkategorie 1500;
BA_REL_ "GenSigTimeoutTime" BU_SG_REL_ Gateway SG_ 1122 PSD_Endkruemmung 1500;
BA_REL_ "GenSigTimeoutTime" BU_SG_REL_ Gateway SG_ 1122 PSD_Endkruemmung_Vorz 1500;
BA_REL_ "GenSigTimeoutTime" BU_SG_REL_ Gateway SG_ 1122 PSD_Idenditaets_ID 1500;
BA_REL_ "GenSigTimeoutTime" BU_SG_REL_ Gateway SG_ 1122 PSD_ADAS_Qualitaet 1500;
BA_REL_ "GenSigTimeoutTime" BU_SG_REL_ Gateway SG_ 1122 PSD_wahrscheinlichster_Pfad 1500;
BA_REL_ "GenSigTimeoutTime" BU_SG_REL_ Gateway SG_ 1122 PSD_Geradester_Pfad 1500;
BA_REL_ "GenSigTimeoutTime" BU_SG_REL_ Gateway SG_ 1122 PSD_Fahrspuren_Anzahl 1500;
BA_REL_ "GenSigTimeoutTime" BU_SG_REL_ Gateway SG_ 1122 PSD_Bebauung 1500;
BA_REL_ "GenSigTimeoutTime" BU_SG_REL_ Gateway SG_ 1122 PSD_Segment_Komplett 1500;
BA_REL_ "GenSigTimeoutTime" BU_SG_REL_ Gateway SG_ 1122 PSD_Rampe 1500;
BA_REL_ "GenSigTimeoutTime" BU_SG_REL_ Gateway SG_ 1122 PSD_Anfangskruemmung 1500;
BA_REL_ "GenSigTimeoutTime" BU_SG_REL_ Gateway SG_ 1122 PSD_Anfangskruemmung_Vorz 1500;
BA_REL_ "GenSigTimeoutTime" BU_SG_REL_ Gateway SG_ 1122 PSD_Abzweigerichtung 1500;
BA_REL_ "GenSigTimeoutTime" BU_SG_REL_ Gateway SG_ 1122 PSD_Abzweigewinkel 1500;
BA_REL_ "GenSigTimeoutTime" BU_SG_REL_ Gateway SG_ 1123 PSD_Pos_Segment_ID 1500;
BA_REL_ "GenSigTimeoutTime" BU_SG_REL_ Gateway SG_ 1123 PSD_Pos_Segmentlaenge 1500;
BA_REL_ "GenSigTimeoutTime" BU_SG_REL_ Gateway SG_ 1123 PSD_Pos_Inhibitzeit 1500;
BA_REL_ "GenSigTimeoutTime" BU_SG_REL_ Gateway SG_ 1123 PSD_Pos_Standort_Eindeutig 1500;
BA_REL_ "GenSigTimeoutTime" BU_SG_REL_ Gateway SG_ 1123 PSD_Pos_Fehler_Laengsrichtung 1500;
BA_REL_ "GenSigTimeoutTime" BU_SG_REL_ Gateway SG_ 1123 PSD_Pos_Fahrspur 1500;
BA_REL_ "GenSigTimeoutTime" BU_SG_REL_ Gateway SG_ 1123 PSD_Attribut_Segment_ID_05 1500;
BA_REL_ "GenSigTimeoutTime" BU_SG_REL_ Gateway SG_ 1123 PSD_Attribut_1_ID 1500;
BA_REL_ "GenSigTimeoutTime" BU_SG_REL_ Gateway SG_ 1123 PSD_Attribut_1_Wert 1500;
BA_REL_ "GenSigTimeoutTime" BU_SG_REL_ Gateway SG_ 1123 PSD_Attribut_1_Offset 1500;
BA_REL_ "GenSigTimeoutTime" BU_SG_REL_ Gateway SG_ 1123 PSD_Attribut_2_ID 1500;
BA_REL_ "GenSigTimeoutTime" BU_SG_REL_ Gateway SG_ 1123 PSD_Attribut_2_Wert 1500;
BA_REL_ "GenSigTimeoutTime" BU_SG_REL_ Gateway SG_ 1123 PSD_Attribut_2_Offset 1500;
BA_REL_ "GenSigTimeoutTime" BU_SG_REL_ Gateway SG_ 1123 PSD_Attribute_Komplett_05 1500;
BA_REL_ "GenSigTimeoutTime" BU_SG_REL_ Gateway SG_ 1124 PSD_06_Mux 1500;
BA_REL_ "GenSigTimeoutTime" BU_SG_REL_ Gateway SG_ 1124 PSD_Sys_Segment_ID 1500;
BA_REL_ "GenSigTimeoutTime" BU_SG_REL_ Gateway SG_ 1124 PSD_Attribut_Segment_ID 1500;
BA_REL_ "GenSigTimeoutTime" BU_SG_REL_ Gateway SG_ 1124 PSD_Ges_Segment_ID 1500;
BA_REL_ "GenSigTimeoutTime" BU_SG_REL_ Gateway SG_ 1124 PSD_Baum_Laenge_VZ 1500;
BA_REL_ "GenSigTimeoutTime" BU_SG_REL_ Gateway SG_ 1124 PSD_Steigung_1_Segment_ID 1500;
BA_REL_ "GenSigTimeoutTime" BU_SG_REL_ Gateway SG_ 1124 PSD_Baum_Laenge 1500;
BA_REL_ "GenSigTimeoutTime" BU_SG_REL_ Gateway SG_ 1124 PSD_Sys_Laendercode 1500;
BA_REL_ "GenSigTimeoutTime" BU_SG_REL_ Gateway SG_ 1124 PSD_Attribut_3_ID 1500;
BA_REL_ "GenSigTimeoutTime" BU_SG_REL_ Gateway SG_ 1124 PSD_Ges_Offset 1500;
BA_REL_ "GenSigTimeoutTime" BU_SG_REL_ Gateway SG_ 1124 PSD_Steigung_1_A_Steigung 1500;
BA_REL_ "GenSigTimeoutTime" BU_SG_REL_ Gateway SG_ 1124 PSD_Attribut_3_Offset 1500;
BA_REL_ "GenSigTimeoutTime" BU_SG_REL_ Gateway SG_ 1124 PSD_Ges_Geschwindigkeit 1500;
BA_REL_ "GenSigTimeoutTime" BU_SG_REL_ Gateway SG_ 1124 PSD_Steigung_1_A_Vorz 1500;
BA_REL_ "GenSigTimeoutTime" BU_SG_REL_ Gateway SG_ 1124 PSD_Sys_Geschwindigkeit_Einheit 1500;
BA_REL_ "GenSigTimeoutTime" BU_SG_REL_ Gateway SG_ 1124 PSD_Steigung_1_A_Offset 1500;
BA_REL_ "GenSigTimeoutTime" BU_SG_REL_ Gateway SG_ 1124 PSD_Sys_Verkehrsrichtung 1500;
BA_REL_ "GenSigTimeoutTime" BU_SG_REL_ Gateway SG_ 1124 PSD_Sys_Geometrieguete 1500;
BA_REL_ "GenSigTimeoutTime" BU_SG_REL_ Gateway SG_ 1124 PSD_Sys_Mapmatchingguete 1500;
BA_REL_ "GenSigTimeoutTime" BU_SG_REL_ Gateway SG_ 1124 PSD_Attribut_3_Wert 1500;
BA_REL_ "GenSigTimeoutTime" BU_SG_REL_ Gateway SG_ 1124 PSD_Ges_Typ 1500;
BA_REL_ "GenSigTimeoutTime" BU_SG_REL_ Gateway SG_ 1124 PSD_Sys_Alter_Karte 1500;
BA_REL_ "GenSigTimeoutTime" BU_SG_REL_ Gateway SG_ 1124 PSD_Ges_Spur_Geschw_Begrenzung 1500;
BA_REL_ "GenSigTimeoutTime" BU_SG_REL_ Gateway SG_ 1124 PSD_Steigung_1_B_Steigung 1500;
BA_REL_ "GenSigTimeoutTime" BU_SG_REL_ Gateway SG_ 1124 PSD_Attribut_4_ID 1500;
BA_REL_ "GenSigTimeoutTime" BU_SG_REL_ Gateway SG_ 1124 PSD_Sys_Zielfuehrung 1500;
BA_REL_ "GenSigTimeoutTime" BU_SG_REL_ Gateway SG_ 1124 PSD_Sys_US_State 1500;
BA_REL_ "GenSigTimeoutTime" BU_SG_REL_ Gateway SG_ 1124 PSD_Ges_Geschwindigkeit_Gespann 1500;
BA_REL_ "GenSigTimeoutTime" BU_SG_REL_ Gateway SG_ 1124 PSD_Baum_Breite_VZ 1500;
BA_REL_ "GenSigTimeoutTime" BU_SG_REL_ Gateway SG_ 1124 PSD_Attribut_4_Wert 1500;
BA_REL_ "GenSigTimeoutTime" BU_SG_REL_ Gateway SG_ 1124 PSD_Baum_Breite 1500;
BA_REL_ "GenSigTimeoutTime" BU_SG_REL_ Gateway SG_ 1124 PSD_Ges_Geschwindigkeit_Witter 1500;
BA_REL_ "GenSigTimeoutTime" BU_SG_REL_ Gateway SG_ 1124 PSD_Steigung_1_B_Vorz 1500;
BA_REL_ "GenSigTimeoutTime" BU_SG_REL_ Gateway SG_ 1124 PSD_Steigung_1_B_Offset 1500;
BA_REL_ "GenSigTimeoutTime" BU_SG_REL_ Gateway SG_ 1124 PSD_Ges_Geschwindigkeit_Tag_Anf 1500;
BA_REL_ "GenSigTimeoutTime" BU_SG_REL_ Gateway SG_ 1124 PSD_Attribut_4_Offset 1500;
BA_REL_ "GenSigTimeoutTime" BU_SG_REL_ Gateway SG_ 1124 PSD_Ges_Geschwindigkeit_Tag_Ende 1500;
BA_REL_ "GenSigTimeoutTime" BU_SG_REL_ Gateway SG_ 1124 PSD_Ges_Geschwindigkeit_Std_Anf 1500;
BA_REL_ "GenSigTimeoutTime" BU_SG_REL_ Gateway SG_ 1124 PSD_Steigung_1_Attribute_kompl 1500;
BA_REL_ "GenSigTimeoutTime" BU_SG_REL_ Gateway SG_ 1124 PSD_Steigung_2_Segment_ID 1500;
BA_REL_ "GenSigTimeoutTime" BU_SG_REL_ Gateway SG_ 1124 PSD_Attribut_5_ID 1500;
BA_REL_ "GenSigTimeoutTime" BU_SG_REL_ Gateway SG_ 1124 PSD_Ges_Geschwindigkeit_Std_Ende 1500;
BA_REL_ "GenSigTimeoutTime" BU_SG_REL_ Gateway SG_ 1124 PSD_Attribut_5_Offset 1500;
BA_REL_ "GenSigTimeoutTime" BU_SG_REL_ Gateway SG_ 1124 PSD_Steigung_2_Steigung 1500;
BA_REL_ "GenSigTimeoutTime" BU_SG_REL_ Gateway SG_ 1124 PSD_Ges_Ueberholverbot 1500;
BA_REL_ "GenSigTimeoutTime" BU_SG_REL_ Gateway SG_ 1124 PSD_Ges_Wechselverkehrszeichen 1500;
BA_REL_ "GenSigTimeoutTime" BU_SG_REL_ Gateway SG_ 1124 PSD_Attribut_5_Wert 1500;
BA_REL_ "GenSigTimeoutTime" BU_SG_REL_ Gateway SG_ 1124 PSD_Steigung_2_Vorz 1500;
BA_REL_ "GenSigTimeoutTime" BU_SG_REL_ Gateway SG_ 1124 PSD_Wechselverkehrszeichen_Typ 1500;
BA_REL_ "GenSigTimeoutTime" BU_SG_REL_ Gateway SG_ 1124 PSD_Baum_Ausrichtung 1500;
BA_REL_ "GenSigTimeoutTime" BU_SG_REL_ Gateway SG_ 1124 PSD_Steigung_2_Offset 1500;
BA_REL_ "GenSigTimeoutTime" BU_SG_REL_ Gateway SG_ 1124 PSD_Ges_Gesetzlich_Kategorie 1500;
BA_REL_ "GenSigTimeoutTime" BU_SG_REL_ Gateway SG_ 1124 PSD_Attribute_Komplett_06 1500;
BA_REL_ "GenSigTimeoutTime" BU_SG_REL_ Gateway SG_ 1124 PSD_Ges_Gesetzlich_Zusatz 1500;
BA_REL_ "GenSigTimeoutTime" BU_SG_REL_ Gateway SG_ 1124 PSD_Ges_Verkehrszeichen_Quelle 1500;
BA_REL_ "GenSigTimeoutTime" BU_SG_REL_ Gateway SG_ 1124 PSD_Steigung_2_Attribute_kompl 1500;
BA_REL_ "GenSigTimeoutTime" BU_SG_REL_ Gateway SG_ 1124 PSD_Ges_Attribute_Komplett 1500;
BA_REL_ "GenSigTimeoutTime" BU_SG_REL_ Gateway_PAG SG_ 1122 PSD_Segment_ID 1500;
BA_REL_ "GenSigTimeoutTime" BU_SG_REL_ Gateway_PAG SG_ 1122 PSD_Vorgaenger_Segment_ID 1500;
BA_REL_ "GenSigTimeoutTime" BU_SG_REL_ Gateway_PAG SG_ 1122 PSD_Segmentlaenge 1500;
BA_REL_ "GenSigTimeoutTime" BU_SG_REL_ Gateway_PAG SG_ 1122 PSD_Strassenkategorie 1500;
BA_REL_ "GenSigTimeoutTime" BU_SG_REL_ Gateway_PAG SG_ 1122 PSD_Endkruemmung 1500;
BA_REL_ "GenSigTimeoutTime" BU_SG_REL_ Gateway_PAG SG_ 1122 PSD_Endkruemmung_Vorz 1500;
BA_REL_ "GenSigTimeoutTime" BU_SG_REL_ Gateway_PAG SG_ 1122 PSD_Idenditaets_ID 1500;
BA_REL_ "GenSigTimeoutTime" BU_SG_REL_ Gateway_PAG SG_ 1122 PSD_ADAS_Qualitaet 1500;
BA_REL_ "GenSigTimeoutTime" BU_SG_REL_ Gateway_PAG SG_ 1122 PSD_wahrscheinlichster_Pfad 1500;
BA_REL_ "GenSigTimeoutTime" BU_SG_REL_ Gateway_PAG SG_ 1122 PSD_Geradester_Pfad 1500;
BA_REL_ "GenSigTimeoutTime" BU_SG_REL_ Gateway_PAG SG_ 1122 PSD_Fahrspuren_Anzahl 1500;
BA_REL_ "GenSigTimeoutTime" BU_SG_REL_ Gateway_PAG SG_ 1122 PSD_Bebauung 1500;
BA_REL_ "GenSigTimeoutTime" BU_SG_REL_ Gateway_PAG SG_ 1122 PSD_Segment_Komplett 1500;
BA_REL_ "GenSigTimeoutTime" BU_SG_REL_ Gateway_PAG SG_ 1122 PSD_Rampe 1500;
BA_REL_ "GenSigTimeoutTime" BU_SG_REL_ Gateway_PAG SG_ 1122 PSD_Anfangskruemmung 1500;
BA_REL_ "GenSigTimeoutTime" BU_SG_REL_ Gateway_PAG SG_ 1122 PSD_Anfangskruemmung_Vorz 1500;
BA_REL_ "GenSigTimeoutTime" BU_SG_REL_ Gateway_PAG SG_ 1122 PSD_Abzweigerichtung 1500;
BA_REL_ "GenSigTimeoutTime" BU_SG_REL_ Gateway_PAG SG_ 1122 PSD_Abzweigewinkel 1500;
BA_REL_ "GenSigTimeoutTime" BU_SG_REL_ Gateway_PAG SG_ 1123 PSD_Pos_Segment_ID 1500;
BA_REL_ "GenSigTimeoutTime" BU_SG_REL_ Gateway_PAG SG_ 1123 PSD_Pos_Segmentlaenge 1500;
BA_REL_ "GenSigTimeoutTime" BU_SG_REL_ Gateway_PAG SG_ 1123 PSD_Pos_Inhibitzeit 1500;
BA_REL_ "GenSigTimeoutTime" BU_SG_REL_ Gateway_PAG SG_ 1123 PSD_Pos_Standort_Eindeutig 1500;
BA_REL_ "GenSigTimeoutTime" BU_SG_REL_ Gateway_PAG SG_ 1123 PSD_Pos_Fehler_Laengsrichtung 1500;
BA_REL_ "GenSigTimeoutTime" BU_SG_REL_ Gateway_PAG SG_ 1123 PSD_Pos_Fahrspur 1500;
BA_REL_ "GenSigTimeoutTime" BU_SG_REL_ Gateway_PAG SG_ 1123 PSD_Attribut_Segment_ID_05 1500;
BA_REL_ "GenSigTimeoutTime" BU_SG_REL_ Gateway_PAG SG_ 1123 PSD_Attribut_1_ID 1500;
BA_REL_ "GenSigTimeoutTime" BU_SG_REL_ Gateway_PAG SG_ 1123 PSD_Attribut_1_Wert 1500;
BA_REL_ "GenSigTimeoutTime" BU_SG_REL_ Gateway_PAG SG_ 1123 PSD_Attribut_1_Offset 1500;
BA_REL_ "GenSigTimeoutTime" BU_SG_REL_ Gateway_PAG SG_ 1123 PSD_Attribut_2_ID 1500;
BA_REL_ "GenSigTimeoutTime" BU_SG_REL_ Gateway_PAG SG_ 1123 PSD_Attribut_2_Wert 1500;
BA_REL_ "GenSigTimeoutTime" BU_SG_REL_ Gateway_PAG SG_ 1123 PSD_Attribut_2_Offset 1500;
BA_REL_ "GenSigTimeoutTime" BU_SG_REL_ Gateway_PAG SG_ 1123 PSD_Attribute_Komplett_05 1500;
BA_REL_ "GenSigTimeoutTime" BU_SG_REL_ Gateway_PAG SG_ 1124 PSD_06_Mux 1500;
BA_REL_ "GenSigTimeoutTime" BU_SG_REL_ Gateway_PAG SG_ 1124 PSD_Sys_Segment_ID 1500;
BA_REL_ "GenSigTimeoutTime" BU_SG_REL_ Gateway_PAG SG_ 1124 PSD_Attribut_Segment_ID 1500;
BA_REL_ "GenSigTimeoutTime" BU_SG_REL_ Gateway_PAG SG_ 1124 PSD_Ges_Segment_ID 1500;
BA_REL_ "GenSigTimeoutTime" BU_SG_REL_ Gateway_PAG SG_ 1124 PSD_Baum_Laenge_VZ 1500;
BA_REL_ "GenSigTimeoutTime" BU_SG_REL_ Gateway_PAG SG_ 1124 PSD_Steigung_1_Segment_ID 1500;
BA_REL_ "GenSigTimeoutTime" BU_SG_REL_ Gateway_PAG SG_ 1124 PSD_Baum_Laenge 1500;
BA_REL_ "GenSigTimeoutTime" BU_SG_REL_ Gateway_PAG SG_ 1124 PSD_Sys_Laendercode 1500;
BA_REL_ "GenSigTimeoutTime" BU_SG_REL_ Gateway_PAG SG_ 1124 PSD_Attribut_3_ID 1500;
BA_REL_ "GenSigTimeoutTime" BU_SG_REL_ Gateway_PAG SG_ 1124 PSD_Ges_Offset 1500;
BA_REL_ "GenSigTimeoutTime" BU_SG_REL_ Gateway_PAG SG_ 1124 PSD_Steigung_1_A_Steigung 1500;
BA_REL_ "GenSigTimeoutTime" BU_SG_REL_ Gateway_PAG SG_ 1124 PSD_Attribut_3_Offset 1500;
BA_REL_ "GenSigTimeoutTime" BU_SG_REL_ Gateway_PAG SG_ 1124 PSD_Ges_Geschwindigkeit 1500;
BA_REL_ "GenSigTimeoutTime" BU_SG_REL_ Gateway_PAG SG_ 1124 PSD_Steigung_1_A_Vorz 1500;
BA_REL_ "GenSigTimeoutTime" BU_SG_REL_ Gateway_PAG SG_ 1124 PSD_Sys_Geschwindigkeit_Einheit 1500;
BA_REL_ "GenSigTimeoutTime" BU_SG_REL_ Gateway_PAG SG_ 1124 PSD_Steigung_1_A_Offset 1500;
BA_REL_ "GenSigTimeoutTime" BU_SG_REL_ Gateway_PAG SG_ 1124 PSD_Sys_Verkehrsrichtung 1500;
BA_REL_ "GenSigTimeoutTime" BU_SG_REL_ Gateway_PAG SG_ 1124 PSD_Sys_Geometrieguete 1500;
BA_REL_ "GenSigTimeoutTime" BU_SG_REL_ Gateway_PAG SG_ 1124 PSD_Sys_Mapmatchingguete 1500;
BA_REL_ "GenSigTimeoutTime" BU_SG_REL_ Gateway_PAG SG_ 1124 PSD_Attribut_3_Wert 1500;
BA_REL_ "GenSigTimeoutTime" BU_SG_REL_ Gateway_PAG SG_ 1124 PSD_Ges_Typ 1500;
BA_REL_ "GenSigTimeoutTime" BU_SG_REL_ Gateway_PAG SG_ 1124 PSD_Sys_Alter_Karte 1500;
BA_REL_ "GenSigTimeoutTime" BU_SG_REL_ Gateway_PAG SG_ 1124 PSD_Ges_Spur_Geschw_Begrenzung 1500;
BA_REL_ "GenSigTimeoutTime" BU_SG_REL_ Gateway_PAG SG_ 1124 PSD_Steigung_1_B_Steigung 1500;
BA_REL_ "GenSigTimeoutTime" BU_SG_REL_ Gateway_PAG SG_ 1124 PSD_Attribut_4_ID 1500;
BA_REL_ "GenSigTimeoutTime" BU_SG_REL_ Gateway_PAG SG_ 1124 PSD_Sys_Zielfuehrung 1500;
BA_REL_ "GenSigTimeoutTime" BU_SG_REL_ Gateway_PAG SG_ 1124 PSD_Sys_US_State 1500;
BA_REL_ "GenSigTimeoutTime" BU_SG_REL_ Gateway_PAG SG_ 1124 PSD_Ges_Geschwindigkeit_Gespann 1500;
BA_REL_ "GenSigTimeoutTime" BU_SG_REL_ Gateway_PAG SG_ 1124 PSD_Baum_Breite_VZ 1500;
BA_REL_ "GenSigTimeoutTime" BU_SG_REL_ Gateway_PAG SG_ 1124 PSD_Attribut_4_Wert 1500;
BA_REL_ "GenSigTimeoutTime" BU_SG_REL_ Gateway_PAG SG_ 1124 PSD_Baum_Breite 1500;
BA_REL_ "GenSigTimeoutTime" BU_SG_REL_ Gateway_PAG SG_ 1124 PSD_Ges_Geschwindigkeit_Witter 1500;
BA_REL_ "GenSigTimeoutTime" BU_SG_REL_ Gateway_PAG SG_ 1124 PSD_Steigung_1_B_Vorz 1500;
BA_REL_ "GenSigTimeoutTime" BU_SG_REL_ Gateway_PAG SG_ 1124 PSD_Steigung_1_B_Offset 1500;
BA_REL_ "GenSigTimeoutTime" BU_SG_REL_ Gateway_PAG SG_ 1124 PSD_Ges_Geschwindigkeit_Tag_Anf 1500;
BA_REL_ "GenSigTimeoutTime" BU_SG_REL_ Gateway_PAG SG_ 1124 PSD_Attribut_4_Offset 1500;
BA_REL_ "GenSigTimeoutTime" BU_SG_REL_ Gateway_PAG SG_ 1124 PSD_Ges_Geschwindigkeit_Tag_Ende 1500;
BA_REL_ "GenSigTimeoutTime" BU_SG_REL_ Gateway_PAG SG_ 1124 PSD_Ges_Geschwindigkeit_Std_Anf 1500;
BA_REL_ "GenSigTimeoutTime" BU_SG_REL_ Gateway_PAG SG_ 1124 PSD_Steigung_1_Attribute_kompl 1500;
BA_REL_ "GenSigTimeoutTime" BU_SG_REL_ Gateway_PAG SG_ 1124 PSD_Steigung_2_Segment_ID 1500;
BA_REL_ "GenSigTimeoutTime" BU_SG_REL_ Gateway_PAG SG_ 1124 PSD_Attribut_5_ID 1500;
BA_REL_ "GenSigTimeoutTime" BU_SG_REL_ Gateway_PAG SG_ 1124 PSD_Ges_Geschwindigkeit_Std_Ende 1500;
BA_REL_ "GenSigTimeoutTime" BU_SG_REL_ Gateway_PAG SG_ 1124 PSD_Attribut_5_Offset 1500;
BA_REL_ "GenSigTimeoutTime" BU_SG_REL_ Gateway_PAG SG_ 1124 PSD_Steigung_2_Steigung 1500;
BA_REL_ "GenSigTimeoutTime" BU_SG_REL_ Gateway_PAG SG_ 1124 PSD_Ges_Ueberholverbot 1500;
BA_REL_ "GenSigTimeoutTime" BU_SG_REL_ Gateway_PAG SG_ 1124 PSD_Ges_Wechselverkehrszeichen 1500;
BA_REL_ "GenSigTimeoutTime" BU_SG_REL_ Gateway_PAG SG_ 1124 PSD_Attribut_5_Wert 1500;
BA_REL_ "GenSigTimeoutTime" BU_SG_REL_ Gateway_PAG SG_ 1124 PSD_Steigung_2_Vorz 1500;
BA_REL_ "GenSigTimeoutTime" BU_SG_REL_ Gateway_PAG SG_ 1124 PSD_Wechselverkehrszeichen_Typ 1500;
BA_REL_ "GenSigTimeoutTime" BU_SG_REL_ Gateway_PAG SG_ 1124 PSD_Baum_Ausrichtung 1500;
BA_REL_ "GenSigTimeoutTime" BU_SG_REL_ Gateway_PAG SG_ 1124 PSD_Steigung_2_Offset 1500;
BA_REL_ "GenSigTimeoutTime" BU_SG_REL_ Gateway_PAG SG_ 1124 PSD_Ges_Gesetzlich_Kategorie 1500;
BA_REL_ "GenSigTimeoutTime" BU_SG_REL_ Gateway_PAG SG_ 1124 PSD_Attribute_Komplett_06 1500;
BA_REL_ "GenSigTimeoutTime" BU_SG_REL_ Gateway_PAG SG_ 1124 PSD_Ges_Gesetzlich_Zusatz 1500;
BA_REL_ "GenSigTimeoutTime" BU_SG_REL_ Gateway_PAG SG_ 1124 PSD_Ges_Verkehrszeichen_Quelle 1500;
BA_REL_ "GenSigTimeoutTime" BU_SG_REL_ Gateway_PAG SG_ 1124 PSD_Steigung_2_Attribute_kompl 1500;
BA_REL_ "GenSigTimeoutTime" BU_SG_REL_ Gateway_PAG SG_ 1124 PSD_Ges_Attribute_Komplett 1500;
BA_REL_ "GenSigTimeoutTime" BU_SG_REL_ OTA_FC SG_ 2527679498 Perso_Kontonummer 5000;
BA_REL_ "GenSigTimeoutTime" BU_SG_REL_ OTA_FC SG_ 2527679498 Perso_Steuerung 5000;
BA_REL_ "GenSigTimeoutTime" BU_SG_REL_ OTA_FC SG_ 2527679498 Perso_Steuerungsparameter 5000;
BA_REL_ "GenSigTimeoutTime" BU_SG_REL_ OTA_FC SG_ 2527679498 Perso_Status 5000;
BA_REL_ "GenSigTimeoutTime" BU_SG_REL_ OTA_FC SG_ 2527679498 Perso_Aktiv 5000;
BA_REL_ "GenSigTimeoutTime" BU_SG_REL_ OTA_FC SG_ 1122 PSD_Strassenkategorie 1500;
BA_REL_ "GenSigTimeoutTime" BU_SG_REL_ ZR_High SG_ 908 PACC_Segelanteil 1000;
BA_REL_ "GenSigTimeoutTime" BU_SG_REL_ ZR_High SG_ 908 PACC_Durchschnittsgeschw 1000;
BA_REL_ "GenSigTimeoutTime" BU_SG_REL_ ZR_High SG_ 908 PACC_Uebernahmeaufforderung 1000;
BA_REL_ "GenSigTimeoutTime" BU_SG_REL_ ZR_High SG_ 908 PACC_Systemstatus 1000;
BA_REL_ "GenSigTimeoutTime" BU_SG_REL_ ZR_High SG_ 908 PACC_Vorausschaugeschw 1000;
BA_REL_ "GenSigTimeoutTime" BU_SG_REL_ ZR_High SG_ 908 PACC_Offset 1000;
BA_REL_ "GenSigTimeoutTime" BU_SG_REL_ ZR_High SG_ 908 PACC_Sollgeschwindigkeit 1000;
BA_REL_ "GenSigTimeoutTime" BU_SG_REL_ ZR_High SG_ 908 PACC_naechstes_Event 1000;
BA_REL_ "GenSigTimeoutTime" BU_SG_REL_ ZR_High SG_ 233 Parken_Hindernis_erkannt 3200;
BA_REL_ "GenSigTimeoutTime" BU_SG_REL_ ZR_High SG_ 233 Parken_Fortschrittszaehler 3200;
BA_REL_ "GenSigTimeoutTime" BU_SG_REL_ ZR_High SG_ 233 Parken_Anhaltegrund 3200;
BA_REL_ "GenSigTimeoutTime" BU_SG_REL_ ZR_High SG_ 233 Parken_Fahrtaster_Empfehlung 3200;
BA_REL_ "GenSigTimeoutTime" BU_SG_REL_ ZR_High SG_ 233 Parken_Aktives_Bedienelement 3200;
BA_REL_ "GenSigTimeoutTime" BU_SG_REL_ ZR_High SG_ 233 Parken_FFB_Status 3200;
BA_REL_ "GenSigTimeoutTime" BU_SG_REL_ ZR_High SG_ 233 Parken_Reversieren_moeglich 3200;
BA_REL_ "GenSigTimeoutTime" BU_SG_REL_ ZR_High SG_ 233 Parken_Seite 3200;
BA_REL_ "GenSigTimeoutTime" BU_SG_REL_ ZR_High SG_ 233 Parken_Seite_Aktiv 3200;
BA_REL_ "GenSigTimeoutTime" BU_SG_REL_ ZR_High SG_ 233 Parken_Szenario_Aktiv 3200;
BA_REL_ "GenSigTimeoutTime" BU_SG_REL_ ZR_High SG_ 233 Parken_Manoever_Aktiv 3200;
BA_REL_ "GenSigTimeoutTime" BU_SG_REL_ ZR_High SG_ 233 Parken_Manoever 3200;
BA_REL_ "GenSigTimeoutTime" BU_SG_REL_ ZR_High SG_ 233 Parken_Szenario 3200;
BA_REL_ "GenSigTimeoutTime" BU_SG_REL_ ZR_High SG_ 233 Parken_Funktionsstatus 3200;
BA_REL_ "GenSigTimeoutTime" BU_SG_REL_ ZR_High SG_ 233 Parken_Richtung 3200;
BA_REL_ "GenSigTimeoutTime" BU_SG_REL_ ZR_High SG_ 233 Parken_Richtung_Aktiv 3200;
BA_REL_ "GenSigTimeoutTime" BU_SG_REL_ ZR_High SG_ 872 PH2_Anf_Audioabsenkung 1000;
BA_REL_ "GenSigTimeoutTime" BU_SG_REL_ ZR_High SG_ 1175 PH_Abschaltursache 1000;
BA_REL_ "GenSigTimeoutTime" BU_SG_REL_ ZR_High SG_ 1175 PH_Anf_Audioabsenkung 1000;
BA_REL_ "GenSigTimeoutTime" BU_SG_REL_ ZR_High SG_ 1175 PH_Tongeber_H_verfuegbar 1000;
BA_REL_ "GenSigTimeoutTime" BU_SG_REL_ ZR_High SG_ 1175 PH_Taster 1000;
BA_REL_ "GenSigTimeoutTime" BU_SG_REL_ ZR_High SG_ 1175 PH_Anf_Verdeck 1000;
BA_REL_ "GenSigTimeoutTime" BU_SG_REL_ ZR_High SG_ 1175 PH_StartStopp_Info 1000;
BA_REL_ "GenSigTimeoutTime" BU_SG_REL_ ZR_High SG_ 1175 PH_defekt 1000;
BA_REL_ "GenSigTimeoutTime" BU_SG_REL_ ZR_High SG_ 1175 PH_gestoert 1000;
BA_REL_ "GenSigTimeoutTime" BU_SG_REL_ ZR_High SG_ 1175 PH_Display_Kundenwunsch 1000;
BA_REL_ "GenSigTimeoutTime" BU_SG_REL_ ZR_High SG_ 803 SC_WarnBrems_Texte 2000;
BA_REL_ "GenSigTimeoutTime" BU_SG_REL_ ZR_High SG_ 803 SC_AbstWarn_Texte 2000;
BA_REL_ "GenSigTimeoutTime" BU_SG_REL_ ZR_High SG_ 2527679498 Perso_Kontonummer 5000;
BA_REL_ "GenSigTimeoutTime" BU_SG_REL_ ZR_High SG_ 2527679498 Perso_Steuerung 5000;
BA_REL_ "GenSigTimeoutTime" BU_SG_REL_ ZR_High SG_ 2527679498 Perso_Steuerungsparameter 5000;
BA_REL_ "GenSigTimeoutTime" BU_SG_REL_ ZR_High SG_ 2527679498 Perso_Status 5000;
BA_REL_ "GenSigTimeoutTime" BU_SG_REL_ ZR_High SG_ 2527679498 Perso_Fahrernummer 5000;
BA_REL_ "GenSigTimeoutTime" BU_SG_REL_ ZR_High SG_ 381 PLA2_Status_PLA_EPS 5000;
BA_REL_ "GenSigTimeoutTime" BU_SG_REL_ ZR_High SG_ 304 PLA_Status_PLA_EPS 5000;
BA_REL_ "GenSigTimeoutTime" BU_SG_REL_ ZR_High SG_ 304 PLA_Anf_Bremsverzoegerung 5000;
BA_REL_ "GenSigTimeoutTime" BU_SG_REL_ ZR_High SG_ 1166 PLA_Status_Aktive_Seite 1000;
BA_REL_ "GenSigTimeoutTime" BU_SG_REL_ ZR_High SG_ 1166 PLA_Anf_Anzeige_Mini 1000;
BA_REL_ "GenSigTimeoutTime" BU_SG_REL_ ZR_High SG_ 1166 PLA_Mini_Modus 1000;
BA_REL_ "GenSigTimeoutTime" BU_SG_REL_ ZR_High SG_ 1166 PLA_Anf_Anzeige_Schwellpfeil 1000;
BA_REL_ "GenSigTimeoutTime" BU_SG_REL_ ZR_High SG_ 1166 PLA_Anf_Anzeige_Bremsfuss 1000;
BA_REL_ "GenSigTimeoutTime" BU_SG_REL_ ZR_High SG_ 1166 PLA_Anf_Anzeigemodus 1000;
BA_REL_ "GenSigTimeoutTime" BU_SG_REL_ ZR_High SG_ 1166 PLA_Status_Funktion 1000;
BA_REL_ "GenSigTimeoutTime" BU_SG_REL_ ZR_LIMU SG_ 872 PH2_Anf_Audioabsenkung 1000;
BA_REL_ "GenSigTimeoutTime" BU_SG_REL_ ZR_LIMU SG_ 1175 PH_Anf_Audioabsenkung 1000;
BA_REL_ "GenSigTimeoutTime" BU_SG_REL_ ZR_LIMU SG_ 1355 PH_Ton_Ausgabe 5000;
BA_REL_ "GenSigTimeoutTime" BU_SG_REL_ ZR_LIMU SG_ 1355 PH_Ton_Pausenlaenge 5000;
BA_REL_ "GenSigTimeoutTime" BU_SG_REL_ ZR_LIMU SG_ 1355 PH_Ton_Richtung 5000;
BA_REL_ "GenSigTimeoutTime" BU_SG_REL_ ZR_LIMU SG_ 1355 PH_Ton_Lautstaerke 5000;
BA_REL_ "GenSigTimeoutTime" BU_SG_REL_ ZR_LIMU SG_ 2527679498 Perso_Kontonummer 5000;
BA_REL_ "GenSigTimeoutTime" BU_SG_REL_ ZR_LIMU SG_ 2527679498 Perso_Steuerung 5000;
BA_REL_ "GenSigTimeoutTime" BU_SG_REL_ ZR_LIMU SG_ 2527679498 Perso_Steuerungsparameter 5000;
BA_REL_ "GenSigTimeoutTime" BU_SG_REL_ ZR_LIMU SG_ 2527679498 Perso_Status 5000;
BA_REL_ "GenSigTimeoutTime" BU_SG_REL_ ZR_LIMU SG_ 2527679498 Perso_Freigabe_Verstellung 5000;
BA_REL_ "GenSigTimeoutTime" BU_SG_REL_ ZR_LIMU SG_ 2527679498 IAA_PSO_wake_up 5000;
BA_REL_ "GenSigTimeoutTime" BU_SG_REL_ ZR_LIMU SG_ 2527679498 Perso_Fahrernummer 5000;
BA_REL_ "GenSigTimeoutTime" BU_SG_REL_ ZR_LIMU SG_ 2527679498 IAA_Active_User_ID 5000;
BA_REL_ "GenSigTimeoutTime" BU_SG_REL_ ZR_LIMU SG_ 2527679498 IAA_Identified_User_ID 5000;
BA_REL_ "GenSigTimeoutTime" BU_SG_REL_ ZR_LIMU SG_ 2589283731 PLA_SDA_Status 5000;
BA_REL_ "GenSigTimeoutTime" BU_SG_REL_ ZR_LIMU SG_ 2589283731 PLA_SDA_Aktive_Seite 5000;
BA_REL_ "GenSigTimeoutTime" BU_SG_REL_ ZR_LIMU SG_ 2589283731 PLA_SDA_Exist 5000;
BA_REL_ "GenSigTimeoutTime" BU_SG_REL_ ZR_LIMU SG_ 2589283731 PLA_SDA_Laengs_Querluecke 5000;
BA_REL_ "GenSigTimeoutTime" BU_SG_REL_ ZR_LIMU SG_ 2589283732 PLA_SDA_Re_Offset_8 5000;
BA_REL_ "GenSigTimeoutTime" BU_SG_REL_ ZR_LIMU SG_ 2589283732 PLA_SDA_Re_ID_8 5000;
BA_REL_ "GenSigTimeoutTime" BU_SG_REL_ ZR_LIMU SG_ 2589283732 PLA_SDA_Re_Offset_7 5000;
BA_REL_ "GenSigTimeoutTime" BU_SG_REL_ ZR_LIMU SG_ 2589283732 PLA_SDA_Re_ID_7 5000;
BA_REL_ "GenSigTimeoutTime" BU_SG_REL_ ZR_LIMU SG_ 2589283732 PLA_SDA_Re_Offset_6 5000;
BA_REL_ "GenSigTimeoutTime" BU_SG_REL_ ZR_LIMU SG_ 2589283732 PLA_SDA_Re_ID_6 5000;
BA_REL_ "GenSigTimeoutTime" BU_SG_REL_ ZR_LIMU SG_ 2589283732 PLA_SDA_Re_Offset_5 5000;
BA_REL_ "GenSigTimeoutTime" BU_SG_REL_ ZR_LIMU SG_ 2589283732 PLA_SDA_Re_ID_5 5000;
BA_REL_ "GenSigTimeoutTime" BU_SG_REL_ ZR_LIMU SG_ 2589283732 PLA_SDA_Re_Offset_4 5000;
BA_REL_ "GenSigTimeoutTime" BU_SG_REL_ ZR_LIMU SG_ 2589283732 PLA_SDA_Re_ID_4 5000;
BA_REL_ "GenSigTimeoutTime" BU_SG_REL_ ZR_LIMU SG_ 2589283732 PLA_SDA_Re_Offset_3 5000;
BA_REL_ "GenSigTimeoutTime" BU_SG_REL_ ZR_LIMU SG_ 2589283732 PLA_SDA_Re_ID_3 5000;
BA_REL_ "GenSigTimeoutTime" BU_SG_REL_ ZR_LIMU SG_ 2589283732 PLA_SDA_Re_Offset_2 5000;
BA_REL_ "GenSigTimeoutTime" BU_SG_REL_ ZR_LIMU SG_ 2589283732 PLA_SDA_Re_ID_2 5000;
BA_REL_ "GenSigTimeoutTime" BU_SG_REL_ ZR_LIMU SG_ 2589283732 PLA_SDA_Re_Offset_1 5000;
BA_REL_ "GenSigTimeoutTime" BU_SG_REL_ ZR_LIMU SG_ 2589283732 PLA_SDA_Re_ID_1 5000;
BA_REL_ "GenSigTimeoutTime" BU_SG_REL_ ZR_MIB_TOP_ab_Gen3 SG_ 872 PH2_Anf_Audioabsenkung 1000;
BA_REL_ "GenSigTimeoutTime" BU_SG_REL_ ZR_MIB_TOP_ab_Gen3 SG_ 1175 PH_Anf_Audioabsenkung 1000;
BA_REL_ "GenSigTimeoutTime" BU_SG_REL_ ZR_MIB_TOP_ab_Gen3 SG_ 1355 PH_Ton_Ausgabe 5000;
BA_REL_ "GenSigTimeoutTime" BU_SG_REL_ ZR_MIB_TOP_ab_Gen3 SG_ 1355 PH_Ton_Pausenlaenge 5000;
BA_REL_ "GenSigTimeoutTime" BU_SG_REL_ ZR_MIB_TOP_ab_Gen3 SG_ 1355 PH_Ton_Richtung 5000;
BA_REL_ "GenSigTimeoutTime" BU_SG_REL_ ZR_MIB_TOP_ab_Gen3 SG_ 1355 PH_Ton_Lautstaerke 5000;
BA_REL_ "GenSigTimeoutTime" BU_SG_REL_ ZR_MIB_TOP_ab_Gen3 SG_ 2527679498 Perso_Kontonummer 5000;
BA_REL_ "GenSigTimeoutTime" BU_SG_REL_ ZR_MIB_TOP_ab_Gen3 SG_ 2527679498 Perso_Steuerung 5000;
BA_REL_ "GenSigTimeoutTime" BU_SG_REL_ ZR_MIB_TOP_ab_Gen3 SG_ 2527679498 Perso_Steuerungsparameter 5000;
BA_REL_ "GenSigTimeoutTime" BU_SG_REL_ ZR_MIB_TOP_ab_Gen3 SG_ 2527679498 Perso_Status 5000;
BA_REL_ "GenSigTimeoutTime" BU_SG_REL_ ZR_MIB_TOP_ab_Gen3 SG_ 2527679498 Perso_Freigabe_Verstellung 5000;
BA_REL_ "GenSigTimeoutTime" BU_SG_REL_ ZR_MIB_TOP_ab_Gen3 SG_ 2527679498 IAA_PSO_wake_up 5000;
BA_REL_ "GenSigTimeoutTime" BU_SG_REL_ ZR_MIB_TOP_ab_Gen3 SG_ 2527679498 Perso_Fahrernummer 5000;
BA_REL_ "GenSigTimeoutTime" BU_SG_REL_ ZR_MIB_TOP_ab_Gen3 SG_ 2527679498 IAA_Active_User_ID 5000;
BA_REL_ "GenSigTimeoutTime" BU_SG_REL_ ZR_MIB_TOP_ab_Gen3 SG_ 2527679498 IAA_Identified_User_ID 5000;
BA_REL_ "GenSigTimeoutTime" BU_SG_REL_ ZR_MIB_TOP_ab_Gen3 SG_ 2589283731 PLA_SDA_Status 5000;
BA_REL_ "GenSigTimeoutTime" BU_SG_REL_ ZR_MIB_TOP_ab_Gen3 SG_ 2589283731 PLA_SDA_Aktive_Seite 5000;
BA_REL_ "GenSigTimeoutTime" BU_SG_REL_ ZR_MIB_TOP_ab_Gen3 SG_ 2589283731 PLA_SDA_Exist 5000;
BA_REL_ "GenSigTimeoutTime" BU_SG_REL_ ZR_MIB_TOP_ab_Gen3 SG_ 2589283731 PLA_SDA_Laengs_Querluecke 5000;
BA_REL_ "GenSigTimeoutTime" BU_SG_REL_ ZR_MIB_TOP_ab_Gen3 SG_ 2589283732 PLA_SDA_Re_Offset_8 5000;
BA_REL_ "GenSigTimeoutTime" BU_SG_REL_ ZR_MIB_TOP_ab_Gen3 SG_ 2589283732 PLA_SDA_Re_ID_8 5000;
BA_REL_ "GenSigTimeoutTime" BU_SG_REL_ ZR_MIB_TOP_ab_Gen3 SG_ 2589283732 PLA_SDA_Re_Offset_7 5000;
BA_REL_ "GenSigTimeoutTime" BU_SG_REL_ ZR_MIB_TOP_ab_Gen3 SG_ 2589283732 PLA_SDA_Re_ID_7 5000;
BA_REL_ "GenSigTimeoutTime" BU_SG_REL_ ZR_MIB_TOP_ab_Gen3 SG_ 2589283732 PLA_SDA_Re_Offset_6 5000;
BA_REL_ "GenSigTimeoutTime" BU_SG_REL_ ZR_MIB_TOP_ab_Gen3 SG_ 2589283732 PLA_SDA_Re_ID_6 5000;
BA_REL_ "GenSigTimeoutTime" BU_SG_REL_ ZR_MIB_TOP_ab_Gen3 SG_ 2589283732 PLA_SDA_Re_Offset_5 5000;
BA_REL_ "GenSigTimeoutTime" BU_SG_REL_ ZR_MIB_TOP_ab_Gen3 SG_ 2589283732 PLA_SDA_Re_ID_5 5000;
BA_REL_ "GenSigTimeoutTime" BU_SG_REL_ ZR_MIB_TOP_ab_Gen3 SG_ 2589283732 PLA_SDA_Re_Offset_4 5000;
BA_REL_ "GenSigTimeoutTime" BU_SG_REL_ ZR_MIB_TOP_ab_Gen3 SG_ 2589283732 PLA_SDA_Re_ID_4 5000;
BA_REL_ "GenSigTimeoutTime" BU_SG_REL_ ZR_MIB_TOP_ab_Gen3 SG_ 2589283732 PLA_SDA_Re_Offset_3 5000;
BA_REL_ "GenSigTimeoutTime" BU_SG_REL_ ZR_MIB_TOP_ab_Gen3 SG_ 2589283732 PLA_SDA_Re_ID_3 5000;
BA_REL_ "GenSigTimeoutTime" BU_SG_REL_ ZR_MIB_TOP_ab_Gen3 SG_ 2589283732 PLA_SDA_Re_Offset_2 5000;
BA_REL_ "GenSigTimeoutTime" BU_SG_REL_ ZR_MIB_TOP_ab_Gen3 SG_ 2589283732 PLA_SDA_Re_ID_2 5000;
BA_REL_ "GenSigTimeoutTime" BU_SG_REL_ ZR_MIB_TOP_ab_Gen3 SG_ 2589283732 PLA_SDA_Re_Offset_1 5000;
BA_REL_ "GenSigTimeoutTime" BU_SG_REL_ ZR_MIB_TOP_ab_Gen3 SG_ 2589283732 PLA_SDA_Re_ID_1 5000;
BA_REL_ "GenSigTimeoutTime" BU_SG_REL_ ZR_Standard SG_ 908 PACC_Systemstatus 1000;
BA_REL_ "GenSigTimeoutTime" BU_SG_REL_ ZR_Standard SG_ 872 PH2_Anf_Audioabsenkung 1000;
BA_REL_ "GenSigTimeoutTime" BU_SG_REL_ ZR_Standard SG_ 1175 PH_Anf_Audioabsenkung 1000;
BA_REL_ "GenSigTimeoutTime" BU_SG_REL_ ZR_Standard SG_ 2527679498 Perso_Kontonummer 5000;
BA_REL_ "GenSigTimeoutTime" BU_SG_REL_ ZR_Standard SG_ 2527679498 Perso_Steuerung 5000;
BA_REL_ "GenSigTimeoutTime" BU_SG_REL_ ZR_Standard SG_ 2527679498 Perso_Steuerungsparameter 5000;
BA_REL_ "GenSigTimeoutTime" BU_SG_REL_ ZR_Standard SG_ 2527679498 Perso_Status 5000;
BA_REL_ "GenSigTimeoutTime" BU_SG_REL_ ZR_Standard SG_ 2527679498 Perso_Fahrernummer 5000;
VAL_ 2527679670 OTA_FC_Hinweis_Update 0 "inaktiv" 1 "aktiv" ;
VAL_ 2527679670 OTA_FC_PredMaint_Ausfall 0 "inaktiv" 1 "aktiv" ;
VAL_ 2527679670 OTA_FC_Warnung_Update 0 "inaktiv" 1 "aktiv" ;
VAL_ 2527679670 OTA_FC_IOF_Ausfall 0 "inaktiv" 1 "aktiv" ;
VAL_ 2527679670 OTA_FC_FoD_Stornierung 0 "inaktiv" 1 "aktiv" ;
VAL_ 2527679670 OTA_FC_FahrwerkAnf 0 "KeineOTAFCAnf_Fahrwerk" 1 "OTAFCAnf_FahrwerkNormal" 2 "OTAFCAnf_FahrwerkSport" 3 "OTAFCAnf_FahrwerkSportPlus" ;
VAL_ 2527679670 OTA_FC_LiftAnf 0 "KeineOTAFCAnf_Lift" 1 "OTAFCAnf_Lift" ;
VAL_ 2527679670 OTA_FC_NiveauAnf 0 "KeineOTAFCAnf_Niveau" 1 "OTAFCAnf_NiveauSGN" 2 "OTAFCAnf_NiveauGN" 3 "OTAFCAnf_NiveauNN" 4 "OTAFCAnf_NiveauTN" 5 "OTAFCAnf_NiveauBN" ;
VAL_ 2527679670 ORU_EM_Anfrage_freigegebeneNetze 0 "only_12V" 1 "networks_48V_and_12V" 2 "networks_HV_and_12V" 3 "networks_HV_and_48V_and_12V" ;
VAL_ 2527679670 ORU_Status_Anf 0 "IDLE" 1 "PENDING" 2 "PREPARATION" 3 "PREPARATION_HV" 4 "RUNNING" 5 "RUNNING_HV" 6 "PENDING_NOTREADY" ;
VAL_ 908 PACC_Sytemstatus_Anzeige 0 "OFF" 1 "INIT" 2 "STANDBY" 3 "AKTIV_regelt" 4 "PASSIV" 5 "FEHLER_Karte" 6 "FEHLER_System" 7 "FEHLER_irreversibel" ;
VAL_ 908 PACC_Automode 0 "Automode_inaktiv" 1 "Automode_aktiv" ;
VAL_ 908 PACC_Segelanteil 0 "Init" ;
VAL_ 908 PACC_Durchschnittsgeschw 0 "Init" ;
VAL_ 908 PACC_Uebernahmeaufforderung 0 "keine_Uebernahmeaufforderung" 1 "Uebernahmeaufforderung" ;
VAL_ 908 PACC_Systemstatus 0 "OFF" 1 "INIT" 2 "STANDBY" 3 "AKTIV_regelt" 4 "PASSIV" 5 "FEHLER_Karte" 6 "FEHLER_System" 7 "FEHLER_Irreversibel" ;
VAL_ 908 PACC_Vorausschaugeschw 1023 "Init" ;
VAL_ 908 PACC_naechstes_Event 0 "Init" 1 "Tempolimit_5kmh" 2 "Tempolimit_10kmh" 3 "Tempolimit_15kmh" 4 "Tempolimit_20kmh" 5 "Tempolimit_25kmh" 6 "Tempolimit_30kmh" 7 "Tempolimit_35kmh" 8 "Tempolimit_40kmh" 9 "Tempolimit_45kmh" 10 "Tempolimit_50kmh" 11 "Tempolimit_55kmh" 12 "Tempolimit_60kmh" 13 "Tempolimit_65kmh" 14 "Tempolimit_70kmh" 15 "Tempolimit_75kmh" 16 "Tempolimit_80kmh" 17 "Tempolimit_90kmh" 18 "Tempolimit_100kmh" 19 "Tempolimit_110kmh" 20 "Tempolimit_120kmh" 21 "Tempolimit_130kmh" 22 "Tempolimit_140kmh" 23 "Tempolimit_150kmh" 24 "Tempolimit_160kmh" 25 "Tempolimit_unbegrenzt" 26 "Linkskurve" 27 "Rechtskurve" 28 "Kuppe" 29 "Steigung" 30 "Gefaelle" 31 "Kreuzung" 32 "Ampel" 33 "Bahnuebergang" 34 "Ortsanfang" 35 "Kreisverkehr" ;
VAL_ 233 Parken_Hindernis_Bereich 0 "Kein_Hindernis" 1 "Objekt_in_Bereich_1" 2 "Objekt_in_Bereich_2" 3 "Objekt_in_Bereich_3" 4 "Objekt_in_Bereich_4" 5 "Objekt_in_Bereich_5" 6 "Objekt_in_Bereich_6" 7 "Objekt_in_Bereich_7" 8 "Objekt_in_Bereich_8" 9 "Objekt_in_Bereich_9" 10 "Objekt_in_Bereich_10" 11 "Objekt_in_Bereich_11" 12 "Objekt_in_Bereich_12" 13 "Objekt_in_Bereich_13" 14 "Objekt_in_Bereich_14" 15 "Objekt_in_Bereich_15" ;
VAL_ 233 Parken_SM_Sensor 0 "Kamera_verschmutzt" 1 "Kamera_liefert_Bilddaten" ;
VAL_ 233 Parken_SM_Stillstand 0 "Kein_Stillstand" 1 "Stillstand" ;
VAL_ 233 Parken_SM_Schluessel 0 "Kein_Schluessel_vorhanden" 1 "Schluessel_vorhanden" ;
VAL_ 233 Parken_SM_Tueren 0 "Tuer_geoeffnet" 1 "Tueren_geschlossen" ;
VAL_ 233 Parken_SM_Anhaenger 0 "Kein_Anhaenger" 1 "Anhaenger_erkannt" ;
VAL_ 233 Parken_SM_Fahrbereitschaft 0 "Keine_Fahrbereitschaft" 1 "Fahrbereitschaft" ;
VAL_ 233 Parken_SM_Fahrstufe 0 "Falsche_Fahrstufe" 1 "Korrekte_Fahrstufe" ;
VAL_ 233 Parken_Anhaltegrund_ext 0 "Kein_Grund_aktiv" 1 "Stoerung" 2 "Funktion_nicht_verfuegbar" 3 "Tueren_Klappen" 4 "Verkehr_erkannt" 5 "Interaktion_erkannt" 6 "Eingriff_Fahrzeugsystem" 7 "Zeitlimit" 8 "Keine_Weiterfahrt_moeglich" 9 "Ladestecker_gesteckt" 10 "Empfang_gestoert" 11 "Ladezustand_gering" 12 "Land_nicht_zulaessig" 13 "Schluessel_Taste_betaetigt" 14 "Strecke_nicht_angelernt" 15 "Garagentor_oeffnen" 16 "Schluessel_im_Innenraum" 17 "Mehrere_Schluessel_gefunden" 18 "Offroad_aktiv" 19 "Luftfahrwerkhoehe_nio" 20 "Maximale_strecke_erreicht" 21 "Rangier_Flaeche_zu_klein" 22 "Abbruch_durch_GwSm" 23 "Maximale_Zuege_erreicht" 24 "Luecke_zu_klein" 25 "Schluessel_ausser_Reichweite" 26 "Hindernis_erkannt" 27 "Anhaenger_erkannt" 28 "Abbruch_ESC_Eingriff" 29 "PP_Fehler_Schluesselautorisier" 30 "Verlust_PP_PosOK" 31 "Abbruch_TSK_Steigung" 32 "Stby_Erhoehter_Fahrwiderstand" 33 "Abbruch_Erhoehter_Fahrwiderstand" 34 "KAB_VoKo_VKM_aus" 35 "KAB_VoKo_VKM_an" ;
VAL_ 233 Parken_Touchdiagnose_Anf 0 "Keine_Anf" 1 "Anf_Touchdiagnose" ;
VAL_ 233 Parken_BT_Wunsch 0 "kein_BT_erforderlich" 1 "BT_erwuenscht" ;
VAL_ 233 Parken_Hindernis_erkannt 0 "None" 1 "Obstacle_detected" ;
VAL_ 233 Parken_Fortschrittszaehler 127 "Init" ;
VAL_ 233 Parken_Anhaltegrund 0 "Kein_Grund_aktiv" 1 "Stoerung" 2 "Funktion_nicht_verfuegbar" 3 "Tueren_Klappen" 4 "Verkehr_erkannt" 5 "Interaktion_erkannt" 6 "Eingriff_Fahrzeugsystem" 7 "Zeitlimit" 8 "Keine_Weiterfahrt_moeglich" 9 "Ladestecker_gesteckt" 10 "Empfang_gestoert" 11 "Ladezustand_gering" 12 "Land_nicht_zulaessig" ;
VAL_ 233 Parken_Fahrtaster_Empfehlung 0 "No_Recommendation" 1 "Drive_1" 2 "Drive_2" ;
VAL_ 233 Parken_Aktives_Bedienelement 0 "None" 1 "Mobile_Device" 2 "Drive_Button" 3 "Key" ;
VAL_ 233 Parken_FFB_Status 0 "Init" 1 "Key_in_range" 2 "Key_leaving_range" 3 "Key_out_of_range" 4 "Key_invalid" ;
VAL_ 233 Parken_Reversieren_moeglich 0 "Reversing_not_possible" 1 "Reversing_possible" ;
VAL_ 233 Parken_Seite 0 "Init" 1 "Left" 2 "Right" 3 "Left_or_Right" 4 "Straight" 5 "Left_or_Straight" 6 "Right_or_Straight" 7 "Left_or_Right_or_Straight" ;
VAL_ 233 Parken_Seite_Aktiv 0 "Init" 1 "left" 2 "right" 3 "straight" ;
VAL_ 233 Parken_Szenario_Aktiv 0 "Init" 1 "Parallel" 2 "Perpendicular" 3 "Garage" 4 "Basic" 5 "Custom_Drive" 6 "TPA" 7 "AAA" ;
VAL_ 233 Parken_Manoever_Aktiv 0 "Init" 1 "Einparken" 2 "Ausparken" ;
VAL_ 233 Parken_Manoever 0 "Init" 1 "Einparken" 2 "Ausparken" 3 "Einparken_Ausparken" ;
VAL_ 233 Parken_Szenario 0 "Init" 1 "Parallel" 2 "Perpendicular" 3 "Parallel_or_Perpendicular" 4 "Garage" 5 "Garage_or_Parallel" 6 "Garage_or_Perpendicular" 7 "Garage_or_Parallel_or_Perpendicular" 8 "Basic" 9 "Basic_or_Parallel" 10 "Basic_or_Perpendicular" 11 "Basic_or_Parallel_or_Perpendicular" 12 "Basic_or_Garage" 13 "Basic_or_Garage_or_Parallel" 14 "Basic_or_Garage_or_Perpendicular" 15 "Basic_or_Garage_or_Parallel_or_Perpendicular" ;
VAL_ 233 Parken_Funktionsstatus 0 "Undefined" 1 "Starting_Up" 2 "Engine_Ready_to_Start" 3 "Ready_to_Start" 4 "In_Progress" 5 "Paused" 6 "Finished" 7 "Aborted_resuming_possible" 8 "Aborted_resuming_not_possible" 9 "Custom_Drive" 10 "Engine_Start_requested" ;
VAL_ 233 Parken_Richtung 0 "Init" 1 "Forward" 2 "Backward" 3 "Forward_or_Backward" ;
VAL_ 233 Parken_Richtung_Aktiv 0 "Init" 1 "Forward" 2 "Backward" ;
VAL_ 2463978635 Parken_Traj_Trans_ID 0 "Transaktions_ID_0" 1 "Transaktions_ID_1" 2 "Transaktions_ID_2" 3 "Transaktions_ID_3" 4 "Transaktions_ID_4" 5 "Transaktions_ID_5" 6 "Transaktions_ID_6" 7 "Transaktions_ID_7" 8 "Transaktions_ID_8" 9 "Transaktions_ID_9" 10 "Transaktions_ID_10" 11 "Transaktions_ID_11" 12 "Transaktions_ID_12" 13 "Transaktions_ID_13" 14 "Transaktions_ID_14" 15 "Transaktions_ID_15" ;
VAL_ 2463978635 Parken_Traj_aktueller_Zug 0 "init" 1 "Zug_1" 2 "Zug_2" 3 "Zug_3" 4 "Zug_4" 5 "Zug_5" 6 "Zug_6" 7 "Zug_7" 8 "Zug_8" 9 "Zug_9" 10 "Zug_10" 11 "Zug_11" 12 "Zug_12" 13 "Zug_13" 14 "Zug_14" 15 "Zug_15" ;
VAL_ 2463978635 Parken_Traj_Anzahl_Punkte 0 "init" 1 "Punkte_Anz_1" 2 "Punkte_Anz_2" 3 "Punkte_Anz_3" 4 "Punkte_Anz_4" 5 "Punkte_Anz_5" 6 "Punkte_Anz_6" 7 "Punkte_Anz_7" 8 "Punkte_Anz_8" 9 "Punkte_Anz_9" ;
VAL_ 2463978635 Parken_Traj_letzter_Zug 0 "Wendepunkt" 1 "Zielpunkt" ;
VAL_ 2463978635 Parken_Traj_Fahrtrichtung 0 "Fahrtrichtung_Vorwaerts" 1 "Fahrtrichtung_Rueckwaerts" ;
VAL_ 850 Parken_SM_03_MUX 0 "MUX_Gruppe_Punktinfo_0" 1 "MUX_Gruppe_Punktinfo_1" 2 "MUX_Gruppe_Punktinfo_2" 3 "MUX_Gruppe_Punktinfo_3" 4 "MUX_Gruppe_Punktinfo_4" 5 "MUX_Gruppe_Punktinfo_5" 6 "MUX_Gruppe_Punktinfo_6" ;
VAL_ 850 Parken_SM_03_Traj_Trans_ID_00 0 "Transaktions_ID_0" 1 "Transaktions_ID_1" 2 "Transaktions_ID_2" 3 "Transaktions_ID_3" 4 "Transaktions_ID_4" 5 "Transaktions_ID_5" 6 "Transaktions_ID_6" 7 "Transaktions_ID_7" 8 "Transaktions_ID_8" 9 "Transaktions_ID_9" 10 "Transaktions_ID_10" 11 "Transaktions_ID_11" 12 "Transaktions_ID_12" 13 "Transaktions_ID_13" 14 "Transaktions_ID_14" 15 "Transaktions_ID_15" ;
VAL_ 850 Parken_SM_03_Traj_Trans_ID_01 0 "Transaktions_ID_0" 1 "Transaktions_ID_1" 2 "Transaktions_ID_2" 3 "Transaktions_ID_3" 4 "Transaktions_ID_4" 5 "Transaktions_ID_5" 6 "Transaktions_ID_6" 7 "Transaktions_ID_7" 8 "Transaktions_ID_8" 9 "Transaktions_ID_9" 10 "Transaktions_ID_10" 11 "Transaktions_ID_11" 12 "Transaktions_ID_12" 13 "Transaktions_ID_13" 14 "Transaktions_ID_14" 15 "Transaktions_ID_15" ;
VAL_ 850 Parken_SM_03_Traj_Trans_ID_02 0 "Transaktions_ID_0" 1 "Transaktions_ID_1" 2 "Transaktions_ID_2" 3 "Transaktions_ID_3" 4 "Transaktions_ID_4" 5 "Transaktions_ID_5" 6 "Transaktions_ID_6" 7 "Transaktions_ID_7" 8 "Transaktions_ID_8" 9 "Transaktions_ID_9" 10 "Transaktions_ID_10" 11 "Transaktions_ID_11" 12 "Transaktions_ID_12" 13 "Transaktions_ID_13" 14 "Transaktions_ID_14" 15 "Transaktions_ID_15" ;
VAL_ 850 Parken_SM_03_Traj_Trans_ID_03 0 "Transaktions_ID_0" 1 "Transaktions_ID_1" 2 "Transaktions_ID_2" 3 "Transaktions_ID_3" 4 "Transaktions_ID_4" 5 "Transaktions_ID_5" 6 "Transaktions_ID_6" 7 "Transaktions_ID_7" 8 "Transaktions_ID_8" 9 "Transaktions_ID_9" 10 "Transaktions_ID_10" 11 "Transaktions_ID_11" 12 "Transaktions_ID_12" 13 "Transaktions_ID_13" 14 "Transaktions_ID_14" 15 "Transaktions_ID_15" ;
VAL_ 850 Parken_SM_03_Traj_Trans_ID_04 0 "Transaktions_ID_0" 1 "Transaktions_ID_1" 2 "Transaktions_ID_2" 3 "Transaktions_ID_3" 4 "Transaktions_ID_4" 5 "Transaktions_ID_5" 6 "Transaktions_ID_6" 7 "Transaktions_ID_7" 8 "Transaktions_ID_8" 9 "Transaktions_ID_9" 10 "Transaktions_ID_10" 11 "Transaktions_ID_11" 12 "Transaktions_ID_12" 13 "Transaktions_ID_13" 14 "Transaktions_ID_14" 15 "Transaktions_ID_15" ;
VAL_ 850 Parken_SM_03_Traj_Trans_ID_05 0 "Transaktions_ID_0" 1 "Transaktions_ID_1" 2 "Transaktions_ID_2" 3 "Transaktions_ID_3" 4 "Transaktions_ID_4" 5 "Transaktions_ID_5" 6 "Transaktions_ID_6" 7 "Transaktions_ID_7" 8 "Transaktions_ID_8" 9 "Transaktions_ID_9" 10 "Transaktions_ID_10" 11 "Transaktions_ID_11" 12 "Transaktions_ID_12" 13 "Transaktions_ID_13" 14 "Transaktions_ID_14" 15 "Transaktions_ID_15" ;
VAL_ 850 Parken_SM_03_Traj_Trans_ID_06 0 "Transaktions_ID_0" 1 "Transaktions_ID_1" 2 "Transaktions_ID_2" 3 "Transaktions_ID_3" 4 "Transaktions_ID_4" 5 "Transaktions_ID_5" 6 "Transaktions_ID_6" 7 "Transaktions_ID_7" 8 "Transaktions_ID_8" 9 "Transaktions_ID_9" 10 "Transaktions_ID_10" 11 "Transaktions_ID_11" 12 "Transaktions_ID_12" 13 "Transaktions_ID_13" 14 "Transaktions_ID_14" 15 "Transaktions_ID_15" ;
VAL_ 872 PH2_Visualisierung 0 "Aus" 1 "Angefragt" 2 "InAnzeige" 3 "Abgefordert" 6 "Init" 7 "Fehler" ;
VAL_ 872 PDC2_Tonausgabe_Front 0 "kein_Ton" 1 "Intervallton_1" 2 "Intervallton_2" 3 "Intervallton_3" 4 "Intervallton_4" 5 "Intervallton_5" 6 "Dauerton" 7 "Fehlerton" 8 "FCTAton" ;
VAL_ 872 PDC2_Tonausgabe_Heck 0 "kein_Ton" 1 "Intervallton_1" 2 "Intervallton_2" 3 "Intervallton_3" 4 "Intervallton_4" 5 "Intervallton_5" 6 "Dauerton" 7 "Fehlerton" 8 "Erstwarnton_hinten" 9 "RCTATon" ;
VAL_ 872 PH2_nachtr_Stopp_An 0 "nicht_angefordert" 1 "angefordert" ;
VAL_ 872 PH2_Abschaltursache 0 "keine, bzw. System aktiv" 1 "Abschaltung durch Herausnahme R-Gang" 2 "Abschaltung ueber Geschwindigkeit" 3 "Abschaltung ueber PDC-Taster" 4 "Abschaltung wegen PLA" 5 "Abschaltung durch KL 15 Bit = 0" 6 "tbd." 7 "Fehler-/gestört Zustand, System noch aktiv" ;
VAL_ 872 PH2_Opt_Anzeige_V_ein 0 "optische Anzeige vorne nicht aktiv" 1 "optische Anzeige vorne aktiviert" ;
VAL_ 872 PH2_Opt_Anzeige_H_ein 0 "Optische Anzeige aus" 1 "optische Anzeige hinten aktiviert" ;
VAL_ 872 PH2_Opt_Anz_V_Hindernis 0 "optische Anzeige vorne meldet kein Hindernis" 1 "optische Anzeige vorne meldet Hindernis im Warnbereich" ;
VAL_ 872 PH2_Opt_Anz_H_Hindernis 0 "optische Anzeige hinten meldet kein Hindernis" 1 "optische Anzeige hinten meldet Hindernis im Warnbereich" ;
VAL_ 872 PH2_Tongeber_V_aktiv 0 "Tongeber vorne nicht aktiv" 1 "Tongeber vorne  aktiv" ;
VAL_ 872 PH2_Tongeber_H_aktiv 0 "Tongeber hinten nicht aktiv" 1 "Tongeber hinten aktiv" ;
VAL_ 872 PH2_Tongeber_mute 0 "Tongeber nicht stummgeschaltet" 1 "Tongeber stummgeschaltet" ;
VAL_ 872 PH2_Anf_Audioabsenkung 0 "keine Absenkung der Lautstärke" 1 "Anforderung an das Audiosystem für Absenkung der Lautstärke" ;
VAL_ 872 PH2_Tongeber_H_verfuegbar 0 "nicht verfügbar" 1 "verfügbar" ;
VAL_ 872 PH2_Taster 0 "Taster_nicht_gedrueckt" 1 "Taster_gedrueckt" 2 "reserviert" 3 "Fehler" ;
VAL_ 872 PH2_Anf_Verdeck 0 "Verdeckbetrieb_freigegeben" 1 "Verdeckbetrieb_sperren" 2 "reserviert" 3 "reserviert" ;
VAL_ 872 PH2_StartStopp_Info 0 "Motorlauf_nicht_notwendig_(Stoppfreigabe)" 1 "Motoranlauf_nicht_zwingend_notwendig_(Stoppverbot,keine_Startanforderung)" 2 "Motoranlauf_zwingend_notwendig_(Startanforderung)" 3 "Systemfehler" ;
VAL_ 872 PH2_Stoermeldung 0 "keine_Anzeige_kein_Gong" 1 "Textmeldung_PDC_hinten_gestoert_mit_Gong" 2 "Textmeldung_PDC_hinten_gestoert_ohne_Gong" 3 "Textmeldung_PDC_vorn_gestoert_mit_Gong" 4 "Textmeldung_PDC_vorn_gestoert_ohne_Gong" 5 "Textmeldung_PDC_gestoert_mit_Gong" 6 "Textmeldung_PDC_gestoert_ohne_Gong" 7 "Textmeldung_PDC_seitlich_gestoert_mit_Gong" 8 "Textmeldung_PDC_seitlich_gestoert_ohne_Gong" ;
VAL_ 872 PH2_defekt 0 "PH aktiv" 1 "PH wurde aufgrund eines Defektes deaktiviert" ;
VAL_ 872 PH2_gestoert 0 "PH aktiv" 1 "PH wurde auf Grund einer Stoerung tempraer deaktiviert" ;
VAL_ 872 PH2_Systemzustand 0 "Anlage aus" 1 "Anlage durch einlegen R-Gang aktiviert" 2 "Anlage manuell durch Taster aktiviert" 3 "Anlage automatisch aktiviert" 4 "Anlage_durch_ARA_aktiviert" 6 "Init_Initialisierungsphase_nach_Kl15_ein_oder_Reset" 7 "Fehler-/gestört Zustand, System noch aktiv" ;
VAL_ 872 PH2_Display_Kundenwunsch 0 "Anzeige aus" 1 "Grafik" 2 "Rear View" 3 "automatisch" ;
VAL_ 1175 PH_Visualisierung 0 "Aus" 1 "Angefragt" 2 "InAnzeige" 3 "Abgefordert" 6 "Init" 7 "Fehler" ;
VAL_ 1175 PDC_Tonausgabe_Front 0 "kein_Ton" 1 "Intervallton_1" 2 "Intervallton_2" 3 "Intervallton_3" 4 "Intervallton_4" 5 "Intervallton_5" 6 "Dauerton" 7 "Fehlerton" 8 "RCTATon" ;
VAL_ 1175 PDC_Tonausgabe_Heck 0 "kein_Ton" 1 "Intervallton_1" 2 "Intervallton_2" 3 "Intervallton_3" 4 "Intervallton_4" 5 "Intervallton_5" 6 "Dauerton" 7 "Fehlerton" 8 "Erstwarnton_hinten" 9 "RCTATon" ;
VAL_ 1175 PH_nachtr_Stopp_Anf 0 "nicht_angefordert" 1 "angefordert" ;
VAL_ 1175 PH_Abschaltursache 0 "keine, bzw. System aktiv" 1 "Abschaltung durch Herausnahme R-Gang" 2 "Abschaltung ueber Geschwindigkeit" 3 "Abschaltung ueber PDC-Taster" 4 "Abschaltung wegen PLA" 5 "Abschaltung durch KL 15 Bit = 0" 6 "tbd." 7 "Fehler-/gestört Zustand, System noch aktiv" ;
VAL_ 1175 PH_Opt_Anzeige_V_ein 0 "optische Anzeige vorne nicht aktiv" 1 "optische Anzeige vorne aktiviert" ;
VAL_ 1175 PH_Opt_Anzeige_H_ein 0 "Optische Anzeige aus" 1 "optische Anzeige hinten aktiviert" ;
VAL_ 1175 PH_Opt_Anz_V_Hindernis 0 "optische Anzeige vorne meldet kein Hindernis" 1 "optische Anzeige vorne meldet Hindernis im Warnbereich" ;
VAL_ 1175 PH_Opt_Anz_H_Hindernis 0 "optische Anzeige hinten meldet kein Hindernis" 1 "optische Anzeige hinten meldet Hindernis im Warnbereich" ;
VAL_ 1175 PH_Tongeber_V_aktiv 0 "Tongeber vorne nicht aktiv" 1 "Tongeber vorne  aktiv" ;
VAL_ 1175 PH_Tongeber_H_aktiv 0 "Tongeber hinten nicht aktiv" 1 "Tongeber hinten aktiv" ;
VAL_ 1175 PH_Tongeber_mute 0 "Tongeber nicht stummgeschaltet" 1 "Tongeber stummgeschaltet" ;
VAL_ 1175 PH_Anf_Audioabsenkung 0 "Keine_Audioabsenkung" 1 "Anforderung_Audioabsenkung" ;
VAL_ 1175 PH_Tongeber_H_verfuegbar 0 "nicht verfügbar" 1 "verfügbar" ;
VAL_ 1175 PLA_Anf_Aufschaltung_RVC 0 "Keine_RVC_Aufschalteanf" 1 "RVC_Aufschalteanforderung" ;
VAL_ 1175 PH_Taster 0 "Taster_nicht_gedrueckt" 1 "Taster_gedrueckt" 2 "reserviert" 3 "Fehler" ;
VAL_ 1175 PH_Anf_Verdeck 0 "Verdeckbetrieb_freigegeben" 1 "Verdeckbetrieb_sperren" 2 "reserviert" 3 "reserviert" ;
VAL_ 1175 PH_StartStopp_Info 0 "Motorlauf_nicht_notwendig_(Stoppfreigabe)" 1 "Motoranlauf_nicht_zwingend_notwendig_(Stoppverbot,keine_Startanforderung)" 2 "Motoranlauf_zwingend_notwendig_(Startanforderung)" 3 "Systemfehler" ;
VAL_ 1175 PH_Stoermeldung 0 "keine_Anzeige_kein_Gong" 1 "Textmeldung_PDC_hinten_gestoert_mit_Gong" 2 "Textmeldung_PDC_hinten_gestoert_ohne_Gong" 3 "Textmeldung_PDC_vorn_gestoert_mit_Gong" 4 "Textmeldung_PDC_vorn_gestoert_ohne_Gong" 5 "Textmeldung_PDC_gestoert_mit_Gong" 6 "Textmeldung_PDC_gestoert_ohne_Gong" 7 "Textmeldung_PDC_seitlich_gestoert_mit_Gong" 8 "Textmeldung_PDC_seitlich_gestoert_ohne_Gong" ;
VAL_ 1175 PH_defekt 0 "PH aktiv" 1 "PH wurde aufgrund eines Defektes deaktiviert" ;
VAL_ 1175 PH_gestoert 0 "PH aktiv" 1 "PH wurde auf Grund einer Stoerung tempraer deaktiviert" ;
VAL_ 1175 PH_Systemzustand 0 "Anlage aus" 1 "Anlage durch einlegen R-Gang aktiviert" 2 "Anlage manuell durch Taster aktiviert" 3 "Anlage automatisch aktiviert" 4 "Anlage durch ARA aktiviert" 6 "Init - Initialisierungsphase nach Kl. 15 ein / Reset" 7 "Fehler-/gestört Zustand, System noch aktiv" ;
VAL_ 1175 PH_Display_Kundenwunsch 0 "Anzeige aus" 1 "Grafik" 2 "Rear View" 3 "automatisch" ;
VAL_ 1355 PH_Verschmutzungsmeldung 0 "keine_Anzeige_kein_Gong" 1 "Textmeldung_PDC_hinten_verschmutzt_mit_Gong" 2 "Textmeldung_PDC_hinten_verschmutzt_ohne_Gong" 3 "Textmeldung_PDC_vorn_verschmutzt_mit_Gong" 4 "Textmeldung_PDC_vorn_verschmutzt_ohne_Gong" 5 "Textmeldung_PDC_verschmutzt_mit_Gong" 6 "Textmeldung_PDC_verschmutzt_ohne_Gong" 7 "Textmeldung_PDC_seitlich_verschmutzt_mit_Gong" 8 "Textmeldung_PDC_seitlich_verschmutzt_ohne_Gong" ;
VAL_ 1355 PH_Aufschaltursache 0 "Anlage aus" 1 "Anlage durch einlegen R-Gang aktiviert" 2 "Anlage manuell durch Taster aktiviert" 3 "Anlage automatisch aktiviert" 4 "Anlage durch ARA aktiviert" 5 "Rueckwaertsrollen" 6 "Anlage_durch_PLA_aktiviert" 7 "Anlage_durch_IPA_aktiviert" 8 "Anlage_durch_FA_aktiviert" 9 "Anlage_durch_RBF_oder_MA_aktiviert" 10 "Anlage_durch_Smartphone_aktiviert" 11 "Anlage_durch_Jokertaste_aktiviert" 12 "Anlage_durch_Favoritentasten_aktiviert" 13 "Anlage_durch_SideViewTaster_aktiviert" 14 "Anlage_durch_RCTA_aktiviert" 15 "Anlage_durch_KAS_aktiviert" 16 "Anlage_durch_AWC_aktiviert" 30 "Init_Initialisierungsphase_nach_Kl_15_ein_oder_Reset" 31 "Fehler_gestoerter_Zustand_System_noch_aktiv" ;
VAL_ 1355 PH_Ton_Ausgabe 0 "Init" 1 "Intervallton_vorne" 2 "Intervallton_hinten" 3 "Dauerton_vorne" 4 "Dauerton_hinten" 5 "Quittierungston" 6 "Reserviert" 7 "Fehler" ;
VAL_ 1355 PH_Ton_Pausenlaenge 0 "Init" 1 "Pause_5ms" 2 "Pause_10ms" 3 "Pause_15ms" 100 "Pause_500ms" 101 "Reserviert" 126 "Reserviert" 127 "Fehler" ;
VAL_ 1355 PH_Ton_Richtung 0 "vorne" 1 "vorne_rechts" 2 "rechts" 3 "rechts_hinten" 4 "hinten" 5 "hinten_links" 6 "links" 7 "vorne_links" ;
VAL_ 1355 PH_Ton_Lautstaerke 0 "Minimallautstaerke" 1 "Lautstaerke_1" 2 "Lautstaerke_2" 3 "Lautstaerke_3" 4 "Lautstaerke_4" 5 "Lautstaerke_5" 6 "Lautstaerke_6" 7 "Maximallautstaerke" ;
VAL_ 1355 BCM_WAH_Meldung 0 "Init" 1 "Fehlermeldung_bei_Nichtverfuegbarkeit_mit_Gong" 2 "Fehlermeldung_bei_Nichtverfuegbarkeit_ohne_Gong" 3 "Anzeige_dass_Fahrzeug_erkannt_wurde_und_Funktion_aktiv_ist" 4 "Wiederanfahrhinweis_mit_Gong" 5 "Wiederanfahrhinweis_ohne_Gong" ;
VAL_ 1355 PDC_Charisma_Status 0 "Init" 1 "verfuegbar" 2 "nicht_verfuegbar" 3 "asynchron_durch_Fahrerwunsch" ;
VAL_ 1355 PDC_Charisma_FahrPr 0 "keine_Funktion" 1 "Programm_1" 2 "Programm_2" 3 "Programm_3" 4 "Programm_4" 5 "Programm_5" 6 "Programm_6" 7 "Programm_7" 8 "Programm_8" 9 "Programm_9" 10 "Programm_10" 11 "Programm_11" 12 "Programm_12" 13 "Programm_13" 14 "Programm_14" 15 "Programm_15" ;
VAL_ 803 SC_WarnBrems_Texte 0 "keine_Anzeige" 1 "Systemstoerung" 2 "keine_Sensorsicht" 3 "Demomodus" 4 "System_aus" 5 "Anhaengerbetrieb" 6 "ESC_aus" 7 "zurzeit_eingeschraenkt" 8 "zurzeit_eingeschraenkt_ESP_Aus" 9 "Initialisierung" ;
VAL_ 803 SC_AbstWarn_Texte 0 "keine_Anzeige" 1 "Systemstoerung" 2 "keine_Sensorsicht" 3 "Demomodus" 4 "System_aus" 5 "Anhaengerbetrieb" 6 "ESC_aus" 7 "zurzeit_eingeschraenkt" 8 "zurzeit_eingeschraenkt_ESP_Aus" 9 "Initialisierung" ;
VAL_ 803 PCF_Verz_Anf_ASIL 0 "Nicht_verfuegbar" 1 "Verz_Anf_ASIL_QM" 2 "Verz_Anf_ASIL_A" 3 "Verz_Anf_ASIL_B" 4 "Verz_Anf_ASIL_C" 5 "Verz_Anf_ASIL_D" 6 "reserved" 7 "reserved" ;
VAL_ 803 PCF_Verz_Auspraegung 0 "Standard" 1 "Erweitert" ;
VAL_ 803 PCF_Prefill_Anf 0 "Prefill_nicht_aktivieren" 1 "Prefill_aktivieren" ;
VAL_ 803 PCF_HBA_Param 0 "Defaultparametersatz" 1 "Param_leicht_erh_Empfindlichkeit" 2 "Param_erh_Empfindlichkeit" 3 "Param_hoechste_Empfindlichkeit" ;
VAL_ 803 PCF_Ruckprofil 0 "keine_Ruckanforderung" 1 "Profil_1" 2 "Profil_2" 3 "Profil_3" 4 "Profil_4" 5 "Profil_5" 6 "Profil_6" 7 "Profil_7" ;
VAL_ 803 PCF_Verz_Info 0 "keine_Anforderung" 1 "Teilbremsung_Stufe1" 2 "Teilbremsung_Stufe2" 3 "Zielbremsung_fahrergetriggert" 4 "Notbremsung_geregelt" 5 "Notbremsung_gesteuert" 6 "Abbiegebremsen_Angef" ;
VAL_ 803 PCF_Verz_Anf 834 "Init" ;
VAL_ 2527679498 Perso_Kontonummer 0 "kein_Benutzerkonto" 1 "Benutzerkonto_1" 2 "Benutzerkonto_2" 3 "Benutzerkonto_3" 4 "Benutzerkonto_4" 5 "Benutzerkonto_5" 6 "Benutzerkonto_6" 7 "Benutzerkonto_7" ;
VAL_ 2527679498 Perso_Steuerung 0 "keine_Steuerung" 1 "Reset_alle_Konten" 2 "Reset_aktives_Konto" 3 "Kopiere_aktives_Konto_nach" 4 "Wiederherstellen_aktives_Konto" 5 "Aktivieren_aktives_Konto" 6 "Reset_Konto" 7 "Reset_alle_Fahrer" 8 "Reset_aktiver_Fahrer" 9 "Reset_Fahrer" ;
VAL_ 2527679498 Perso_Steuerungsparameter 0 "kein_Parameter" 1 "Benutzerkonto_1" 2 "Benutzerkonto_2" 3 "Benutzerkonto_3" 4 "Benutzerkonto_4" 5 "Benutzerkonto_5" 6 "Benutzerkonto_6" 7 "Benutzerkonto_7" ;
VAL_ 2527679498 Perso_Status 0 "deaktiviert" 1 "PSO_1x_aktiviert" 2 "PSO_2x_aktiviert" ;
VAL_ 2527679498 Perso_Bedienstelle 0 "Init" 1 "Kombiinstrument" 2 "ABT" ;
VAL_ 2527679498 Perso_Freigabe_Verstellung 0 "Init" 1 "freigegeben" ;
VAL_ 2527679498 Perso_Aktiv 0 "deaktiviert" 1 "aktiviert" ;
VAL_ 2527679498 IAA_PSO_wake_up 0 "wake_up_inactive" 1 "wake_up_active" ;
VAL_ 2527679498 Perso_Fahrernummer 0 "kein_Fahrer" 1 "Fahrer_1" 2 "Fahrer_2" 3 "Fahrer_3" 4 "Fahrer_4" 5 "Fahrer_5" 6 "Fahrer_6" 7 "Fahrer_7" ;
VAL_ 2527679498 Perso_Schreibschutz 0 "Schreibschutz_deaktiviert" 1 "Schreibschutz_aktiviert" ;
VAL_ 2463978756 PSO_last_rec_UserID_Src1 0 "Init" 1 "BCM_UserID_1" 2 "BCM_UserID_2" 3 "BCM_UserID_3" 4 "BCM_UserID_4" 5 "BCM_UserID_5" 6 "BCM_UserID_6" 7 "BCM_UserID_7" 8 "BCM_UserID_8" 9 "BCM_UserID_9" 10 "BCM_UserID_10" 11 "BCM_UserID_11" 12 "BCM_UserID_12" 13 "BCM_UserID_13" 14 "BCM_UserID_14" 15 "BCM_UserID_15" ;
VAL_ 381 PLA2_Zahnstangen_Pos_Soll 4094 "Inaktiv" ;
VAL_ 381 PLA2_VZ_Zahnstangen_Pos_Soll 0 "positiv" 1 "negativ" ;
VAL_ 381 PLA2_Status_PLA_EPS 0 "reserviert" 1 "reserviert" 2 "reserviert" 3 "reserviert" 4 "PLA_EPS_aktivierbar" 5 "reserviert" 6 "PLA_EPS_Lenkwinkel_aktiv" 7 "reserviert" 8 "PLA_EPS_funktionsbereit" 9 "PLA_EPS_Neustart" 10 "PLA_EPS_Abbruch" 11 "reserviert" 12 "reserviert" 13 "reserviert" 14 "reserviert" 15 "reserviert" ;
VAL_ 381 PLA2_Anhalteweg 2045 "Neutralwert" 2046 "Init" 2047 "Fehler" ;
VAL_ 304 PLA_Status_PLA_ESP 0 "PLA_ESP_Deaktiv" 1 "PLA_ESP_Init" 2 "PLA_ESP_Fehler" 3 "reserviert" 4 "PLA_ESP_aktivierbar" 5 "reserviert" 6 "PLA_ESP_Bremse_aktiv" 7 "reserviert" 8 "PLA_ESP_funktionsbereit" 9 "PLA_ESP_Neustart" 10 "PLA_ESP_Abbruch" 11 "reserviert" 12 "reserviert" 13 "reserviert" 14 "reserviert" 15 "reserviert" ;
VAL_ 304 PLA_Zahnstangen_Pos_Soll 4094 "Init" ;
VAL_ 304 PLA_VZ_Zahnstangen_Pos_Soll 0 "positiv" 1 "negativ" ;
VAL_ 304 PLA_Status_PLA_EPS 0 "reserviert" 1 "reserviert" 2 "reserviert" 3 "reserviert" 4 "PLA_EPS_aktivierbar" 5 "reserviert" 6 "PLA_EPS_Lenkwinkel_aktiv" 7 "reserviert" 8 "PLA_EPS_funktionsbereit" 9 "PLA_EPS_Neustart" 10 "PLA_EPS_Abbruch" 11 "reserviert" 12 "reserviert" 13 "reserviert" 14 "reserviert" 15 "reserviert" ;
VAL_ 304 PLA_Bremsverzoegerung 126 "Init" 127 "Fehler" ;
VAL_ 304 PLA_Anf_Bremsverzoegerung 0 "keine_Bremsverzoegerung" 1 "Bremsverzoegerung" ;
VAL_ 304 PLA_BremsMom_Verzoeg 0 "Bremsmoment" 1 "Bremsverzoegerung" ;
VAL_ 304 PLA_01_Signal_red_cyclic 0 "Langsame_Zykluszeit_aktiv" 1 "Schnelle_Zykluszeit_aktiv" ;
VAL_ 2589283731 PLA_SDA_Status 0 "nicht_aktiv" 1 "aktiv" ;
VAL_ 2589283731 PLA_SDA_Aktive_Seite 0 "Rechts" 1 "Links" ;
VAL_ 2589283731 PLA_SDA_Exist 0 "keine_Parkluecke" 1 "Parkluecke" ;
VAL_ 2589283731 PLA_SDA_Laengs_Querluecke 0 "Laengsluecke" 1 "Querluecke" ;
VAL_ 2589283731 PLA_SDA_Li_Offset_8 30 "Codierung_1" 31 "Codierung_2" ;
VAL_ 2589283731 PLA_SDA_Li_ID_8 0 "Ende_eines_Objektes" 1 "Anfang_eines_Objektes" 2 "Objekt_mit_konstantem_Abstand" 3 "Objekt_mit_variablem_Abstand" ;
VAL_ 2589283731 PLA_SDA_Li_Offset_7 30 "Codierung_1" 31 "Codierung_2" ;
VAL_ 2589283731 PLA_SDA_Li_ID_7 0 "Ende_eines_Objektes" 1 "Anfang_eines_Objektes" 2 "Objekt_mit_konstantem_Abstand" 3 "Objekt_mit_variablem_Abstand" ;
VAL_ 2589283731 PLA_SDA_Li_Offset_6 30 "Codierung_1" 31 "Codierung_2" ;
VAL_ 2589283731 PLA_SDA_Li_ID_6 0 "Ende_eines_Objektes" 1 "Anfang_eines_Objektes" 2 "Objekt_mit_konstantem_Abstand" 3 "Objekt_mit_variablem_Abstand" ;
VAL_ 2589283731 PLA_SDA_Li_Offset_5 30 "Codierung_1" 31 "Codierung_2" ;
VAL_ 2589283731 PLA_SDA_Li_ID_5 0 "Ende_eines_Objektes" 1 "Anfang_eines_Objektes" 2 "Objekt_mit_konstantem_Abstand" 3 "Objekt_mit_variablem_Abstand" ;
VAL_ 2589283731 PLA_SDA_Li_Offset_4 30 "Codierung_1" 31 "Codierung_2" ;
VAL_ 2589283731 PLA_SDA_Li_ID_4 0 "Ende_eines_Objektes" 1 "Anfang_eines_Objektes" 2 "Objekt_mit_konstantem_Abstand" 3 "Objekt_mit_variablem_Abstand" ;
VAL_ 2589283731 PLA_SDA_Li_Offset_3 30 "Codierung_1" 31 "Codierung_2" ;
VAL_ 2589283731 PLA_SDA_Li_ID_3 0 "Ende_eines_Objektes" 1 "Anfang_eines_Objektes" 2 "Objekt_mit_konstantem_Abstand" 3 "Objekt_mit_variablem_Abstand" ;
VAL_ 2589283731 PLA_SDA_Li_Offset_2 30 "Codierung_1" 31 "Codierung_2" ;
VAL_ 2589283731 PLA_SDA_Li_ID_2 0 "Ende_eines_Objektes" 1 "Anfang_eines_Objektes" 2 "Objekt_mit_konstantem_Abstand" 3 "Objekt_mit_variablem_Abstand" ;
VAL_ 2589283731 PLA_SDA_Li_Offset_1 30 "Codierung_1" 31 "Codierung_2" ;
VAL_ 2589283731 PLA_SDA_Li_ID_1 0 "Ende_eines_Objektes" 1 "Anfang_eines_Objektes" 2 "Objekt_mit_konstantem_Abstand" 3 "Objekt_mit_variablem_Abstand" ;
VAL_ 2589283732 PLA_SDA_Re_Offset_8 30 "Codierung_1" 31 "Codierung_2" ;
VAL_ 2589283732 PLA_SDA_Re_ID_8 0 "Ende_eines_Objektes" 1 "Anfang_eines_Objektes" 2 "Objekt_mit_konstantem_Abstand" 3 "Objekt_mit_variablem_Abstand" ;
VAL_ 2589283732 PLA_SDA_Re_Offset_7 30 "Codierung_1" 31 "Codierung_2" ;
VAL_ 2589283732 PLA_SDA_Re_ID_7 0 "Ende_eines_Objektes" 1 "Anfang_eines_Objektes" 2 "Objekt_mit_konstantem_Abstand" 3 "Objekt_mit_variablem_Abstand" ;
VAL_ 2589283732 PLA_SDA_Re_Offset_6 30 "Codierung_1" 31 "Codierung_2" ;
VAL_ 2589283732 PLA_SDA_Re_ID_6 0 "Ende_eines_Objektes" 1 "Anfang_eines_Objektes" 2 "Objekt_mit_konstantem_Abstand" 3 "Objekt_mit_variablem_Abstand" ;
VAL_ 2589283732 PLA_SDA_Re_Offset_5 30 "Codierung_1" 31 "Codierung_2" ;
VAL_ 2589283732 PLA_SDA_Re_ID_5 0 "Ende_eines_Objektes" 1 "Anfang_eines_Objektes" 2 "Objekt_mit_konstantem_Abstand" 3 "Objekt_mit_variablem_Abstand" ;
VAL_ 2589283732 PLA_SDA_Re_Offset_4 30 "Codierung_1" 31 "Codierung_2" ;
VAL_ 2589283732 PLA_SDA_Re_ID_4 0 "Ende_eines_Objektes" 1 "Anfang_eines_Objektes" 2 "Objekt_mit_konstantem_Abstand" 3 "Objekt_mit_variablem_Abstand" ;
VAL_ 2589283732 PLA_SDA_Re_Offset_3 30 "Codierung_1" 31 "Codierung_2" ;
VAL_ 2589283732 PLA_SDA_Re_ID_3 0 "Ende_eines_Objektes" 1 "Anfang_eines_Objektes" 2 "Objekt_mit_konstantem_Abstand" 3 "Objekt_mit_variablem_Abstand" ;
VAL_ 2589283732 PLA_SDA_Re_Offset_2 30 "Codierung_1" 31 "Codierung_2" ;
VAL_ 2589283732 PLA_SDA_Re_ID_2 0 "Ende_eines_Objektes" 1 "Anfang_eines_Objektes" 2 "Objekt_mit_konstantem_Abstand" 3 "Objekt_mit_variablem_Abstand" ;
VAL_ 2589283732 PLA_SDA_Re_Offset_1 30 "Codierung_1" 31 "Codierung_2" ;
VAL_ 2589283732 PLA_SDA_Re_ID_1 0 "Ende_eines_Objektes" 1 "Anfang_eines_Objektes" 2 "Objekt_mit_konstantem_Abstand" 3 "Objekt_mit_variablem_Abstand" ;
VAL_ 1166 PLA_Anforderung_HMS 0 "keine_Anforderung_Init" 1 "Halten" 2 "Parken" 3 "Halten_standby" 4 "Anfahren" 5 "Loesen_ueber_Rampe" 6 "Parken_mit_P" 7 "reserviert" ;
VAL_ 1166 PLA_Status_Aktive_Seite 0 "Rechts" 1 "Links" ;
VAL_ 1166 PLA_Anf_Anzeige_Mini 0 "keine_Anzeige" 1 "Miniaturanzeige" ;
VAL_ 1166 PLA_Mini_Modus 0 "kein_Mini_angezeigt" 1 "Mini_Laengsparken" 2 "Mini_Rueckwaerts_Querparken_mit_Vorbeifahrt" 3 "Mini_Vorwaerts_Querparken_ohne_VB" 4 "Mini_Vorwaerts_Querparken_mit_VB" 5 "weitere_Parkmoeglichkeit_vorhanden" 6 "Garagenparken" 7 "Mini_Rueckwaerts_Querparken_ohne_Vorbeifahrt" ;
VAL_ 1166 PLA_Anf_Akustik 0 "keine_Akustik" 1 "Akustik__Gong_1000" ;
VAL_ 1166 PLA_Anf_Anzeige_Schwellpfeil 0 "Keine_Schwellpfeilanzeige" 1 "Anzeige_Schwellpfeil" ;
VAL_ 1166 PLA_Anf_Anzeige_Bremsfuss 0 "Keine_Anzeige_Bremsfuss" 1 "Anzeige_Bremsfuss" ;
VAL_ 1166 PLA_Anf_Anzeigemodus 0 "Keine_Anzeige" 1 "Anzeige_AP_verfuegbar" 2 "Laengsparken_Singlescreen" 3 "Reserved" 4 "Rueckwaerts_Querparken_mit_VB" 5 "Rueckwaerts_Querparken_ohne_VB" 6 "Vorwaerts_Querparken_ohne_VB" 7 "Vorwaerts_Querparken_mit_VB" 8 "Ausparken_Laengsparken_Single" 9 "Garagenparken_vorwaerts" 10 "Garagenparken_rueckwaerts" 11 "Textmeldung_hochprior" 12 "Textmeldungen_niederprior" 13 "Anzeige_beidseitig" 14 "Anzeige_einseitig" 15 "Anzeige_PL_verfuegbar" ;
VAL_ 1166 PLA_Anf_Meldungen 0 "keine_Meldung" 1 "PLA_beendet" 2 "RBF_deaktiviert" 3 "Autosuche_ESC_ASR_Eingriff" 4 "PLA_temp_n_a_ESC_ASR_Fehler" 5 "PLA_temp_n_a_Anhaenger_gesteckt" 6 "Suche_Zeitlimit_ueberschritten" 7 "PLA_zurzeit_n_verfuegbar" 8 "PLA_defekt_Werkstatt" 9 "Stillstandzeit_n_ausreichend" 11 "AP_Blinker_setzen_u_RWG_einlegen" 12 "AP_n_moeglich_PL_zu_klein" 13 "RBF_aktiv" 14 "PLA_beendet_v_zu_hoch" 15 "PLA_beendet_Schiebetuer_offen" 16 "Gegenseite_versperrt" 17 "Parken_n_a_Luecke_zu_klein" 18 "PLA_im_Offroad_Modus_n_a" 21 "AP_Blinker_setzen_u_Softkey_MIB" 22 "Start_Softkey_am_MIB_betaetigen" 23 "RBF_Hindernis_erkannt" 24 "RBF_temp_beendet" 25 "RBF_Gaspedal_loesen" 26 "RBF_Bremse_betaetigen" 27 "RBF_n_a_temp" 28 "RBF_n_a_temp_Anhaenger" 29 "RBF_n_a_temp_Sensorsicht" 30 "RBF_n_a_temp_ESC" 31 "RBF_n_a_temp_Drive_Select" 32 "Einparken_am_MIB_bestaetigen" 40 "info_v_reduzieren" 41 "info_v_begrenzt" 42 "info_Wiederaufnahme" 43 "info_Richtungsw_rueckw" 44 "info_Richtungsw_vorw" 128 "Disclaimer_LP_rechts" 129 "Disclaimer_LP_links" 130 "Disclaimer_RQ_rechts" 131 "Disclaimer_RQ_links" 136 "Disclaimer_VQ_rechts" 137 "Disclaimer_VQ_links" 138 "Disclaimer_AP_rechts" 139 "Disclaimer_AP_links" 144 "Abbruch_Lenkeingriff_Fahrer" 145 "Abbruch_Anhaenger_erkannt" 146 "Abbruch_ESC_deaktiv" 147 "Abbruch_Zeitlimit_ueberschritten" 148 "Lenkeingriff_beendet_uebernehmen" 149 "Abbruch_manuell_parken" 150 "Abbruch_v_zu_hoch" 151 "Abbruch_ESC_ASR_Eingriff" 152 "PLA_beendet_temp_n_a" 153 "PLA_defekt_Werkstatt" 154 "Lenkung_uebernehmen_Fahrt_forts" 155 "Abbr_AP_Luecke_zu_klein" 156 "Bremseingriff_v_zu_hoch" 157 "Abbruch_Hindernis_erkannt" 158 "PLA_Notbremsung_Bremse_betaetige" 159 "PLA_Notbr_Abbruch_Bremse_betaet" 160 "Abbr_Einp_Hindernis_erkannt" 161 "PLA_beendet_Lenkung_uebernehmen" 162 "Abbruch_Offroad_Modus_PLA_n_a" 163 "PLA_Abbruch_Schiebetuer_offen" 164 "Abbr_Luecke_zu_klein" 165 "RBF_temp_n_a" 166 "RBF_Bremse_betaetigen" 167 "Disclaimer_vorwaerts" 168 "RBF_Bitte_uebernehmen" 169 "RBF_Stoerung_Service" 170 "Disclaimer_rueckwaerts" 171 "Abbruch_Fluegeltuer_offen" 172 "Lenkeingriff_Aktiv_Bremsen" ;
VAL_ 1166 PLA_Status_Funktion 0 "PL_Suche" 1 "PL_Suche_Standby" 2 "PL_gefunden" 3 "POS_OK" 4 "Rangieren_vorwaerts" 5 "Rangieren_rueckwaerts" 6 "Disclaimer_in_Anzeige" 7 "Automodus_Wand" 8 "PP_Pos_OK" 11 "GP_Pos_OK" 14 "DP_Pos_OK" ;
VAL_ 1166 PLA_Status_beenden_Mini 0 "Funktion_vorhanden" 1 "Funktion_ausgewaehlt" 2 "Funktion_einparken_moeglich" 3 "Funktion_nicht_vorhanden" ;
VAL_ 1166 PLA_Status_Laengsparken_Mini 0 "Funktion_vorhanden" 1 "Funktion_ausgewaehlt" 2 "Funktion_einparken_moeglich" 3 "Funktion_nicht_vorhanden" ;
VAL_ 1166 PLA_Status_QP_Rueckw_Mini 0 "Funktion_vorhanden" 1 "Funktion_ausgewaehlt" 2 "Funktion_einparken_moeglich" 3 "Funktion_nicht_vorhanden" ;
VAL_ 1166 PLA_Status_QP_Vorw_Mini 0 "Funktion_vorhanden" 1 "Funktion_ausgewaehlt" 2 "Funktion_einparken_moeglich" 3 "Funktion_nicht_vorhanden" ;
VAL_ 1122 PSD_Segment_ID 0 "keine Segmentinformationen vorhanden" 1 "Fehlerwert" ;
VAL_ 1122 PSD_Vorgaenger_Segment_ID 0 "keine Segmentinformation vorhanden" 1 "Fehlerwert" ;
VAL_ 1122 PSD_Strassenkategorie 0 "Rest_Feldweg_Schotterweg_Privatweg" 1 "Ortsstraße" 2 "Kreisstraße" 3 "Landstraße" 4 "Bundesstraße" 5 "Autobahn" 7 "Init" ;
VAL_ 1122 PSD_Endkruemmung 255 "Gerade" ;
VAL_ 1122 PSD_Endkruemmung_Vorz 0 "Kruemmung_positiv" 1 "Kruemmung_negativ" ;
VAL_ 1122 PSD_Idenditaets_ID 0 "keine_Segment_Informationen_vorhanden" 1 "Fehler" ;
VAL_ 1122 PSD_ADAS_Qualitaet 0 "keine_ADAS_Qualitaet" 1 "ADAS_Qualitaet" ;
VAL_ 1122 PSD_wahrscheinlichster_Pfad 0 "Pfad_mit_geringer_Wahrscheinlichkeit" 1 "wahrscheinlichster_Pfad" ;
VAL_ 1122 PSD_Geradester_Pfad 0 "nicht_geradester_PFad" 1 "geradester_Pfad" ;
VAL_ 1122 PSD_Fahrspuren_Anzahl 0 "Einbahnstrasse_in_falsche_Richtung" 1 "eine_Fahrspur" 2 "zwei_Fahrspuren" 3 "drei_Fahrspuren" 4 "vier_Fahrspuren" 5 "fuenf_Fahrspuren" 6 "sechs_Fahrspuren" 7 "mehr_als_sechs_Fahrspuren" ;
VAL_ 1122 PSD_Bebauung 0 "ausserhalb_bebauten_Gebietes" 1 "innerhalb_bebauten_Gebietes" ;
VAL_ 1122 PSD_Segment_Komplett 0 "Segment_Attribute_nicht_komplett" 1 "Segment_Attribute_komplett" ;
VAL_ 1122 PSD_Rampe 0 "Strasse_mit_Gegenverkehr" 1 "Auffahrt_Einbahnstr" 2 "Abfahrt_Einbahnstr" 3 "Einbahnstrasse" ;
VAL_ 1122 PSD_Anfangskruemmung 255 "Gerade" ;
VAL_ 1122 PSD_Anfangskruemmung_Vorz 0 "positiv" 1 "negativ" ;
VAL_ 1122 PSD_Abzweigerichtung 0 "rects_abzweigende_Strasse" 1 "links_abzweigende_Strasse" ;
VAL_ 1123 PSD_Pos_Segment_ID 0 "keine Position gegeben" 1 "Fehlerwert" ;
VAL_ 1123 PSD_Pos_Standort_Eindeutig 0 "mehrdeutiger_Standort" 1 "eindeutiger_Standort" ;
VAL_ 1123 PSD_Pos_Fehler_Laengsrichtung 0 "Init" 1 "< 2m" 2 "< 5m" 3 "< 10m" 4 "< 20m" 5 "< 50m" 6 "> 50m" 7 "Off-Road" ;
VAL_ 1123 PSD_Pos_Fahrspur 0 "unbekannt" 1 "Erste_Spur_von_rechts" 2 "Zweite_Spur_von_rechts" 3 "Dritte_Spur_von_rechts" 4 "Vierte_Spur_von_rechts" 5 "Fuenfte_Spur_von_rechts" 6 "Sechte_Spur_von_rechts" 7 "Siebte_oder_weitere_Spur_von_rechts" ;
VAL_ 1123 PSD_Attribut_Segment_ID_05 0 "keine_Segment_Information" 1 "Fehler" ;
VAL_ 1123 PSD_Attribut_1_ID 0 "keine_Information" ;
VAL_ 1123 PSD_Attribut_2_ID 0 "keine_Information" ;
VAL_ 1123 PSD_Attribute_Komplett_05 0 "Attribute_nicht_komplett" 1 "Attribute_komplett" ;
VAL_ 1124 PSD_06_Mux 0 "Init" ;
VAL_ 1124 PSD_Sys_Segment_ID 0 "keine Segmentinformationen vorhanden" 1 "nicht zulaessig" ;
VAL_ 1124 PSD_Attribut_Segment_ID 0 "keine_Segment_Information_vorhanden" 1 "Fehler" ;
VAL_ 1124 PSD_Ges_Segment_ID 0 "keine Segmentinformationen vorhanden" 1 "nicht zulaessig" ;
VAL_ 1124 PSD_Baum_Laenge_VZ 0 "Ost" 1 "West" ;
VAL_ 1124 PSD_Steigung_1_Segment_ID 0 "keine_Segment_Information_vorhanden" 1 "Fehler" ;
VAL_ 1124 PSD_Baum_Laenge 33554431 "keine_GPS_Information" ;
VAL_ 1124 PSD_Attribut_3_ID 0 "keine_Information" ;
VAL_ 1124 PSD_Steigung_1_A_Steigung 126 "mehr_als_15_Prozent" 127 "Steigung_unbekannt" ;
VAL_ 1124 PSD_Ges_Geschwindigkeit 0 "Kein Geschwindigkeitsgebot" 1 "0 km/h < v_max <  5 km/h" 2 "5 km/h < v_max < 10km/h" 3 "10 km/h < v_max < 15 km/h" 4 "15 km/h < v_max < 20 km/h" 5 "20 km/h < v_max < 25 km/h" 6 "25 km/h < v_max < 30 km/h" 7 "30 km/h < v_max < 35 km/h" 8 "35 km/h < v_max < 40 km/h" 9 "40 km/h < v_max < 45 km/h" 10 "45 km/h < v_max < 50 km/h" 11 "50 km/h < v_max < 60 km/h" 12 "60 km/h < v_max < 70 km/h" 13 "70 km/h < v_max < 80 km/h" 14 "80 km/h < v_max < 90 km/h" 15 "90 km/h < v_max < 100 km/h" 16 "100 km/h < v_max < 110 km/h" 17 "110 km/h < v_max < 120 km/h" 18 " 120 km/h < v_max < 130 km/h" 19 "130 km/h < v_max < 140 km/h" 20 "140 km/h < v_max < 150 km/h" 21 "150 km/h < v_max < 160 km/h" 22 "160 km/h < v_max" 23 "Geschwindigkeitsgebot aufgehoben" 24 "..0x1F ungültig" ;
VAL_ 1124 PSD_Steigung_1_A_Vorz 0 "Gefaelle" 1 "Steigung" ;
VAL_ 1124 PSD_Sys_Geschwindigkeit_Einheit 0 "km/h" 1 "mph" ;
VAL_ 1124 PSD_Sys_Verkehrsrichtung 0 "Rechtsverkehr" 1 "Linksverkehr" ;
VAL_ 1124 PSD_Sys_Geometrieguete 0 "Geringe_Guete" 1 "tbd" 2 "tbd" 3 "Hohe_Guete" ;
VAL_ 1124 PSD_Sys_Mapmatchingguete 0 "geringe_Guete" 1 "res" 2 "res" 3 "hohe_Guete" ;
VAL_ 1124 PSD_Ges_Typ 0 "Geschw_Klasse_des_Kartendatensuppliers" 1 "Explizit_abgeleiteten_Begrenzung" 2 "Durch_Gesetzg_vorgeg_allgem_Gebot_fuer_uebertr_Rahmenbed" 3 "Init" ;
VAL_ 1124 PSD_Sys_Alter_Karte 0 "kleiner_1_Jahr" 1 "1_Jahr" 2 "2_Jahre" 3 "3_Jahre" 4 "4_Jahre" 5 "5_Jahre" 6 "6_Jahre" 7 "groesser_7_Jahre" ;
VAL_ 1124 PSD_Ges_Spur_Geschw_Begrenzung 0 "Gebot_fuer_alle_spuren_gueltig" ;
VAL_ 1124 PSD_Steigung_1_B_Steigung 126 "mehr_als_15_Prozent" 127 "Steigung_unbekannt" ;
VAL_ 1124 PSD_Attribut_4_ID 0 "keine_Information" ;
VAL_ 1124 PSD_Sys_Zielfuehrung 0 "Zielfuehrung nicht aktiv" 1 "Zielfuehrung aktiv" ;
VAL_ 1124 PSD_Sys_US_State 0 "kein_US_State" 1 "Alabama" 2 "Alaska" 3 "Arkansas" 4 "Arizona" 5 "California" 6 "Colorado" 7 "Conneticut" 8 "District_of_Columbia" 9 "Delaware" 10 "Florida" 11 "Georgia" 12 "Hawaii" 13 "Idaho" 14 "Illinois" 15 "Iowa" 16 "Indiana" 17 "Kansas" 18 "Kentucky" 19 "Louisiana" 20 "Massachusetts" 21 "Maryland" 22 "Maine" 23 "Michigan" 24 "Minnesota" 25 "Missouri" 26 "Mississippi" 27 "Montana" 28 "North_Carolina" 29 "North_Dakota" 30 "Nebraska" 31 "Nevada" 32 "New_Hampshire" 33 "New_Jersey" 34 "New_Mexico" 35 "New_York" 36 "Ohio" 37 "Oklahoma" 38 "Oregon" 39 "Pennsylvania" 40 "Puerto_Rico" 41 "Rhode_Island" 42 "South_Carolina" 43 "South_Dakota" 44 "Tennessee" 45 "Texas" 46 "Utah" 47 "Virginia" 48 "Virgin_Islands" 49 "Vermont" 50 "Washington" 51 "Wisconsin" 52 "West_Virginia" 53 "Wyoming" ;
VAL_ 1124 PSD_Ges_Geschwindigkeit_Gespann 0 "alle Fahrzeuge" 1 "PKW mit Gespann" 2 "LKW, Busse, etc." ;
VAL_ 1124 PSD_Baum_Breite_VZ 0 "Nord" 1 "Sued" ;
VAL_ 1124 PSD_Ges_Geschwindigkeit_Witter 0 "Witterungsunabhängig" 1 "Nässe, Regen, Niederschlag" 2 "Glätte" 3 "Nebel" ;
VAL_ 1124 PSD_Steigung_1_B_Vorz 0 "Gefaelle" 1 "Steigung" ;
VAL_ 1124 PSD_Ges_Geschwindigkeit_Tag_Anf 0 "kein Beginn definiert" 1 "Montag" 2 "Dienstag" 3 "Mittwoch" 4 "Donnerstag" 5 "Freitag" 6 "Samstag" 7 "Sonntag" ;
VAL_ 1124 PSD_Ges_Geschwindigkeit_Tag_Ende 0 "kein Ende definiert" 1 "Montag" 2 "Dienstag" 3 "Mittwoch" 4 "Donnerstag" 5 "Freitag" 6 "Samstag" 7 "Sonntag" ;
VAL_ 1124 PSD_Sys_Quali_verfuegbar 0 "Qualitaetskriterien_nicht_verfuegbar" 1 "Qualitaetskriterien_verfuegbar" ;
VAL_ 1124 PSD_Sys_Zielfuehrung_geaendert 0 "Zielfuehrung_nicht_geaendert" 1 "Zielfuehrung_geaendert" ;
VAL_ 1124 PSD_Ges_Geschwindigkeit_Std_Anf 25 "kein Beginn für stundenweise Einschränkungen" ;
VAL_ 1124 PSD_Steigung_1_Attribute_kompl 0 "Steigungen_nicht_komplett" 1 "Steigungen_komplett" ;
VAL_ 1124 PSD_Sys_Geometrieguete_erweitert 0 "Init" ;
VAL_ 1124 PSD_Steigung_2_Segment_ID 0 "keine_Segment_Information_vorhanden" 1 "Fehler" ;
VAL_ 1124 PSD_Attribut_5_ID 0 "keine_Information" ;
VAL_ 1124 PSD_Ges_Geschwindigkeit_Std_Ende 25 "kein Ende für stundenweise Einschränkungen" ;
VAL_ 1124 PSD_Steigung_2_Steigung 126 "mehr_als_15_Prozent" 127 "Steigung_unbekannt" ;
VAL_ 1124 PSD_Ges_Ueberholverbot 0 "kein Überholverbot" 1 "alle Fahrzeuge" 2 "Überholverbot für PKW mit Gespann" 3 "Überholverbot für LKW, Busse, etc." ;
VAL_ 1124 PSD_Ges_Wechselverkehrszeichen 0 "Kein Wechselverkehrszeichen" 1 "Wechselverkehrszeichen links" 2 "Wechselverkehrszeichen rechts" 3 "Wechselverkehrszeichen links und rechts" 4 "Wechselverkerhszeichen über der Fahrbahn" ;
VAL_ 1124 PSD_Steigung_2_Vorz 0 "Gefaelle" 1 "Steigung" ;
VAL_ 1124 PSD_Wechselverkehrszeichen_Typ 0 "kein_Wechselverkehrszeichen" 1 "LED_Wechselverkehrszeichen" 2 "nicht_LED_Wechselverkehrszeichen" ;
VAL_ 1124 PSD_Ges_Gesetzlich_Kategorie 0 "kein_legales_Verbot" 1 "innerorts" 2 "ausserorts" 3 "Autobahn" ;
VAL_ 1124 PSD_Attribute_Komplett_06 0 "Attribute_nicht_komplett" 1 "Attribute_komplett" ;
VAL_ 1124 PSD_Ges_Gesetzlich_Zusatz 0 "kein_Zusatz_zu_legalem_Gebot" 1 "Anhaenger_Klasse_1" 2 "Anhaenger_Klasse_2" ;
VAL_ 1124 PSD_Ges_Verkehrszeichen_Quelle 0 "VZA_kein_Onlinedienst" 1 "nur_VZA" 2 "nur_VZO" 3 "VZA_und_VZO" ;
VAL_ 1124 PSD_Steigung_2_Attribute_kompl 0 "Steigungen_nicht_komplett" 1 "Steigungen_komplett" ;
VAL_ 1124 PSD_Ges_Attribute_Komplett 0 "Attribute_nicht_komplett" 1 "Attribute_komplett" ;
